VERSION "dbc-export 1 2025.20.8"

NS_ :

BS_:

BU_: ADSP APB APP APS APSB BB BMS CC CMP CMPD CP DAS DI DIF DIR DPB EPAS3P EPAS3S EPASTP EPASTS EPBL EPBR ESP EVSE FC GTW HCML HCMR HVP IBST ICR IDB LS OCS1P PARK PCS PM PMF PMR PNCD PTC RADC RCM RCM2 RCM3 RCU SCCM SCM SCS SDCR TAS TCU TPMS TRCM UI UIS UMC USM VC VCFRONT VCLEFT VCRIGHT VCSEC VEH

BO_ 886 DIF_temperature: 8 DIF
 SG_ DIF_tempIndex M : 0|3@1+ (1,0) [0|7] "" Vector__XXX
 SG_ DIF_inverterTQF m0 : 3|2@1+ (1,0) [0|3] "" Vector__XXX
 SG_ DIF_pcbT m0 : 8|8@1+ (1,-40) [-40|215] "DegC" Vector__XXX
 SG_ DIF_inverterT m0 : 16|8@1+ (1,-40) [-40|215] "DegC" Vector__XXX
 SG_ DIF_statorT m0 : 24|8@1+ (1,-40) [-40|215] "DegC" Vector__XXX
 SG_ DIF_dcCapT m0 : 32|8@1+ (1,-40) [-40|215] "DegC" Vector__XXX
 SG_ DIF_heatsinkT m0 : 40|8@1+ (1,-40) [-40|215] "DegC" Vector__XXX
 SG_ DIF_inverterTpct m0 : 48|8@1+ (0.4,0) [0|100] "%" Vector__XXX
 SG_ DIF_statorTpct m0 : 56|8@1+ (0.4,0) [0|100] "%" Vector__XXX
 SG_ DIF_fluidInTemp m2 : 8|8@1+ (1,-40) [-40|215] "DegC" Vector__XXX
 SG_ DIF_normalFetBurnIn m2 : 16|16@1+ (0.00763,0) [0|500] "Hours" Vector__XXX
 SG_ DIF_additionalFetBurnIn m2 : 32|16@1+ (0.00763,0) [0|500] "Hours" Vector__XXX
 SG_ DIF_currentWeibullMiles m3 : 3|16@1+ (8,0) [0|500000] "miles" Vector__XXX
 SG_ DIF_endOfServiceWeibullMiles m3 : 19|16@1+ (8,0) [0|500000] "miles" Vector__XXX
 SG_ DIF_burnInDamageRatio m3 : 35|9@1+ (0.01,0) [0|5] "1" Vector__XXX
 SG_ DIF_inverterSensorEst m3 : 44|8@1+ (1,-40) [-40|120] "C" Vector__XXX
 SG_ DIF_inverterHS1Est m3 : 52|8@1+ (1,-40) [-40|120] "C" Vector__XXX
 SG_ DIF_initialBurnInVehicleOdometer m4 : 8|32@1+ (0.001,0) [0|4294967.294] "km" Vector__XXX
 SG_ DIF_inverterHS2Est m4 : 40|8@1+ (1,-40) [-40|120] "C" Vector__XXX
 SG_ DIF_inverterInletEst m4 : 48|8@1+ (1,-40) [-40|120] "C" Vector__XXX

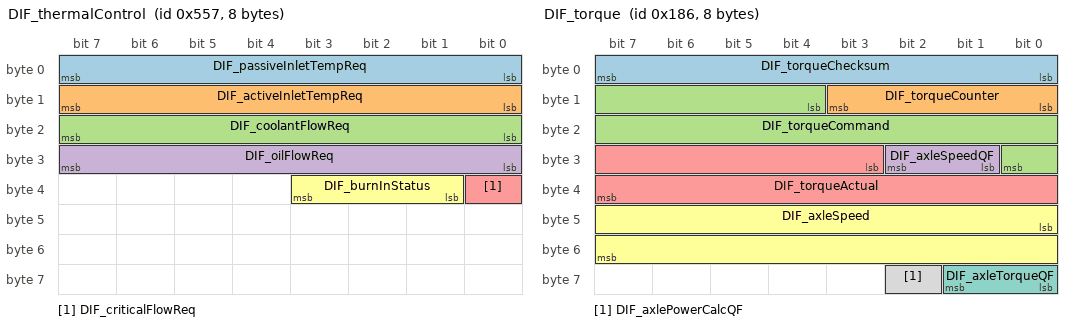
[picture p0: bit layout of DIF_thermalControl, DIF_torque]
BO_ 1367 DIF_thermalControl: 8 DIF
 SG_ DIF_passiveInletTempReq : 0|8@1+ (1,-40) [-40|215] "DegC" Vector__XXX
 SG_ DIF_activeInletTempReq : 8|8@1+ (1,-40) [-40|215] "DegC" Vector__XXX
 SG_ DIF_coolantFlowReq : 16|8@1+ (0.2,0) [0|50] "LPM" Vector__XXX
 SG_ DIF_oilFlowReq : 24|8@1+ (0.1,0) [0|25.4] "LPM" Vector__XXX
 SG_ DIF_criticalFlowReq : 32|1@1+ (1,0) [0|1] "" Vector__XXX
 SG_ DIF_burnInStatus : 33|3@1+ (1,0) [0|7] "" Vector__XXX

BO_ 390 DIF_torque: 8 DIF
 SG_ DIF_torqueChecksum : 0|8@1+ (1,0) [0|255] "" Vector__XXX
 SG_ DIF_torqueCounter : 8|4@1+ (1,0) [0|15] "" Vector__XXX
 SG_ DIF_torqueCommand : 12|13@1- (2,0) [-7500|7500] "Nm" Vector__XXX
 SG_ DIF_axleSpeedQF : 25|2@1+ (1,0) [0|3] "" Vector__XXX
 SG_ DIF_torqueActual : 27|13@1- (2,0) [-7500|7500] "Nm" Vector__XXX
 SG_ DIF_axleSpeed : 40|16@1- (0.1,0) [-2750|2750] "RPM" Vector__XXX
 SG_ DIF_axleTorqueQF : 56|2@1+ (1,0) [0|3] "" Vector__XXX
 SG_ DIF_axlePowerCalcQF : 58|1@1+ (1,0) [0|1] "" Vector__XXX

BO_ 1445 DIR_alertLog: 8 DIR
 SG_ DIR_alertID M : 0|8@1+ (1,0) [0|255] "" Vector__XXX
 SG_ DIR_alertState : 15|1@1+ (1,0) [0|1] "" Vector__XXX
 SG_ DIR_a001_thermalWarning_H m1 : 16|1@1+ (1,0) [0|1] "" Vector__XXX
 SG_ DIR_a001_thermalShutdown_H m1 : 17|1@1+ (1,0) [0|1] "" Vector__XXX
 SG_ DIR_a001_undervoltVL_H m1 : 18|1@1+ (1,0) [0|1] "" Vector__XXX
 SG_ DIR_a001_undervoltVH_H m1 : 19|1@1+ (1,0) [0|1] "" Vector__XXX
 SG_ DIR_a001_sense_H m1 : 20|1@1+ (1,0) [0|1] "" Vector__XXX
 SG_ DIR_a001_desat_H m1 : 21|1@1+ (1,0) [0|1] "" Vector__XXX
 SG_ DIR_a001_overvoltVL_H m1 : 22|1@1+ (1,0) [0|1] "" Vector__XXX
 SG_ DIR_a001_overvoltVH_H m1 : 23|1@1+ (1,0) [0|1] "" Vector__XXX
 SG_ DIR_a001_undervoltVCC_H m1 : 24|1@1+ (1,0) [0|1] "" Vector__XXX
 SG_ DIR_a001_asynchStop_H m1 : 25|1@1+ (1,0) [0|1] "" Vector__XXX
 SG_ DIR_a001_remoteRegError_H m1 : 26|1@1+ (1,0) [0|1] "" Vector__XXX
 SG_ DIR_a001_undervoltVDD_H m1 : 27|1@1+ (1,0) [0|1] "" Vector__XXX
 SG_ DIR_a001_overvoltVDD_H m1 : 28|1@1+ (1,0) [0|1] "" Vector__XXX
 SG_ DIR_a001_localRegError_H m1 : 29|1@1+ (1,0) [0|1] "" Vector__XXX
 SG_ DIR_a001_spiError_H m1 : 30|1@1+ (1,0) [0|1] "" Vector__XXX
 SG_ DIR_a001_deadtimeError_H m1 : 31|1@1+ (1,0) [0|1] "" Vector__XXX
 SG_ DIR_a001_thermalWarning_L m1 : 32|1@1+ (1,0) [0|1] "" Vector__XXX
 SG_ DIR_a001_thermalShutdown_L m1 : 33|1@1+ (1,0) [0|1] "" Vector__XXX
 SG_ DIR_a001_undervoltVL_L m1 : 34|1@1+ (1,0) [0|1] "" Vector__XXX
 SG_ DIR_a001_undervoltVH_L m1 : 35|1@1+ (1,0) [0|1] "" Vector__XXX
 SG_ DIR_a001_sense_L m1 : 36|1@1+ (1,0) [0|1] "" Vector__XXX
 SG_ DIR_a001_desat_L m1 : 37|1@1+ (1,0) [0|1] "" Vector__XXX
 SG_ DIR_a001_overvoltVL_L m1 : 38|1@1+ (1,0) [0|1] "" Vector__XXX
 SG_ DIR_a001_overvoltVH_L m1 : 39|1@1+ (1,0) [0|1] "" Vector__XXX
 SG_ DIR_a001_undervoltVCC_L m1 : 40|1@1+ (1,0) [0|1] "" Vector__XXX
 SG_ DIR_a001_asynchStop_L m1 : 41|1@1+ (1,0) [0|1] "" Vector__XXX
 SG_ DIR_a001_remoteRegError_L m1 : 42|1@1+ (1,0) [0|1] "" Vector__XXX
 SG_ DIR_a001_undervoltVDD_L m1 : 43|1@1+ (1,0) [0|1] "" Vector__XXX
 SG_ DIR_a001_overvoltVDD_L m1 : 44|1@1+ (1,0) [0|1] "" Vector__XXX
 SG_ DIR_a001_localRegError_L m1 : 45|1@1+ (1,0) [0|1] "" Vector__XXX
 SG_ DIR_a001_spiError_L m1 : 46|1@1+ (1,0) [0|1] "" Vector__XXX
 SG_ DIR_a001_deadtimeError_L m1 : 47|1@1+ (1,0) [0|1] "" Vector__XXX
 SG_ DIR_a001_gateDriveErrCounter m1 : 48|4@1+ (1,0) [0|15] "" Vector__XXX
 SG_ DIR_a001_remoteCommError_H m1 : 52|1@1+ (1,0) [0|1] "" Vector__XXX
 SG_ DIR_a001_localCommError_H m1 : 53|1@1+ (1,0) [0|1] "" Vector__XXX
 SG_ DIR_a001_remoteReset_H m1 : 54|1@1+ (1,0) [0|1] "" Vector__XXX
 SG_ DIR_a001_localReset_H m1 : 55|1@1+ (1,0) [0|1] "" Vector__XXX
 SG_ DIR_a001_remoteCommError_L m1 : 56|1@1+ (1,0) [0|1] "" Vector__XXX
 SG_ DIR_a001_localCommError_L m1 : 57|1@1+ (1,0) [0|1] "" Vector__XXX
 SG_ DIR_a001_remoteReset_L m1 : 58|1@1+ (1,0) [0|1] "" Vector__XXX
 SG_ DIR_a001_localReset_L m1 : 59|1@1+ (1,0) [0|1] "" Vector__XXX
 SG_ DIR_a001_faultLine1Gpio_H m1 : 60|1@1+ (1,0) [0|1] "" Vector__XXX
 SG_ DIR_a001_faultLine1Gpio_L m1 : 61|1@1+ (1,0) [0|1] "" Vector__XXX
 SG_ DIR_a002_thermalWarning_H m2 : 16|1@1+ (1,0) [0|1] "" Vector__XXX
 SG_ DIR_a002_thermalShutdown_H m2 : 17|1@1+ (1,0) [0|1] "" Vector__XXX
 SG_ DIR_a002_undervoltVL_H m2 : 18|1@1+ (1,0) [0|1] "" Vector__XXX
 SG_ DIR_a002_undervoltVH_H m2 : 19|1@1+ (1,0) [0|1] "" Vector__XXX
 SG_ DIR_a002_sense_H m2 : 20|1@1+ (1,0) [0|1] "" Vector__XXX
 SG_ DIR_a002_desat_H m2 : 21|1@1+ (1,0) [0|1] "" Vector__XXX
 SG_ DIR_a002_overvoltVL_H m2 : 22|1@1+ (1,0) [0|1] "" Vector__XXX
 SG_ DIR_a002_overvoltVH_H m2 : 23|1@1+ (1,0) [0|1] "" Vector__XXX
 SG_ DIR_a002_undervoltVCC_H m2 : 24|1@1+ (1,0) [0|1] "" Vector__XXX
 SG_ DIR_a002_asynchStop_H m2 : 25|1@1+ (1,0) [0|1] "" Vector__XXX
 SG_ DIR_a002_remoteRegError_H m2 : 26|1@1+ (1,0) [0|1] "" Vector__XXX
 SG_ DIR_a002_undervoltVDD_H m2 : 27|1@1+ (1,0) [0|1] "" Vector__XXX
 SG_ DIR_a002_overvoltVDD_H m2 : 28|1@1+ (1,0) [0|1] "" Vector__XXX
 SG_ DIR_a002_localRegError_H m2 : 29|1@1+ (1,0) [0|1] "" Vector__XXX
 SG_ DIR_a002_spiError_H m2 : 30|1@1+ (1,0) [0|1] "" Vector__XXX
 SG_ DIR_a002_deadtimeError_H m2 : 31|1@1+ (1,0) [0|1] "" Vector__XXX
 SG_ DIR_a002_thermalWarning_L m2 : 32|1@1+ (1,0) [0|1] "" Vector__XXX
 SG_ DIR_a002_thermalShutdown_L m2 : 33|1@1+ (1,0) [0|1] "" Vector__XXX
 SG_ DIR_a002_undervoltVL_L m2 : 34|1@1+ (1,0) [0|1] "" Vector__XXX
 SG_ DIR_a002_undervoltVH_L m2 : 35|1@1+ (1,0) [0|1] "" Vector__XXX
 SG_ DIR_a002_sense_L m2 : 36|1@1+ (1,0) [0|1] "" Vector__XXX
 SG_ DIR_a002_desat_L m2 : 37|1@1+ (1,0) [0|1] "" Vector__XXX
 SG_ DIR_a002_overvoltVL_L m2 : 38|1@1+ (1,0) [0|1] "" Vector__XXX
 SG_ DIR_a002_overvoltVH_L m2 : 39|1@1+ (1,0) [0|1] "" Vector__XXX
 SG_ DIR_a002_undervoltVCC_L m2 : 40|1@1+ (1,0) [0|1] "" Vector__XXX
 SG_ DIR_a002_asynchStop_L m2 : 41|1@1+ (1,0) [0|1] "" Vector__XXX
 SG_ DIR_a002_remoteRegError_L m2 : 42|1@1+ (1,0) [0|1] "" Vector__XXX
 SG_ DIR_a002_undervoltVDD_L m2 : 43|1@1+ (1,0) [0|1] "" Vector__XXX
 SG_ DIR_a002_overvoltVDD_L m2 : 44|1@1+ (1,0) [0|1] "" Vector__XXX
 SG_ DIR_a002_localRegError_L m2 : 45|1@1+ (1,0) [0|1] "" Vector__XXX
 SG_ DIR_a002_spiError_L m2 : 46|1@1+ (1,0) [0|1] "" Vector__XXX
 SG_ DIR_a002_deadtimeError_L m2 : 47|1@1+ (1,0) [0|1] "" Vector__XXX
 SG_ DIR_a002_gateDriveErrCounter m2 : 48|4@1+ (1,0) [0|15] "" Vector__XXX
 SG_ DIR_a002_selftestDesat_L m2 : 52|1@1+ (1,0) [0|1] "" Vector__XXX
 SG_ DIR_a002_selftestDesat_H m2 : 53|1@1+ (1,0) [0|1] "" Vector__XXX
 SG_ DIR_a002_remoteCommError_H m2 : 54|1@1+ (1,0) [0|1] "" Vector__XXX
 SG_ DIR_a002_localCommError_H m2 : 55|1@1+ (1,0) [0|1] "" Vector__XXX
 SG_ DIR_a002_remoteReset_H m2 : 56|1@1+ (1,0) [0|1] "" Vector__XXX
 SG_ DIR_a002_localReset_H m2 : 57|1@1+ (1,0) [0|1] "" Vector__XXX
 SG_ DIR_a002_remoteCommError_L m2 : 58|1@1+ (1,0) [0|1] "" Vector__XXX
 SG_ DIR_a002_localCommError_L m2 : 59|1@1+ (1,0) [0|1] "" Vector__XXX
 SG_ DIR_a002_remoteReset_L m2 : 60|1@1+ (1,0) [0|1] "" Vector__XXX
 SG_ DIR_a002_localReset_L m2 : 61|1@1+ (1,0) [0|1] "" Vector__XXX
 SG_ DIR_a002_faultLine1Gpio_H m2 : 62|1@1+ (1,0) [0|1] "" Vector__XXX
 SG_ DIR_a002_faultLine1Gpio_L m2 : 63|1@1+ (1,0) [0|1] "" Vector__XXX
 SG_ DIR_a003_thermalWarning_H m3 : 16|1@1+ (1,0) [0|1] "" Vector__XXX
 SG_ DIR_a003_thermalShutdown_H m3 : 17|1@1+ (1,0) [0|1] "" Vector__XXX
 SG_ DIR_a003_undervoltVL_H m3 : 18|1@1+ (1,0) [0|1] "" Vector__XXX
 SG_ DIR_a003_undervoltVH_H m3 : 19|1@1+ (1,0) [0|1] "" Vector__XXX
 SG_ DIR_a003_sense_H m3 : 20|1@1+ (1,0) [0|1] "" Vector__XXX
 SG_ DIR_a003_desat_H m3 : 21|1@1+ (1,0) [0|1] "" Vector__XXX
 SG_ DIR_a003_overvoltVL_H m3 : 22|1@1+ (1,0) [0|1] "" Vector__XXX
 SG_ DIR_a003_overvoltVH_H m3 : 23|1@1+ (1,0) [0|1] "" Vector__XXX
 SG_ DIR_a003_undervoltVCC_H m3 : 24|1@1+ (1,0) [0|1] "" Vector__XXX
 SG_ DIR_a003_asynchStop_H m3 : 25|1@1+ (1,0) [0|1] "" Vector__XXX
 SG_ DIR_a003_remoteRegError_H m3 : 26|1@1+ (1,0) [0|1] "" Vector__XXX
 SG_ DIR_a003_undervoltVDD_H m3 : 27|1@1+ (1,0) [0|1] "" Vector__XXX
 SG_ DIR_a003_overvoltVDD_H m3 : 28|1@1+ (1,0) [0|1] "" Vector__XXX
 SG_ DIR_a003_localRegError_H m3 : 29|1@1+ (1,0) [0|1] "" Vector__XXX
 SG_ DIR_a003_spiError_H m3 : 30|1@1+ (1,0) [0|1] "" Vector__XXX
 SG_ DIR_a003_deadtimeError_H m3 : 31|1@1+ (1,0) [0|1] "" Vector__XXX
 SG_ DIR_a003_thermalWarning_L m3 : 32|1@1+ (1,0) [0|1] "" Vector__XXX
 SG_ DIR_a003_thermalShutdown_L m3 : 33|1@1+ (1,0) [0|1] "" Vector__XXX
 SG_ DIR_a003_undervoltVL_L m3 : 34|1@1+ (1,0) [0|1] "" Vector__XXX
 SG_ DIR_a003_undervoltVH_L m3 : 35|1@1+ (1,0) [0|1] "" Vector__XXX
 SG_ DIR_a003_sense_L m3 : 36|1@1+ (1,0) [0|1] "" Vector__XXX
 SG_ DIR_a003_desat_L m3 : 37|1@1+ (1,0) [0|1] "" Vector__XXX
 SG_ DIR_a003_overvoltVL_L m3 : 38|1@1+ (1,0) [0|1] "" Vector__XXX
 SG_ DIR_a003_overvoltVH_L m3 : 39|1@1+ (1,0) [0|1] "" Vector__XXX
 SG_ DIR_a003_undervoltVCC_L m3 : 40|1@1+ (1,0) [0|1] "" Vector__XXX
 SG_ DIR_a003_asynchStop_L m3 : 41|1@1+ (1,0) [0|1] "" Vector__XXX
 SG_ DIR_a003_remoteRegError_L m3 : 42|1@1+ (1,0) [0|1] "" Vector__XXX
 SG_ DIR_a003_undervoltVDD_L m3 : 43|1@1+ (1,0) [0|1] "" Vector__XXX
 SG_ DIR_a003_overvoltVDD_L m3 : 44|1@1+ (1,0) [0|1] "" Vector__XXX
 SG_ DIR_a003_localRegError_L m3 : 45|1@1+ (1,0) [0|1] "" Vector__XXX
 SG_ DIR_a003_spiError_L m3 : 46|1@1+ (1,0) [0|1] "" Vector__XXX
 SG_ DIR_a003_deadtimeError_L m3 : 47|1@1+ (1,0) [0|1] "" Vector__XXX
 SG_ DIR_a003_gateDriveErrCounter m3 : 48|4@1+ (1,0) [0|15] "" Vector__XXX
 SG_ DIR_a003_selftestDesat_L m3 : 52|1@1+ (1,0) [0|1] "" Vector__XXX
 SG_ DIR_a003_selftestDesat_H m3 : 53|1@1+ (1,0) [0|1] "" Vector__XXX
 SG_ DIR_a003_remoteCommError_H m3 : 54|1@1+ (1,0) [0|1] "" Vector__XXX
 SG_ DIR_a003_localCommError_H m3 : 55|1@1+ (1,0) [0|1] "" Vector__XXX
 SG_ DIR_a003_remoteReset_H m3 : 56|1@1+ (1,0) [0|1] "" Vector__XXX
 SG_ DIR_a003_localReset_H m3 : 57|1@1+ (1,0) [0|1] "" Vector__XXX
 SG_ DIR_a003_remoteCommError_L m3 : 58|1@1+ (1,0) [0|1] "" Vector__XXX
 SG_ DIR_a003_localCommError_L m3 : 59|1@1+ (1,0) [0|1] "" Vector__XXX
 SG_ DIR_a003_remoteReset_L m3 : 60|1@1+ (1,0) [0|1] "" Vector__XXX
 SG_ DIR_a003_localReset_L m3 : 61|1@1+ (1,0) [0|1] "" Vector__XXX
 SG_ DIR_a003_faultLine1Gpio_H m3 : 62|1@1+ (1,0) [0|1] "" Vector__XXX
 SG_ DIR_a003_faultLine1Gpio_L m3 : 63|1@1+ (1,0) [0|1] "" Vector__XXX
 SG_ DIR_a007_phaseAcurrent m7 : 16|8@1+ (8,0) [0|2040] "" Vector__XXX
 SG_ DIR_a007_phaseBcurrent m7 : 24|8@1+ (8,0) [0|2040] "" Vector__XXX
 SG_ DIR_a007_offsetError m7 : 32|14@1- (0.0003834952,0) [-3.1415926784|3.1412091832] "" Vector__XXX
 SG_ DIR_a007_idFdbStdDeviation m7 : 46|8@1+ (4,0) [0|1020] "" Vector__XXX
 SG_ DIR_a007_iqFdbStdDeviation m7 : 54|8@1+ (4,0) [0|1020] "" Vector__XXX
 SG_ DIR_a007_motorShift m7 : 62|1@1+ (1,0) [0|1] "" Vector__XXX
 SG_ DIR_a007_motorShort m7 : 63|1@1+ (1,0) [0|1] "" Vector__XXX
 SG_ DIR_a010_sccReset m10 : 16|1@1+ (1,0) [0|1] "" Vector__XXX
 SG_ DIR_a010_hibernate m10 : 17|1@1+ (1,0) [0|1] "" Vector__XXX
 SG_ DIR_a010_hwBist m10 : 18|1@1+ (1,0) [0|1] "" Vector__XXX
 SG_ DIR_a010_nmiWatchdog m10 : 19|1@1+ (1,0) [0|1] "" Vector__XXX
 SG_ DIR_a010_watchdog m10 : 20|1@1+ (1,0) [0|1] "" Vector__XXX
 SG_ DIR_a010_clockFailNmi m10 : 21|1@1+ (1,0) [0|1] "" Vector__XXX
 SG_ DIR_a010_ramUncErrorNmi m10 : 22|1@1+ (1,0) [0|1] "" Vector__XXX
 SG_ DIR_a010_flashUncErrorNmi m10 : 23|1@1+ (1,0) [0|1] "" Vector__XXX
 SG_ DIR_a010_cpu1signMismatchNmi m10 : 24|1@1+ (1,0) [0|1] "" Vector__XXX
 SG_ DIR_a010_cpu2signMismatchNmi m10 : 25|1@1+ (1,0) [0|1] "" Vector__XXX
 SG_ DIR_a010_pieVectErrorNmi m10 : 26|1@1+ (1,0) [0|1] "" Vector__XXX
 SG_ DIR_a010_sysDbgNmi m10 : 27|1@1+ (1,0) [0|1] "" Vector__XXX
 SG_ DIR_a010_rlNmi m10 : 28|1@1+ (1,0) [0|1] "" Vector__XXX
 SG_ DIR_a010_ovfNmi m10 : 29|1@1+ (1,0) [0|1] "" Vector__XXX
 SG_ DIR_a010_wdtFlags m10 : 32|16@1+ (1,0) [0|65535] "" Vector__XXX
 SG_ DIR_a011_reason m11 : 16|3@1+ (1,0) [0|7] "" Vector__XXX
 SG_ DIR_a011_phaseAHigh m11 : 19|1@1+ (1,0) [0|1] "" Vector__XXX
 SG_ DIR_a011_phaseALow m11 : 20|1@1+ (1,0) [0|1] "" Vector__XXX
 SG_ DIR_a011_phaseBHigh m11 : 21|1@1+ (1,0) [0|1] "" Vector__XXX
 SG_ DIR_a011_phaseBLow m11 : 22|1@1+ (1,0) [0|1] "" Vector__XXX
 SG_ DIR_a011_phaseCHigh m11 : 23|1@1+ (1,0) [0|1] "" Vector__XXX
 SG_ DIR_a011_phaseCLow m11 : 24|1@1+ (1,0) [0|1] "" Vector__XXX
 SG_ DIR_a011_regAddress m11 : 25|5@1+ (1,0) [0|31] "" Vector__XXX
 SG_ DIR_a011_badGateDriveIC m11 : 32|3@1+ (1,0) [0|7] "" Vector__XXX
 SG_ DIR_a011_badDataRead m11 : 40|8@1+ (1,0) [0|255] "" Vector__XXX
 SG_ DIR_a011_badDataExpected m11 : 48|8@1+ (1,0) [0|255] "" Vector__XXX
 SG_ DIR_a011_codeBranch m11 : 56|4@1+ (1,0) [0|15] "" Vector__XXX
 SG_ DIR_a012_hvilStatus m12 : 16|2@1+ (1,0) [0|3] "" Vector__XXX
 SG_ DIR_a012_hvilCmVoltage m12 : 24|8@1+ (0.08,0) [0|20.4] "" Vector__XXX
 SG_ DIR_a012_hvilCurrent m12 : 32|8@1+ (0.1,0) [0|25.5] "" Vector__XXX
 SG_ DIR_a012_hvilFaultGpio m12 : 40|1@1+ (1,0) [0|1] "" Vector__XXX
 SG_ DIR_a012_hvilSupplyPinDI m12 : 41|1@1+ (1,0) [0|1] "" Vector__XXX
 SG_ DIR_a012_hvilSupplyPinPM m12 : 42|1@1+ (1,0) [0|1] "" Vector__XXX
 SG_ DIR_a012_activeDisOn3V3 m12 : 43|1@1+ (1,0) [0|1] "" Vector__XXX
 SG_ DIR_a012_hvilHeaderFault m12 : 44|1@1+ (1,0) [0|1] "" Vector__XXX
 SG_ DIR_a013_address m13 : 16|32@1+ (1,0) [0|4294967295] "" Vector__XXX
 SG_ DIR_a013_errorType m13 : 48|4@1+ (1,0) [0|15] "" Vector__XXX
 SG_ DIR_a014_motorSpeed m14 : 16|14@1- (2,0) [-16384|16382] "" Vector__XXX
 SG_ DIR_a014_adState m14 : 30|2@1+ (1,0) [0|3] "" Vector__XXX
 SG_ DIR_a014_torqueCommandFwd m14 : 32|10@1- (2,0) [-1024|1022] "" Vector__XXX
 SG_ DIR_a014_brakeMasterCylPress m14 : 42|10@1+ (0.25,-42.5) [-42.5|213.25] "" Vector__XXX
 SG_ DIR_a014_rmsTorqueError m14 : 52|10@1+ (1,0) [0|1023] "" Vector__XXX
 SG_ DIR_a014_tcEnabled m14 : 62|1@1+ (1,0) [0|1] "" Vector__XXX
 SG_ DIR_a016_newSafeState m16 : 16|2@1+ (1,0) [0|3] "" Vector__XXX
 SG_ DIR_a016_oldSafeState m16 : 18|2@1+ (1,0) [0|3] "" Vector__XXX
 SG_ DIR_a016_gateDriveFaultLine m16 : 20|1@1+ (1,0) [0|1] "" Vector__XXX
 SG_ DIR_a016_ascMonitor m16 : 21|1@1+ (1,0) [0|1] "" Vector__XXX
 SG_ DIR_a016_uncontrolledRegenZone m16 : 22|1@1+ (1,0) [0|1] "" Vector__XXX
 SG_ DIR_a016_pedalMonitorPreWatchdog m16 : 23|1@1+ (1,0) [0|1] "" Vector__XXX
 SG_ DIR_a016_motorRPM m16 : 24|16@1- (1,0) [-32768|32767] "" Vector__XXX
 SG_ DIR_a016_torqueMotor m16 : 40|16@1- (1,0) [-32768|32767] "" Vector__XXX
 SG_ DIR_a016_safetyICfaultLine m16 : 56|1@1+ (1,0) [0|1] "" Vector__XXX
 SG_ DIR_a016_triggerEvent m16 : 57|5@1+ (1,0) [0|31] "" Vector__XXX
 SG_ DIR_a024_vBat m24 : 16|8@1+ (2,0) [0|510] "" Vector__XXX
 SG_ DIR_a024_failReason m24 : 24|3@1+ (1,0) [0|7] "" Vector__XXX
 SG_ DIR_a024_state m24 : 27|4@1+ (1,0) [0|15] "" Vector__XXX
 SG_ DIR_a024_Ia m24 : 31|7@1- (22.5,0) [-1440|1417.5] "" Vector__XXX
 SG_ DIR_a024_Ib m24 : 38|7@1- (22.5,0) [-1440|1417.5] "" Vector__XXX
 SG_ DIR_a024_maxCurrMagSqrd m24 : 45|12@1+ (500,0) [0|2047500] "" Vector__XXX
 SG_ DIR_a024_rotorAngle m24 : 57|7@1- (3,0) [-192|189] "" Vector__XXX
 SG_ DIR_a025_Ia m25 : 16|16@1- (0.1,0) [-3276.8|3276.7] "" Vector__XXX
 SG_ DIR_a025_torqueMotor m25 : 32|13@1- (0.25,0) [-1024|1023.75] "" Vector__XXX
 SG_ DIR_a025_motorSpeed m25 : 48|16@1- (1,0) [-32768|32767] "" Vector__XXX
 SG_ DIR_a026_Ib m26 : 16|16@1- (0.1,0) [-3276.8|3276.7] "" Vector__XXX
 SG_ DIR_a026_torqueMotor m26 : 32|13@1- (0.25,0) [-1024|1023.75] "" Vector__XXX
 SG_ DIR_a026_motorSpeed m26 : 48|16@1- (1,0) [-32768|32767] "" Vector__XXX
 SG_ DIR_a027_Ic m27 : 16|16@1- (0.1,0) [-3276.8|3276.7] "" Vector__XXX
 SG_ DIR_a027_torqueMotor m27 : 32|13@1- (0.25,0) [-1024|1023.75] "" Vector__XXX
 SG_ DIR_a027_motorSpeed m27 : 48|16@1- (1,0) [-32768|32767] "" Vector__XXX
 SG_ DIR_a028_phaseAirms m28 : 16|16@1+ (1,0) [0|65535] "" Vector__XXX
 SG_ DIR_a028_iArmsTorque m28 : 32|16@1+ (0.25,0) [0|16383.75] "" Vector__XXX
 SG_ DIR_a028_iArmsSpeed m28 : 48|16@1+ (1,0) [0|65535] "" Vector__XXX
 SG_ DIR_a029_phaseBirms m29 : 16|16@1+ (1,0) [0|65535] "" Vector__XXX
 SG_ DIR_a029_iBrmsTorque m29 : 32|16@1+ (0.25,0) [0|16383.75] "" Vector__XXX
 SG_ DIR_a029_iBrmsSpeed m29 : 48|16@1+ (1,0) [0|65535] "" Vector__XXX
 SG_ DIR_a030_phaseCirms m30 : 16|16@1+ (1,0) [0|65535] "" Vector__XXX
 SG_ DIR_a030_iCrmsTorque m30 : 32|16@1+ (0.25,0) [0|16383.75] "" Vector__XXX
 SG_ DIR_a030_iCrmsSpeed m30 : 48|16@1+ (1,0) [0|65535] "" Vector__XXX
 SG_ DIR_a031_phaseAoffset m31 : 16|16@1- (0.002,0) [-65.536|65.534] "" Vector__XXX
 SG_ DIR_a032_phaseBoffset m32 : 16|16@1- (0.002,0) [-65.536|65.534] "" Vector__XXX
 SG_ DIR_a033_phaseAcurrent m33 : 16|16@1- (1,0) [-32768|32767] "" Vector__XXX
 SG_ DIR_a033_deltaIa m33 : 32|16@1- (1,0) [-32768|32767] "" Vector__XXX
 SG_ DIR_a033_vRefIa m33 : 48|16@1- (0.001,0) [-32.768|32.767] "" Vector__XXX
 SG_ DIR_a034_phaseBcurrent m34 : 16|16@1- (1,0) [-32768|32767] "" Vector__XXX
 SG_ DIR_a034_deltaIb m34 : 32|16@1- (1,0) [-32768|32767] "" Vector__XXX
 SG_ DIR_a034_vRefIb m34 : 48|16@1- (0.001,0) [-32.768|32.767] "" Vector__XXX
 SG_ DIR_a035_phaseAerror m35 : 16|1@1+ (1,0) [0|1] "" Vector__XXX
 SG_ DIR_a035_phaseBerror m35 : 17|1@1+ (1,0) [0|1] "" Vector__XXX
 SG_ DIR_a035_phaseCerror m35 : 18|1@1+ (1,0) [0|1] "" Vector__XXX
 SG_ DIR_a035_standbyCurrent m35 : 19|1@1+ (1,0) [0|1] "" Vector__XXX
 SG_ DIR_a035_unbalancedCurrent m35 : 20|1@1+ (1,0) [0|1] "" Vector__XXX
 SG_ DIR_a035_wontMoveCurrent m35 : 21|1@1+ (1,0) [0|1] "" Vector__XXX
 SG_ DIR_a035_reportingPhase m35 : 22|2@1+ (1,0) [0|3] "" Vector__XXX
 SG_ DIR_a035_noDriveCurrent m35 : 24|1@1+ (1,0) [0|1] "" Vector__XXX
 SG_ DIR_a035_phaseDifference m35 : 25|7@1+ (1,0) [0|127] "" Vector__XXX
 SG_ DIR_a035_phaseCurrent m35 : 32|16@1+ (1,0) [0|65535] "" Vector__XXX
 SG_ DIR_a035_frequency m35 : 48|10@1+ (1,0) [0|1023] "" Vector__XXX
 SG_ DIR_a036_busVoltage m36 : 16|16@1+ (0.1,0) [0|6553.5] "" Vector__XXX
 SG_ DIR_a036_busHighLimit m36 : 32|16@1+ (0.1,0) [0|6553.5] "" Vector__XXX
 SG_ DIR_a037_busVoltage m37 : 16|16@1+ (0.1,0) [0|6553.5] "" Vector__XXX
 SG_ DIR_a037_busLowLimit m37 : 32|16@1+ (0.1,0) [0|6553.5] "" Vector__XXX
 SG_ DIR_a038_vBMS m38 : 16|13@1+ (0.2,0) [0|1638.2] "" Vector__XXX
 SG_ DIR_a038_vBat m38 : 32|13@1+ (0.2,0) [0|1638.2] "" Vector__XXX
 SG_ DIR_a038_iBat m38 : 48|13@1+ (0.5,0) [0|4095.5] "" Vector__XXX
 SG_ DIR_a038_reason m38 : 61|2@1+ (1,0) [0|3] "" Vector__XXX
 SG_ DIR_a040_torque m40 : 16|1@1+ (1,0) [0|1] "" Vector__XXX
 SG_ DIR_a040_capability m40 : 17|1@1+ (1,0) [0|1] "" Vector__XXX
 SG_ DIR_a040_power m40 : 18|1@1+ (1,0) [0|1] "" Vector__XXX
 SG_ DIR_a040_status m40 : 19|1@1+ (1,0) [0|1] "" Vector__XXX
 SG_ DIR_a040_capability2 m40 : 20|1@1+ (1,0) [0|1] "" Vector__XXX
 SG_ DIR_a040_hvStatus m40 : 21|1@1+ (1,0) [0|1] "" Vector__XXX
 SG_ DIR_a040_temperature m40 : 22|1@1+ (1,0) [0|1] "" Vector__XXX
 SG_ DIR_a041_uartRxDataAvailable m41 : 16|1@1+ (1,0) [0|1] "" Vector__XXX
 SG_ DIR_a041_SDC_status_MIA m41 : 17|1@1+ (1,0) [0|1] "" Vector__XXX
 SG_ DIR_a041_diUartRxVersion m41 : 18|4@1+ (1,0) [0|15] "" Vector__XXX
 SG_ DIR_a041_sdcUartRxVersion m41 : 24|4@1+ (1,0) [0|15] "" Vector__XXX
 SG_ DIR_a043_outletTemp m43 : 16|16@1- (0.1,0) [-3276.8|3276.7] "" Vector__XXX
 SG_ DIR_a044_outletTemp m44 : 16|16@1- (0.1,0) [-3276.8|3276.7] "" Vector__XXX
 SG_ DIR_a045_inletTemp m45 : 16|10@1+ (0.25,-60) [-60|195.75] "" Vector__XXX
 SG_ DIR_a045_outletTemp m45 : 26|10@1+ (0.25,-60) [-60|195.75] "" Vector__XXX
 SG_ DIR_a045_heatsinkTemp m45 : 36|10@1+ (0.25,-60) [-60|195.75] "" Vector__XXX
 SG_ DIR_a045_outletTempSlope m45 : 48|8@1- (0.5,0) [-64|63.5] "" Vector__XXX
 SG_ DIR_a046_statorTemp1 m46 : 16|16@1- (0.1,0) [-3276.8|3276.7] "" Vector__XXX
 SG_ DIR_a046_statorTemp2 m46 : 32|16@1- (0.1,0) [-3276.8|3276.7] "" Vector__XXX
 SG_ DIR_a047_statorTemp1 m47 : 16|16@1- (0.1,0) [-3276.8|3276.7] "" Vector__XXX
 SG_ DIR_a047_statorTslope1 m47 : 32|16@1- (0.1,0) [-3276.8|3276.7] "" Vector__XXX
 SG_ DIR_a050_statorTemp1 m50 : 16|16@1- (0.1,0) [-3276.8|3276.7] "" Vector__XXX
 SG_ DIR_a050_statorTemp2 m50 : 32|16@1- (0.1,0) [-3276.8|3276.7] "" Vector__XXX
 SG_ DIR_a052_torque m52 : 16|1@1+ (1,0) [0|1] "" Vector__XXX
 SG_ DIR_a052_capability m52 : 17|1@1+ (1,0) [0|1] "" Vector__XXX
 SG_ DIR_a052_power m52 : 18|1@1+ (1,0) [0|1] "" Vector__XXX
 SG_ DIR_a052_status m52 : 19|1@1+ (1,0) [0|1] "" Vector__XXX
 SG_ DIR_a052_capability2 m52 : 20|1@1+ (1,0) [0|1] "" Vector__XXX
 SG_ DIR_a052_hvStatus m52 : 21|1@1+ (1,0) [0|1] "" Vector__XXX
 SG_ DIR_a052_temperature m52 : 22|1@1+ (1,0) [0|1] "" Vector__XXX
 SG_ DIR_a054_outletTemp m54 : 16|16@1- (0.1,0) [-3276.8|3276.7] "" Vector__XXX
 SG_ DIR_a054_heatsinkTemp m54 : 32|16@1- (0.1,0) [-3276.8|3276.7] "" Vector__XXX
 SG_ DIR_a055_parameterDI m55 : 16|13@1- (0.25,0) [-1024|1023.75] "" Vector__XXX
 SG_ DIR_a055_parameterPM m55 : 32|13@1- (0.25,0) [-1024|1023.75] "" Vector__XXX
 SG_ DIR_a055_torqueType m55 : 45|2@1+ (1,0) [0|3] "" Vector__XXX
 SG_ DIR_a055_motorRPM m55 : 48|16@1- (1,0) [-32768|32767] "" Vector__XXX
 SG_ DIR_a056_pcbTemp m56 : 16|16@1- (0.1,0) [-3276.8|3276.7] "" Vector__XXX
 SG_ DIR_a057_pcbTemp m57 : 16|16@1- (0.1,0) [-3276.8|3276.7] "" Vector__XXX
 SG_ DIR_a058_pcbTemp m58 : 16|10@1+ (0.25,-60) [-60|195.75] "" Vector__XXX
 SG_ DIR_a058_outletTemp m58 : 26|10@1+ (0.25,-60) [-60|195.75] "" Vector__XXX
 SG_ DIR_a058_heatsinkTemp m58 : 36|10@1+ (0.25,-60) [-60|195.75] "" Vector__XXX
 SG_ DIR_a058_pcbTempSlope m58 : 48|8@1- (0.5,0) [-64|63.5] "" Vector__XXX
 SG_ DIR_a059_heatsinkTemp m59 : 16|16@1- (0.1,0) [-3276.8|3276.7] "" Vector__XXX
 SG_ DIR_a060_heatsinkTemp m60 : 16|16@1- (0.1,0) [-3276.8|3276.7] "" Vector__XXX
 SG_ DIR_a061_sensor m61 : 16|2@1+ (1,0) [0|3] "" Vector__XXX
 SG_ DIR_a061_reason m61 : 18|1@1+ (1,0) [0|1] "" Vector__XXX
 SG_ DIR_a061_phTemp m61 : 24|16@1- (0.1,0) [-3276.8|3276.7] "" Vector__XXX
 SG_ DIR_a061_otherTemp m61 : 40|16@1- (0.1,0) [-3276.8|3276.7] "" Vector__XXX
 SG_ DIR_a062_limpReason m62 : 16|6@1+ (1,0) [0|63] "" Vector__XXX
 SG_ DIR_a063_BB_status m63 : 16|1@1+ (1,0) [0|1] "" Vector__XXX
 SG_ DIR_a064_interventionType m64 : 16|4@1+ (1,0) [0|15] "" Vector__XXX
 SG_ DIR_a064_torqueCmdState m64 : 20|4@1+ (1,0) [0|15] "" Vector__XXX
 SG_ DIR_a066_badValue1 m66 : 16|16@1+ (1,0) [0|65535] "" Vector__XXX
 SG_ DIR_a066_badValue2 m66 : 32|16@1+ (1,0) [0|65535] "" Vector__XXX
 SG_ DIR_a066_canID m66 : 48|12@1+ (1,0) [0|4095] "" Vector__XXX
 SG_ DIR_a066_errorType m66 : 60|3@1+ (1,0) [0|7] "" Vector__XXX
 SG_ DIR_a069_motorSpeed m69 : 16|16@1- (1,0) [-32768|32767] "" Vector__XXX
 SG_ DIR_a069_rotorCoolingPower m69 : 32|8@1+ (20,0) [0|5100] "" Vector__XXX
 SG_ DIR_a069_rotorMagnetTemp m69 : 40|10@1+ (0.25,-60) [-60|195.75] "" Vector__XXX
 SG_ DIR_a069_fittedTorqueLimit m69 : 50|13@1- (0.25,0) [-1024|1023.75] "" Vector__XXX
 SG_ DIR_a072_reason m72 : 16|2@1+ (1,0) [0|3] "" Vector__XXX
 SG_ DIR_a073_motorSpeedrpm m73 : 16|16@1- (1,0) [-32768|32767] "" Vector__XXX
 SG_ DIR_a075_motorSpeed m75 : 16|16@1+ (1,0) [0|65535] "" Vector__XXX
 SG_ DIR_a075_absSpeed m75 : 32|16@1+ (1,0) [0|65535] "" Vector__XXX
 SG_ DIR_a076_lvSupplyV m76 : 16|16@1+ (0.001,0) [0|65.535] "" Vector__XXX
 SG_ DIR_a077_lvSupplyV m77 : 16|16@1+ (0.001,0) [0|65.535] "" Vector__XXX
 SG_ DIR_a078_adcRefChan m78 : 16|4@1+ (1,0) [0|15] "" Vector__XXX
 SG_ DIR_a078_adcRefLowAvg m78 : 24|16@1+ (1,0) [0|65535] "" Vector__XXX
 SG_ DIR_a079_adcRefChan m79 : 16|4@1+ (1,0) [0|15] "" Vector__XXX
 SG_ DIR_a079_adcRefHighAvg m79 : 24|16@1+ (1,0) [0|65535] "" Vector__XXX
 SG_ DIR_a087_gtwCarConfig m87 : 16|1@1+ (1,0) [0|1] "" Vector__XXX
 SG_ DIR_a087_gtwTime m87 : 17|1@1+ (1,0) [0|1] "" Vector__XXX
 SG_ DIR_a087_gtwUpdateStatus m87 : 18|1@1+ (1,0) [0|1] "" Vector__XXX
 SG_ DIR_a087_gearControl m87 : 19|1@1+ (1,0) [0|1] "" Vector__XXX
 SG_ DIR_a087_carState m87 : 20|1@1+ (1,0) [0|1] "" Vector__XXX
 SG_ DIR_a090_reason m90 : 16|1@1+ (1,0) [0|1] "" Vector__XXX
 SG_ DIR_a090_systemState m90 : 17|1@1+ (1,0) [0|1] "" Vector__XXX
 SG_ DIR_a090_state m90 : 18|1@1+ (1,0) [0|1] "" Vector__XXX
 SG_ DIR_a090_locState m90 : 19|1@1+ (1,0) [0|1] "" Vector__XXX
 SG_ DIR_a090_state2 m90 : 20|1@1+ (1,0) [0|1] "" Vector__XXX
 SG_ DIR_a090_state4 m90 : 21|1@1+ (1,0) [0|1] "" Vector__XXX
 SG_ DIR_a091_ESP_brakeTorque m91 : 16|1@1+ (1,0) [0|1] "" Vector__XXX
 SG_ DIR_a091_ESP_wheelSpeeds m91 : 17|1@1+ (1,0) [0|1] "" Vector__XXX
 SG_ DIR_a091_ESP_wheelRotation m91 : 18|1@1+ (1,0) [0|1] "" Vector__XXX
 SG_ DIR_a091_ESP_motorLimits m91 : 19|1@1+ (1,0) [0|1] "" Vector__XXX
 SG_ DIR_a091_ESP_offsets m91 : 20|1@1+ (1,0) [0|1] "" Vector__XXX
 SG_ DIR_a091_ESP_status m91 : 21|1@1+ (1,0) [0|1] "" Vector__XXX
 SG_ DIR_a091_ESP_party3 m91 : 22|1@1+ (1,0) [0|1] "" Vector__XXX
 SG_ DIR_a092_bmsStatus m92 : 16|1@1+ (1,0) [0|1] "" Vector__XXX
 SG_ DIR_a092_bmsDriveLimits m92 : 17|1@1+ (1,0) [0|1] "" Vector__XXX
 SG_ DIR_a092_bmsHvBusStatus m92 : 18|1@1+ (1,0) [0|1] "" Vector__XXX
 SG_ DIR_a092_bmsPowerAvailable m92 : 19|1@1+ (1,0) [0|1] "" Vector__XXX
 SG_ DIR_a092_bmsBmbMinMax m92 : 20|1@1+ (1,0) [0|1] "" Vector__XXX
 SG_ DIR_a092_bmsSocStatus m92 : 21|1@1+ (1,0) [0|1] "" Vector__XXX
 SG_ DIR_a092_bmsThermalStatus m92 : 22|1@1+ (1,0) [0|1] "" Vector__XXX
 SG_ DIR_a092_bmsCtrStatus m92 : 23|1@1+ (1,0) [0|1] "" Vector__XXX
 SG_ DIR_a092_bmsVoltageRegGain m92 : 24|1@1+ (1,0) [0|1] "" Vector__XXX
 SG_ DIR_a092_bmsPackConfig m92 : 25|1@1+ (1,0) [0|1] "" Vector__XXX
 SG_ DIR_a092_bmsSystemStatus m92 : 26|1@1+ (1,0) [0|1] "" Vector__XXX
 SG_ DIR_a094_canID m94 : 16|12@1+ (1,0) [0|4095] "" Vector__XXX
 SG_ DIR_a094_errorType m94 : 28|3@1+ (1,0) [0|7] "" Vector__XXX
 SG_ DIR_a094_badValue1 m94 : 32|16@1+ (1,0) [0|65535] "" Vector__XXX
 SG_ DIR_a094_badValue2 m94 : 48|16@1+ (1,0) [0|65535] "" Vector__XXX
 SG_ DIR_a096_const_fast m96 : 16|1@1+ (1,0) [0|1] "" Vector__XXX
 SG_ DIR_a096_text_fast m96 : 17|1@1+ (1,0) [0|1] "" Vector__XXX
 SG_ DIR_a096_text_flash m96 : 18|1@1+ (1,0) [0|1] "" Vector__XXX
 SG_ DIR_a096_mem_data m96 : 19|1@1+ (1,0) [0|1] "" Vector__XXX
 SG_ DIR_a096_mem_regs m96 : 20|1@1+ (1,0) [0|1] "" Vector__XXX
 SG_ DIR_a096_boot_flash m96 : 21|1@1+ (1,0) [0|1] "" Vector__XXX
 SG_ DIR_a096_word1 m96 : 24|16@1+ (1,0) [0|65535] "" Vector__XXX
 SG_ DIR_a096_word2 m96 : 40|16@1+ (1,0) [0|65535] "" Vector__XXX
 SG_ DIR_a097_errorType m97 : 16|3@1+ (1,0) [0|7] "" Vector__XXX
 SG_ DIR_a097_lineNumber m97 : 24|16@1+ (1,0) [0|65535] "" Vector__XXX
 SG_ DIR_a097_argument m97 : 40|16@1+ (1,0) [0|65535] "" Vector__XXX
 SG_ DIR_a098_pwmCount m98 : 16|16@1+ (1,0) [0|65535] "" Vector__XXX
 SG_ DIR_a098_fluxState m98 : 32|4@1+ (1,0) [0|15] "" Vector__XXX
 SG_ DIR_a103_fluidTorDeltaT m103 : 16|8@1- (2.007874,68.2677154541) [-188.740156546|323.267713454] "" Vector__XXX
 SG_ DIR_a103_noFlowDetected m103 : 24|1@1+ (1,0) [0|1] "" Vector__XXX
 SG_ DIR_a103_lowFlowDetected m103 : 25|1@1+ (1,0) [0|1] "" Vector__XXX
 SG_ DIR_a103_fluidImplausible m103 : 26|1@1+ (1,0) [0|1] "" Vector__XXX
 SG_ DIR_a103_inverterTemp m103 : 27|8@1- (2.007874,68.2677154541) [-188.740156546|323.267713454] "" Vector__XXX
 SG_ DIR_a103_rmsCurrent m103 : 35|10@1- (12.8199605942,0) [-6563.81982423|6550.99986364] "" Vector__XXX
 SG_ DIR_a103_ambientTemp m103 : 45|7@1- (1.5873016119,11.1111106873) [-90.4761924743|111.111112237] "" Vector__XXX
 SG_ DIR_a103_sensorTempEst m103 : 52|8@1- (1.25984251499,40.31496) [-120.944881919|200.314959404] "" Vector__XXX
 SG_ DIR_a107_fpgaVersion m107 : 16|16@1+ (1,0) [0|65535] "" Vector__XXX
 SG_ DIR_a107_fpgaBootVersion m107 : 32|16@1+ (1,0) [0|65535] "" Vector__XXX
 SG_ DIR_a107_fpgaMasterActive m107 : 48|1@1+ (1,0) [0|1] "" Vector__XXX
 SG_ DIR_a107_fpgaFaultActive m107 : 49|1@1+ (1,0) [0|1] "" Vector__XXX
 SG_ DIR_a107_fpgaWarningActive m107 : 50|1@1+ (1,0) [0|1] "" Vector__XXX
 SG_ DIR_a108_fromState m108 : 16|8@1+ (1,0) [0|255] "" Vector__XXX
 SG_ DIR_a108_toState m108 : 24|8@1+ (1,0) [0|255] "" Vector__XXX
 SG_ DIR_a108_blockingAlert m108 : 32|8@1+ (1,0) [0|255] "" Vector__XXX
 SG_ DIR_a110_EPBL_status m110 : 16|1@1+ (1,0) [0|1] "" Vector__XXX
 SG_ DIR_a110_EPBR_status m110 : 17|1@1+ (1,0) [0|1] "" Vector__XXX
 SG_ DIR_a111_phAcalib m111 : 16|16@1+ (1,0) [0|65535] "" Vector__XXX
 SG_ DIR_a111_phBcalib m111 : 32|16@1+ (1,0) [0|65535] "" Vector__XXX
 SG_ DIR_a112_phaseAcurrent m112 : 16|16@1+ (1,0) [0|65535] "" Vector__XXX
 SG_ DIR_a112_phaseBcurrent m112 : 32|16@1+ (1,0) [0|65535] "" Vector__XXX
 SG_ DIR_a113_heatsink1Temp m113 : 16|16@1- (0.1,0) [-3276.8|3276.7] "" Vector__XXX
 SG_ DIR_a113_heatsink2Temp m113 : 32|16@1- (0.1,0) [-3276.8|3276.7] "" Vector__XXX
 SG_ DIR_a113_heatsink3Temp m113 : 48|16@1- (0.1,0) [-3276.8|3276.7] "" Vector__XXX
 SG_ DIR_a115_faultAddress m115 : 16|32@1+ (1,0) [0|4294967295] "" Vector__XXX
 SG_ DIR_a115_isWriteNotRead m115 : 48|1@1+ (1,0) [0|1] "" Vector__XXX
 SG_ DIR_a117_torque m117 : 16|1@1+ (1,0) [0|1] "" Vector__XXX
 SG_ DIR_a117_slaveCommand m117 : 17|1@1+ (1,0) [0|1] "" Vector__XXX
 SG_ DIR_a117_power m117 : 18|1@1+ (1,0) [0|1] "" Vector__XXX
 SG_ DIR_a117_slaveCommand2 m117 : 19|1@1+ (1,0) [0|1] "" Vector__XXX
 SG_ DIR_a117_speed m117 : 20|1@1+ (1,0) [0|1] "" Vector__XXX
 SG_ DIR_a117_chassisControl m117 : 21|1@1+ (1,0) [0|1] "" Vector__XXX
 SG_ DIR_a117_systemStatus m117 : 22|1@1+ (1,0) [0|1] "" Vector__XXX
 SG_ DIR_a117_temperature m117 : 23|1@1+ (1,0) [0|1] "" Vector__XXX
 SG_ DIR_a117_vehicle m117 : 24|1@1+ (1,0) [0|1] "" Vector__XXX
 SG_ DIR_a117_AddTcLimit m117 : 26|1@1+ (1,0) [0|1] "" Vector__XXX
 SG_ DIR_a117_dixCommand m117 : 27|1@1+ (1,0) [0|1] "" Vector__XXX
 SG_ DIR_a117_odometerStatus m117 : 30|1@1+ (1,0) [0|1] "" Vector__XXX
 SG_ DIR_a117_maxRatedPower m117 : 31|1@1+ (1,0) [0|1] "" Vector__XXX
 SG_ DIR_a119_hvpFaults m119 : 16|1@1+ (1,0) [0|1] "" Vector__XXX
 SG_ DIR_a120_dcLinkInfo m120 : 16|1@1+ (1,0) [0|1] "" Vector__XXX
 SG_ DIR_a121_badRegReason m121 : 16|3@1+ (1,0) [0|7] "" Vector__XXX
 SG_ DIR_a121_torqueDelta m121 : 19|13@1- (0.25,0) [-1024|1023.75] "" Vector__XXX
 SG_ DIR_a121_badCurrent m121 : 32|16@1- (0.1,0) [-3276.8|3276.7] "" Vector__XXX
 SG_ DIR_a121_badFlux m121 : 48|16@1+ (0.0001,0) [0|6.5535] "" Vector__XXX
 SG_ DIR_a123_lossReason m123 : 16|3@1+ (1,0) [0|7] "" Vector__XXX
 SG_ DIR_a123_busVoltage m123 : 19|6@1+ (4,250) [250|502] "" Vector__XXX
 SG_ DIR_a123_badFlux m123 : 25|7@1+ (0.0015,0) [0|0.1905] "" Vector__XXX
 SG_ DIR_a123_lossRequest m123 : 32|7@1+ (0.1,0) [0|12.7] "" Vector__XXX
 SG_ DIR_a123_badCurrent m123 : 39|9@1- (10,0) [-2560|2550] "" Vector__XXX
 SG_ DIR_a123_motorRPM m123 : 48|8@1- (150,0) [-19200|19050] "" Vector__XXX
 SG_ DIR_a123_varianceD m123 : 56|4@1+ (20,0) [0|300] "" Vector__XXX
 SG_ DIR_a123_varianceQ m123 : 60|4@1+ (20,0) [0|300] "" Vector__XXX
 SG_ DIR_a126_limpReason m126 : 16|6@1+ (1,0) [0|63] "" Vector__XXX
 SG_ DIR_a127_gpoReason m127 : 16|4@1+ (1,0) [0|15] "" Vector__XXX
 SG_ DIR_a127_temp m127 : 24|16@1- (0.1,0) [-3276.8|3276.7] "" Vector__XXX
 SG_ DIR_a133_capacitorTemp m133 : 16|16@1- (0.1,0) [-3276.8|3276.7] "" Vector__XXX
 SG_ DIR_a133_badValue1 m133 : 32|16@1- (0.1,0) [-3276.8|3276.7] "" Vector__XXX
 SG_ DIR_a133_badValue2 m133 : 48|16@1- (0.1,0) [-3276.8|3276.7] "" Vector__XXX
 SG_ DIR_a134_wheelSpeedDiffFrL m134 : 16|12@1- (0.0625,0) [-128|127.9375] "" Vector__XXX
 SG_ DIR_a134_wheelSpeedDiffFrR m134 : 28|12@1- (0.0625,0) [-128|127.9375] "" Vector__XXX
 SG_ DIR_a134_wheelSpeedDiffReL m134 : 40|12@1- (0.0625,0) [-128|127.9375] "" Vector__XXX
 SG_ DIR_a134_wheelSpeedDiffReR m134 : 52|12@1- (0.0625,0) [-128|127.9375] "" Vector__XXX
 SG_ DIR_a136_spiError_BL m136 : 16|1@1+ (1,0) [0|1] "" Vector__XXX
 SG_ DIR_a136_crcError_BL m136 : 17|1@1+ (1,0) [0|1] "" Vector__XXX
 SG_ DIR_a136_busyError_BL m136 : 18|1@1+ (1,0) [0|1] "" Vector__XXX
 SG_ DIR_a136_spiError_BH m136 : 19|1@1+ (1,0) [0|1] "" Vector__XXX
 SG_ DIR_a136_crcError_BH m136 : 20|1@1+ (1,0) [0|1] "" Vector__XXX
 SG_ DIR_a136_busyError_BH m136 : 21|1@1+ (1,0) [0|1] "" Vector__XXX
 SG_ DIR_a136_spiError_CL m136 : 22|1@1+ (1,0) [0|1] "" Vector__XXX
 SG_ DIR_a136_crcError_CL m136 : 23|1@1+ (1,0) [0|1] "" Vector__XXX
 SG_ DIR_a136_busyError_CL m136 : 24|1@1+ (1,0) [0|1] "" Vector__XXX
 SG_ DIR_a136_spiError_CH m136 : 25|1@1+ (1,0) [0|1] "" Vector__XXX
 SG_ DIR_a136_crcError_CH m136 : 26|1@1+ (1,0) [0|1] "" Vector__XXX
 SG_ DIR_a136_busyError_CH m136 : 27|1@1+ (1,0) [0|1] "" Vector__XXX
 SG_ DIR_a136_spiError_AL m136 : 28|1@1+ (1,0) [0|1] "" Vector__XXX
 SG_ DIR_a136_crcError_AL m136 : 29|1@1+ (1,0) [0|1] "" Vector__XXX
 SG_ DIR_a136_busyError_AL m136 : 30|1@1+ (1,0) [0|1] "" Vector__XXX
 SG_ DIR_a136_spiError_AH m136 : 31|1@1+ (1,0) [0|1] "" Vector__XXX
 SG_ DIR_a136_crcError_AH m136 : 32|1@1+ (1,0) [0|1] "" Vector__XXX
 SG_ DIR_a136_busyError_AH m136 : 33|1@1+ (1,0) [0|1] "" Vector__XXX
 SG_ DIR_a144_autopilot m144 : 16|1@1+ (1,0) [0|1] "" Vector__XXX
 SG_ DIR_a144_chassisType m144 : 17|1@1+ (1,0) [0|1] "" Vector__XXX
 SG_ DIR_a144_drivetrainType m144 : 18|1@1+ (1,0) [0|1] "" Vector__XXX
 SG_ DIR_a144_packEnergy m144 : 19|1@1+ (1,0) [0|1] "" Vector__XXX
 SG_ DIR_a144_packPerformanceDeviatio m144 : 20|1@1+ (1,0) [0|1] "" Vector__XXX
 SG_ DIR_a144_performancePackage m144 : 21|1@1+ (1,0) [0|1] "" Vector__XXX
 SG_ DIR_a144_vdcType m144 : 22|1@1+ (1,0) [0|1] "" Vector__XXX
 SG_ DIR_a144_brakeHWType m144 : 23|1@1+ (1,0) [0|1] "" Vector__XXX
 SG_ DIR_a144_inverterHardware m144 : 24|1@1+ (1,0) [0|1] "" Vector__XXX
 SG_ DIR_a144_cabinPTCHeaterType m144 : 25|1@1+ (1,0) [0|1] "" Vector__XXX
 SG_ DIR_a144_frunkLatchType m144 : 26|1@1+ (1,0) [0|1] "" Vector__XXX
 SG_ DIR_a144_platformMaxBusVoltage m144 : 27|1@1+ (1,0) [0|1] "" Vector__XXX
 SG_ DIR_a144_oilPump1HwType m144 : 28|1@1+ (1,0) [0|1] "" Vector__XXX
 SG_ DIR_a144_oilPump2HwType m144 : 29|1@1+ (1,0) [0|1] "" Vector__XXX
 SG_ DIR_a144_heatsinkType m144 : 30|1@1+ (1,0) [0|1] "" Vector__XXX
 SG_ DIR_a144_softPerformanceLimit m144 : 31|1@1+ (1,0) [0|1] "" Vector__XXX
 SG_ DIR_a144_brakeActuationType m144 : 32|1@1+ (1,0) [0|1] "" Vector__XXX
 SG_ DIR_a144_dasHw m144 : 33|1@1+ (1,0) [0|1] "" Vector__XXX
 SG_ DIR_a144_chassisSubType m144 : 34|1@1+ (1,0) [0|1] "" Vector__XXX
 SG_ DIR_a147_overtorque1UsedCount m147 : 16|8@1+ (1,0) [0|255] "" Vector__XXX
 SG_ DIR_a147_overtorque2UsedCount m147 : 24|10@1+ (1,0) [0|1023] "" Vector__XXX
 SG_ DIR_a147_accumulatedWear m147 : 34|10@1+ (0.005,0) [0|5.115] "" Vector__XXX
 SG_ DIR_a147_wearIsValid m147 : 44|1@1+ (1,0) [0|1] "" Vector__XXX
 SG_ DIR_a149_flow m149 : 16|8@1+ (0.1,0) [0|25.5] "" Vector__XXX
 SG_ DIR_a149_voltage m149 : 24|8@1+ (0.1,0) [0|25.5] "" Vector__XXX
 SG_ DIR_a149_temperature m149 : 32|8@1+ (1,-40) [-40|215] "" Vector__XXX
 SG_ DIR_a149_state m149 : 40|3@1+ (1,0) [0|7] "" Vector__XXX
 SG_ DIR_a149_fluidTempSNA m149 : 43|1@1+ (1,0) [0|1] "" Vector__XXX
 SG_ DIR_a149_insufficientFlow m149 : 44|1@1+ (1,0) [0|1] "" Vector__XXX
 SG_ DIR_a149_motorOpenPhase m149 : 45|1@1+ (1,0) [0|1] "" Vector__XXX
 SG_ DIR_a149_motorShorted m149 : 46|1@1+ (1,0) [0|1] "" Vector__XXX
 SG_ DIR_a149_motorFlowSNA m149 : 47|1@1+ (1,0) [0|1] "" Vector__XXX
 SG_ DIR_a149_responseError m149 : 48|1@1+ (1,0) [0|1] "" Vector__XXX
 SG_ DIR_a149_pcbaID m149 : 49|1@1+ (1,0) [0|1] "" Vector__XXX
 SG_ DIR_a150_vBatRawMinusFiltered m150 : 16|10@1- (1,0) [-512|511] "" Vector__XXX
 SG_ DIR_a150_vBatFilteredRate m150 : 32|8@1- (100,0) [-12800|12700] "" Vector__XXX
 SG_ DIR_a150_elapsedMs m150 : 40|8@1+ (1,0) [0|255] "" Vector__XXX
 SG_ DIR_a150_energy m150 : 48|16@1+ (1,0) [0|65535] "" Vector__XXX
 SG_ DIR_a152_errorType m152 : 16|3@1+ (1,0) [0|7] "" Vector__XXX
 SG_ DIR_a152_frameId m152 : 24|8@1+ (1,0) [0|255] "" Vector__XXX
 SG_ DIR_a152_badValue m152 : 32|8@1+ (1,0) [0|255] "" Vector__XXX
 SG_ DIR_a152_expectedValue m152 : 40|8@1+ (1,0) [0|255] "" Vector__XXX
 SG_ DIR_a153_oilFlow m153 : 16|8@1+ (0.1,0) [0|25.5] "" Vector__XXX
 SG_ DIR_a153_oilTemperature m153 : 24|8@1+ (1,-40) [-40|215] "" Vector__XXX
 SG_ DIR_a153_phaseCurrent m153 : 32|8@1+ (0.1,0) [0|25.5] "" Vector__XXX
 SG_ DIR_a153_dcVoltage m153 : 40|8@1+ (0.3,0) [0|76.5] "" Vector__XXX
 SG_ DIR_a153_lowPressPlausibility m153 : 48|5@1+ (3.3,0) [0|102.3] "" Vector__XXX
 SG_ DIR_a153_state m153 : 53|3@1+ (1,0) [0|7] "" Vector__XXX
 SG_ DIR_a153_oilPumpAlert m153 : 56|5@1+ (1,0) [0|31] "" Vector__XXX
 SG_ DIR_a153_reason m153 : 61|3@1+ (1,0) [0|7] "" Vector__XXX
 SG_ DIR_a154_motorRPM m154 : 16|16@1- (1,0) [-32768|32767] "" Vector__XXX
 SG_ DIR_a154_phaseError m154 : 32|8@1- (0.004,0) [-0.512|0.508] "" Vector__XXX
 SG_ DIR_a154_commonGain m154 : 40|8@1+ (0.02,0) [0|5.1] "" Vector__XXX
 SG_ DIR_a154_noCalibration m154 : 48|1@1+ (1,0) [0|1] "" Vector__XXX
 SG_ DIR_a154_noPhaseLock m154 : 49|1@1+ (1,0) [0|1] "" Vector__XXX
 SG_ DIR_a154_noCarrier m154 : 50|1@1+ (1,0) [0|1] "" Vector__XXX
 SG_ DIR_a154_notReady m154 : 51|1@1+ (1,0) [0|1] "" Vector__XXX
 SG_ DIR_a154_errorTableInvalid m154 : 52|1@1+ (1,0) [0|1] "" Vector__XXX
 SG_ DIR_a154_carrierOffset m154 : 53|1@1+ (1,0) [0|1] "" Vector__XXX
 SG_ DIR_a154_trackerIrrational m154 : 54|1@1+ (1,0) [0|1] "" Vector__XXX
 SG_ DIR_a154_claMIA m154 : 55|1@1+ (1,0) [0|1] "" Vector__XXX
 SG_ DIR_a155_sensors m155 : 16|1@1+ (1,0) [0|1] "" Vector__XXX
 SG_ DIR_a155_coolant m155 : 17|1@1+ (1,0) [0|1] "" Vector__XXX
 SG_ DIR_a155_LVPowerState m155 : 18|1@1+ (1,0) [0|1] "" Vector__XXX
 SG_ DIR_a155_vehicleStatus m155 : 19|1@1+ (1,0) [0|1] "" Vector__XXX
 SG_ DIR_a155_status m155 : 20|1@1+ (1,0) [0|1] "" Vector__XXX
 SG_ DIR_a155_leftDoorStatus m155 : 21|1@1+ (1,0) [0|1] "" Vector__XXX
 SG_ DIR_a155_rightDoorStatus m155 : 22|1@1+ (1,0) [0|1] "" Vector__XXX
 SG_ DIR_a155_vcleftSwitchStatus m155 : 23|1@1+ (1,0) [0|1] "" Vector__XXX
 SG_ DIR_a155_restraintStatus m155 : 24|1@1+ (1,0) [0|1] "" Vector__XXX
 SG_ DIR_a155_systemStatus m155 : 25|1@1+ (1,0) [0|1] "" Vector__XXX
 SG_ DIR_a155_prndStatus m155 : 26|1@1+ (1,0) [0|1] "" Vector__XXX
 SG_ DIR_a155_liftgateStatus m155 : 27|1@1+ (1,0) [0|1] "" Vector__XXX
 SG_ DIR_a157_RCM_inertial1 m157 : 16|1@1+ (1,0) [0|1] "" Vector__XXX
 SG_ DIR_a157_RCM_inertial2 m157 : 17|1@1+ (1,0) [0|1] "" Vector__XXX
 SG_ DIR_a158_IBST_party1 m158 : 16|1@1+ (1,0) [0|1] "" Vector__XXX
 SG_ DIR_a158_BUS1_IBST_status m158 : 17|1@1+ (1,0) [0|1] "" Vector__XXX
 SG_ DIR_a158_BUS2_IBST_status m158 : 18|1@1+ (1,0) [0|1] "" Vector__XXX
 SG_ DIR_a160_vBatRawMinusFiltered m160 : 16|10@1- (1,0) [-512|511] "" Vector__XXX
 SG_ DIR_a160_vBatFilteredRate m160 : 32|8@1- (100,0) [-12800|12700] "" Vector__XXX
 SG_ DIR_a160_elapsedMs m160 : 40|8@1+ (1,0) [0|255] "" Vector__XXX
 SG_ DIR_a160_energy m160 : 48|16@1+ (1,0) [0|65535] "" Vector__XXX
 SG_ DIR_a161_EPAS3P_sysStatus m161 : 16|1@1+ (1,0) [0|1] "" Vector__XXX
 SG_ DIR_a161_EPAS3P_angleCalib m161 : 17|1@1+ (1,0) [0|1] "" Vector__XXX
 SG_ DIR_a202_reason m202 : 16|4@1+ (1,0) [0|15] "" Vector__XXX
 SG_ DIR_a202_movement m202 : 20|9@1+ (0.005,0) [0|2.555] "" Vector__XXX
 SG_ DIR_a202_sysStateExitCondition m202 : 32|5@1+ (1,0) [0|31] "" Vector__XXX
 SG_ DIR_a233_missedMsgCount m233 : 16|16@1+ (1,0) [0|65535] "" Vector__XXX
 SG_ DIR_a233_serviceModeActive m233 : 32|1@1+ (1,0) [0|1] "" Vector__XXX
 SG_ DIR_a234_PCS_dcdcStatus m234 : 16|1@1+ (1,0) [0|1] "" Vector__XXX
 SG_ DIR_a236_states m236 : 16|1@1+ (1,0) [0|1] "" Vector__XXX
 SG_ DIR_a242_RotorOffset m242 : 16|1@1+ (1,0) [0|1] "" Vector__XXX
 SG_ DIR_a242_RotorFlux m242 : 17|1@1+ (1,0) [0|1] "" Vector__XXX
 SG_ DIR_a242_ResolverError m242 : 18|1@1+ (1,0) [0|1] "" Vector__XXX
 SG_ DIR_a244_desatHighSide m244 : 16|1@1+ (1,0) [0|1] "" Vector__XXX
 SG_ DIR_a244_desatLowSide m244 : 17|1@1+ (1,0) [0|1] "" Vector__XXX
 SG_ DIR_a244_singleSwitchShort m244 : 18|1@1+ (1,0) [0|1] "" Vector__XXX
 SG_ DIR_a244_flybackFault m244 : 19|1@1+ (1,0) [0|1] "" Vector__XXX
 SG_ DIR_a244_postShortTestFailed m244 : 20|1@1+ (1,0) [0|1] "" Vector__XXX
 SG_ DIR_a244_udsSelfTest m244 : 21|1@1+ (1,0) [0|1] "" Vector__XXX
 SG_ DIR_a244_irSensorV m244 : 24|6@1+ (0.1,0) [0|6.3] "" Vector__XXX
 SG_ DIR_a244_gateDriveICUndervoltage m244 : 30|1@1+ (1,0) [0|1] "" Vector__XXX
 SG_ DIR_a244_plausibleSingleSwitchSh m244 : 31|1@1+ (1,0) [0|1] "" Vector__XXX
 SG_ DIR_a246_atSpeedDIResetCount m246 : 16|4@1+ (1,4294967295) [4294967295|4294967310] "" Vector__XXX
 SG_ DIR_a246_didPMCauseASC m246 : 20|1@1+ (1,0) [0|1] "" Vector__XXX
 SG_ DIR_a246_currentSensorRational m246 : 21|1@1+ (1,0) [0|1] "" Vector__XXX
 SG_ DIR_a246_observerDetectedLS3PS m246 : 22|1@1+ (1,0) [0|1] "" Vector__XXX
 SG_ DIR_a246_hvIsGood m246 : 23|1@1+ (1,0) [0|1] "" Vector__XXX
 SG_ DIR_a246_lvIsGood m246 : 24|1@1+ (1,0) [0|1] "" Vector__XXX
 SG_ DIR_a246_codeBranch m246 : 25|2@1+ (1,0) [0|3] "" Vector__XXX
 SG_ DIR_a246_motorRPM m246 : 32|8@1- (150,0) [-19200|19050] "" Vector__XXX
 SG_ DIR_a246_eepromOffsetIa m246 : 40|6@1- (0.763,0) [-24.416|23.653] "" Vector__XXX
 SG_ DIR_a246_eepromOffsetIb m246 : 48|6@1- (0.763,0) [-24.416|23.653] "" Vector__XXX
 SG_ DIR_a247_rotorOffsetEst m247 : 16|10@1- (0.05,0) [-25.6|25.55] "" Vector__XXX
 SG_ DIR_a247_motorRPM m247 : 32|16@1- (1,0) [-32768|32767] "" Vector__XXX
 SG_ DIR_a247_torqueMotor m247 : 48|16@1- (1,0) [-32768|32767] "" Vector__XXX
 SG_ DIR_a251_oilFlow m251 : 16|8@1+ (0.1,0) [0|25.5] "" Vector__XXX
 SG_ DIR_a251_oilTemperature m251 : 24|8@1+ (1,-40) [-40|215] "" Vector__XXX
 SG_ DIR_a251_dcVoltage m251 : 32|8@1+ (0.3,0) [0|76.5] "" Vector__XXX
 SG_ DIR_a251_dcCurrent m251 : 40|8@1+ (0.1,0) [0|25.5] "" Vector__XXX
 SG_ DIR_a251_phaseCurrent m251 : 48|8@1+ (0.1,0) [0|25.5] "" Vector__XXX
 SG_ DIR_a251_leadAngle m251 : 56|4@1+ (1.875,0) [0|28.125] "" Vector__XXX
 SG_ DIR_a251_reason m251 : 60|3@1+ (1,0) [0|7] "" Vector__XXX

BO_ 935 DIR_alertMatrix1: 8 DIR
 SG_ DIR_a001_hwPhaseAgateDrive : 0|1@1+ (1,0) [0|1] "" Vector__XXX
 SG_ DIR_a002_hwPhaseBgateDrive : 1|1@1+ (1,0) [0|1] "" Vector__XXX
 SG_ DIR_a003_hwPhaseCgateDrive : 2|1@1+ (1,0) [0|1] "" Vector__XXX
 SG_ DIR_a004_hwPhaseApeak : 3|1@1+ (1,0) [0|1] "" Vector__XXX
 SG_ DIR_a005_hwPhaseBpeak : 4|1@1+ (1,0) [0|1] "" Vector__XXX
 SG_ DIR_a006_hwPhaseCpeak : 5|1@1+ (1,0) [0|1] "" Vector__XXX
 SG_ DIR_a007_statorAnomalyDetected : 6|1@1+ (1,0) [0|1] "" Vector__XXX
 SG_ DIR_a008_hwEncoderA : 7|1@1+ (1,0) [0|1] "" Vector__XXX
 SG_ DIR_a009_hwEncoderB : 8|1@1+ (1,0) [0|1] "" Vector__XXX
 SG_ DIR_a010_unintendedReset : 9|1@1+ (1,0) [0|1] "" Vector__XXX
 SG_ DIR_a011_swPowerStageNotReady : 10|1@1+ (1,0) [0|1] "" Vector__XXX
 SG_ DIR_a012_hvilNotClosed : 11|1@1+ (1,0) [0|1] "" Vector__XXX
 SG_ DIR_a013_eccError : 12|1@1+ (1,0) [0|1] "" Vector__XXX
 SG_ DIR_a014_activeDamping : 13|1@1+ (1,0) [0|1] "" Vector__XXX
 SG_ DIR_a015_mechSafeStateAnomaly : 14|1@1+ (1,0) [0|1] "" Vector__XXX
 SG_ DIR_a016_safeStateApplied : 15|1@1+ (1,0) [0|1] "" Vector__XXX
 SG_ DIR_a017_hwPedalMonitor : 16|1@1+ (1,0) [0|1] "" Vector__XXX
 SG_ DIR_a018_hwLVSupplyUV : 17|1@1+ (1,0) [0|1] "" Vector__XXX
 SG_ DIR_a020_hwMotorEncoder : 19|1@1+ (1,0) [0|1] "" Vector__XXX
 SG_ DIR_a021_hwBusOV : 20|1@1+ (1,0) [0|1] "" Vector__XXX
 SG_ DIR_a022_hw5vSupplyUV : 21|1@1+ (1,0) [0|1] "" Vector__XXX
 SG_ DIR_a024_selfTest : 23|1@1+ (1,0) [0|1] "" Vector__XXX
 SG_ DIR_a025_phaseApeak : 24|1@1+ (1,0) [0|1] "" Vector__XXX
 SG_ DIR_a026_phaseBpeak : 25|1@1+ (1,0) [0|1] "" Vector__XXX
 SG_ DIR_a027_phaseCpeak : 26|1@1+ (1,0) [0|1] "" Vector__XXX
 SG_ DIR_a028_phaseArms : 27|1@1+ (1,0) [0|1] "" Vector__XXX
 SG_ DIR_a029_phaseBrms : 28|1@1+ (1,0) [0|1] "" Vector__XXX
 SG_ DIR_a030_phaseCrms : 29|1@1+ (1,0) [0|1] "" Vector__XXX
 SG_ DIR_a031_phaseAcurrentOffset : 30|1@1+ (1,0) [0|1] "" Vector__XXX
 SG_ DIR_a032_phaseBcurrentOffset : 31|1@1+ (1,0) [0|1] "" Vector__XXX
 SG_ DIR_a033_phaseAcurrentSensor : 32|1@1+ (1,0) [0|1] "" Vector__XXX
 SG_ DIR_a034_phaseBcurrentSensor : 33|1@1+ (1,0) [0|1] "" Vector__XXX
 SG_ DIR_a035_phaseCurrentBalance : 34|1@1+ (1,0) [0|1] "" Vector__XXX
 SG_ DIR_a036_busOV : 35|1@1+ (1,0) [0|1] "" Vector__XXX
 SG_ DIR_a037_busUV : 36|1@1+ (1,0) [0|1] "" Vector__XXX
 SG_ DIR_a038_busVsensor : 37|1@1+ (1,0) [0|1] "" Vector__XXX
 SG_ DIR_a039_exceptionUndefinedInstr : 38|1@1+ (1,0) [0|1] "" Vector__XXX
 SG_ DIR_a040_difMIA : 39|1@1+ (1,0) [0|1] "" Vector__XXX
 SG_ DIR_a041_sdcMIA : 40|1@1+ (1,0) [0|1] "" Vector__XXX
 SG_ DIR_a042_inletSensor : 41|1@1+ (1,0) [0|1] "" Vector__XXX
 SG_ DIR_a043_outletOT : 42|1@1+ (1,0) [0|1] "" Vector__XXX
 SG_ DIR_a044_outletUT : 43|1@1+ (1,0) [0|1] "" Vector__XXX
 SG_ DIR_a045_outletSensor : 44|1@1+ (1,0) [0|1] "" Vector__XXX
 SG_ DIR_a046_statorOT : 45|1@1+ (1,0) [0|1] "" Vector__XXX
 SG_ DIR_a047_statorSensor1 : 46|1@1+ (1,0) [0|1] "" Vector__XXX
 SG_ DIR_a048_statorSensor2 : 47|1@1+ (1,0) [0|1] "" Vector__XXX
 SG_ DIR_a049_statorSensorDiff : 48|1@1+ (1,0) [0|1] "" Vector__XXX
 SG_ DIR_a050_noStatorSensor : 49|1@1+ (1,0) [0|1] "" Vector__XXX
 SG_ DIR_a052_dirMIA : 51|1@1+ (1,0) [0|1] "" Vector__XXX
 SG_ DIR_a053_unexpectedLatchState : 52|1@1+ (1,0) [0|1] "" Vector__XXX
 SG_ DIR_a054_driveInverterOT : 53|1@1+ (1,0) [0|1] "" Vector__XXX
 SG_ DIR_a055_trqCrossCheck : 54|1@1+ (1,0) [0|1] "" Vector__XXX
 SG_ DIR_a056_ambientOT : 55|1@1+ (1,0) [0|1] "" Vector__XXX
 SG_ DIR_a057_ambientUT : 56|1@1+ (1,0) [0|1] "" Vector__XXX
 SG_ DIR_a058_ambientSensor : 57|1@1+ (1,0) [0|1] "" Vector__XXX
 SG_ DIR_a059_heatsinkOT : 58|1@1+ (1,0) [0|1] "" Vector__XXX
 SG_ DIR_a060_heatsinkUT : 59|1@1+ (1,0) [0|1] "" Vector__XXX
 SG_ DIR_a061_heatsinkSensor : 60|1@1+ (1,0) [0|1] "" Vector__XXX
 SG_ DIR_a062_systemLimpMode : 61|1@1+ (1,0) [0|1] "" Vector__XXX
 SG_ DIR_a063_bbMIA : 62|1@1+ (1,0) [0|1] "" Vector__XXX
 SG_ DIR_a064_torqueIntervention : 63|1@1+ (1,0) [0|1] "" Vector__XXX

BO_ 949 DIR_alertMatrix2: 8 DIR
 SG_ DIR_a065_canHardwareBusB : 0|1@1+ (1,0) [0|1] "" Vector__XXX
 SG_ DIR_a066_canDataBusB : 1|1@1+ (1,0) [0|1] "" Vector__XXX
 SG_ DIR_a067_canOverrunBusB : 2|1@1+ (1,0) [0|1] "" Vector__XXX
 SG_ DIR_a069_rotorTempLimit : 4|1@1+ (1,0) [0|1] "" Vector__XXX
 SG_ DIR_a070_udsTransactionInitiated : 5|1@1+ (1,0) [0|1] "" Vector__XXX
 SG_ DIR_a071_busDisconnected : 6|1@1+ (1,0) [0|1] "" Vector__XXX
 SG_ DIR_a072_gateDriveFaultCounter : 7|1@1+ (1,0) [0|1] "" Vector__XXX
 SG_ DIR_a073_motorSpeed : 8|1@1+ (1,0) [0|1] "" Vector__XXX
 SG_ DIR_a074_motorEncoder : 9|1@1+ (1,0) [0|1] "" Vector__XXX
 SG_ DIR_a075_motorSpeedMismatch : 10|1@1+ (1,0) [0|1] "" Vector__XXX
 SG_ DIR_a076_lvSupplyOV : 11|1@1+ (1,0) [0|1] "" Vector__XXX
 SG_ DIR_a077_lvSupplyUV : 12|1@1+ (1,0) [0|1] "" Vector__XXX
 SG_ DIR_a078_adcRefLow : 13|1@1+ (1,0) [0|1] "" Vector__XXX
 SG_ DIR_a079_adcRefHigh : 14|1@1+ (1,0) [0|1] "" Vector__XXX
 SG_ DIR_a080_adcInfo : 15|1@1+ (1,0) [0|1] "" Vector__XXX
 SG_ DIR_a081_P0BFF_DIR_EM_CurrentHig : 16|1@1+ (1,0) [0|1] "" Vector__XXX
 SG_ DIR_a082_P0F45_DIR_ECU_DemoTimer : 17|1@1+ (1,0) [0|1] "" Vector__XXX
 SG_ DIR_a083_P98B3_DIR_ECU_DemoWindo : 18|1@1+ (1,0) [0|1] "" Vector__XXX
 SG_ DIR_a084_eccTestData0 : 19|1@1+ (1,0) [0|1] "" Vector__XXX
 SG_ DIR_a086_activeDischargeOn : 21|1@1+ (1,0) [0|1] "" Vector__XXX
 SG_ DIR_a087_gtwMIA : 22|1@1+ (1,0) [0|1] "" Vector__XXX
 SG_ DIR_a088_uiMIA : 23|1@1+ (1,0) [0|1] "" Vector__XXX
 SG_ DIR_a090_pmMIA : 25|1@1+ (1,0) [0|1] "" Vector__XXX
 SG_ DIR_a091_espMIA : 26|1@1+ (1,0) [0|1] "" Vector__XXX
 SG_ DIR_a092_bmsMIA : 27|1@1+ (1,0) [0|1] "" Vector__XXX
 SG_ DIR_a093_canHardwareBusA : 28|1@1+ (1,0) [0|1] "" Vector__XXX
 SG_ DIR_a094_canDataBusA : 29|1@1+ (1,0) [0|1] "" Vector__XXX
 SG_ DIR_a095_canOverrunBusA : 30|1@1+ (1,0) [0|1] "" Vector__XXX
 SG_ DIR_a096_memoryError : 31|1@1+ (1,0) [0|1] "" Vector__XXX
 SG_ DIR_a097_eepromError : 32|1@1+ (1,0) [0|1] "" Vector__XXX
 SG_ DIR_a098_intTimeTooLong : 33|1@1+ (1,0) [0|1] "" Vector__XXX
 SG_ DIR_a099_threadOverrun : 34|1@1+ (1,0) [0|1] "" Vector__XXX
 SG_ DIR_a100_assertion : 35|1@1+ (1,0) [0|1] "" Vector__XXX
 SG_ DIR_a101_eccTestData1 : 36|1@1+ (1,0) [0|1] "" Vector__XXX
 SG_ DIR_a102_exceptionPrefetchAbort : 37|1@1+ (1,0) [0|1] "" Vector__XXX
 SG_ DIR_a103_lowFlow : 38|1@1+ (1,0) [0|1] "" Vector__XXX
 SG_ DIR_a107_fpgaError : 42|1@1+ (1,0) [0|1] "" Vector__XXX
 SG_ DIR_a108_stateTrans : 43|1@1+ (1,0) [0|1] "" Vector__XXX
 SG_ DIR_a109_ahbWriteError : 44|1@1+ (1,0) [0|1] "" Vector__XXX
 SG_ DIR_a110_brakeMIA : 45|1@1+ (1,0) [0|1] "" Vector__XXX
 SG_ DIR_a111_badPhaseSensorCalib : 46|1@1+ (1,0) [0|1] "" Vector__XXX
 SG_ DIR_a112_noPhaseCurrent : 47|1@1+ (1,0) [0|1] "" Vector__XXX
 SG_ DIR_a113_noFuncHeatsinkSensor : 48|1@1+ (1,0) [0|1] "" Vector__XXX
 SG_ DIR_a114_exceptionDataAbort : 49|1@1+ (1,0) [0|1] "" Vector__XXX
 SG_ DIR_a115_exceptionDataAbort2 : 50|1@1+ (1,0) [0|1] "" Vector__XXX
 SG_ DIR_a116_highSpeedWearCounter : 51|1@1+ (1,0) [0|1] "" Vector__XXX
 SG_ DIR_a117_diMIA : 52|1@1+ (1,0) [0|1] "" Vector__XXX
 SG_ DIR_a119_hvpMIA : 54|1@1+ (1,0) [0|1] "" Vector__XXX
 SG_ DIR_a120_hvlinkMIA : 55|1@1+ (1,0) [0|1] "" Vector__XXX
 SG_ DIR_a121_motorControlRegulation : 56|1@1+ (1,0) [0|1] "" Vector__XXX
 SG_ DIR_a122_highStackUsage : 57|1@1+ (1,0) [0|1] "" Vector__XXX
 SG_ DIR_a123_lossMotorControl : 58|1@1+ (1,0) [0|1] "" Vector__XXX
 SG_ DIR_a126_limpMode : 61|1@1+ (1,0) [0|1] "" Vector__XXX
 SG_ DIR_a127_gracefulPowerOff : 62|1@1+ (1,0) [0|1] "" Vector__XXX
 SG_ DIR_a128_fpgaVersionMismatch : 63|1@1+ (1,0) [0|1] "" Vector__XXX

BO_ 965 DIR_alertMatrix3: 8 DIR
 SG_ DIR_a133_capacitorOT : 4|1@1+ (1,0) [0|1] "" Vector__XXX
 SG_ DIR_a134_wheelSpeedIrrational : 5|1@1+ (1,0) [0|1] "" Vector__XXX
 SG_ DIR_a136_spiError : 7|1@1+ (1,0) [0|1] "" Vector__XXX
 SG_ DIR_a142_highLashAngle : 13|1@1+ (1,0) [0|1] "" Vector__XXX
 SG_ DIR_a144_configMismatch : 15|1@1+ (1,0) [0|1] "" Vector__XXX
 SG_ DIR_a147_highTorqueWearLimit : 18|1@1+ (1,0) [0|1] "" Vector__XXX
 SG_ DIR_a148_burnInCycleEnded : 19|1@1+ (1,0) [0|1] "" Vector__XXX
 SG_ DIR_a149_oilPumpFailure : 20|1@1+ (1,0) [0|1] "" Vector__XXX
 SG_ DIR_a150_busVD : 21|1@1+ (1,0) [0|1] "" Vector__XXX
 SG_ DIR_a151_shockTorqueLimiter : 22|1@1+ (1,0) [0|1] "" Vector__XXX
 SG_ DIR_a152_linError : 23|1@1+ (1,0) [0|1] "" Vector__XXX
 SG_ DIR_a153_oilPumpDiagnostics : 24|1@1+ (1,0) [0|1] "" Vector__XXX
 SG_ DIR_a154_resolver : 25|1@1+ (1,0) [0|1] "" Vector__XXX
 SG_ DIR_a155_vcfrontMIA : 26|1@1+ (1,0) [0|1] "" Vector__XXX
 SG_ DIR_a156_currentObserver : 27|1@1+ (1,0) [0|1] "" Vector__XXX
 SG_ DIR_a157_rcmMIA : 28|1@1+ (1,0) [0|1] "" Vector__XXX
 SG_ DIR_a158_ibstMIA : 29|1@1+ (1,0) [0|1] "" Vector__XXX
 SG_ DIR_a160_busVoltageAnomaly : 31|1@1+ (1,0) [0|1] "" Vector__XXX
 SG_ DIR_a161_epas3pMIA : 32|1@1+ (1,0) [0|1] "" Vector__XXX
 SG_ DIR_a162_endOfLifetimeBurnIn : 33|1@1+ (1,0) [0|1] "" Vector__XXX
 SG_ DIR_a174_unitMayNotRestart : 45|1@1+ (1,0) [0|1] "" Vector__XXX
 SG_ DIR_a176_safetyICFault : 47|1@1+ (1,0) [0|1] "" Vector__XXX
 SG_ DIR_a177_fluxReferenceCorrected : 48|1@1+ (1,0) [0|1] "" Vector__XXX
 SG_ DIR_a178_spindownLearningBrakeAl : 49|1@1+ (1,0) [0|1] "" Vector__XXX

BO_ 997 DIR_alertMatrix4: 8 DIR
 SG_ DIR_a202_excessHeatUnavailable : 9|1@1+ (1,0) [0|1] "" Vector__XXX
 SG_ DIR_a225_tmpEstPlausibility : 32|1@1+ (1,0) [0|1] "" Vector__XXX
 SG_ DIR_a231_unintendedReset2 : 38|1@1+ (1,0) [0|1] "" Vector__XXX
 SG_ DIR_a233_diMsgMissed : 40|1@1+ (1,0) [0|1] "" Vector__XXX
 SG_ DIR_a234_pcsMIA : 41|1@1+ (1,0) [0|1] "" Vector__XXX
 SG_ DIR_a236_tasMIA : 43|1@1+ (1,0) [0|1] "" Vector__XXX
 SG_ DIR_a241_systemThermallyLimited : 48|1@1+ (1,0) [0|1] "" Vector__XXX
 SG_ DIR_a242_spinDownLearning : 49|1@1+ (1,0) [0|1] "" Vector__XXX
 SG_ DIR_a243_ecuLogAvailable : 50|1@1+ (1,0) [0|1] "" Vector__XXX
 SG_ DIR_a244_mechSafeStateApplied : 51|1@1+ (1,0) [0|1] "" Vector__XXX
 SG_ DIR_a245_mechSafeStatePreWarn : 52|1@1+ (1,0) [0|1] "" Vector__XXX
 SG_ DIR_a246_recoveryAtSpeedError : 53|1@1+ (1,0) [0|1] "" Vector__XXX
 SG_ DIR_a247_rotorOffsetError : 54|1@1+ (1,0) [0|1] "" Vector__XXX
 SG_ DIR_a248_vehicleSpeedLimited : 55|1@1+ (1,0) [0|1] "" Vector__XXX
 SG_ DIR_a249_highStatorTempFromResis : 56|1@1+ (1,0) [0|1] "" Vector__XXX
 SG_ DIR_a250_preregulatorRail : 57|1@1+ (1,0) [0|1] "" Vector__XXX
 SG_ DIR_a251_oilPumpService : 58|1@1+ (1,0) [0|1] "" Vector__XXX
 SG_ DIR_a252_currentCoreFallback : 59|1@1+ (1,0) [0|1] "" Vector__XXX
 SG_ DIR_a253_lvBoostedRail : 60|1@1+ (1,0) [0|1] "" Vector__XXX
 SG_ DIR_a254_activeDischargeRail : 61|1@1+ (1,0) [0|1] "" Vector__XXX
 SG_ DIR_a255_currentGainFallback : 62|1@1+ (1,0) [0|1] "" Vector__XXX

BO_ 2005 DIR_debug: 8 DIR
 SG_ DIR_debugSelector M : 0|8@1+ (1,0) [0|255] "" Vector__XXX
 SG_ DIR_phaseOutBusbarTemp m70 : 8|8@1+ (1,-40) [-40|215] "DegC" Vector__XXX
 SG_ DIR_phaseOutBusbarWeldTemp m70 : 16|8@1+ (1,-40) [-40|215] "DegC" Vector__XXX
 SG_ DIR_phaseOutLugTemp m70 : 24|8@1+ (1,-40) [-40|215] "DegC" Vector__XXX
 SG_ DIR_dcLinkCapTemp m70 : 32|8@1+ (1,-40) [-40|215] "DegC" Vector__XXX
 SG_ DIR_hvDcCableTemp m70 : 40|8@1+ (1,-40) [-40|215] "DegC" Vector__XXX
 SG_ DIR_negDcBusbarTemp m70 : 48|8@1+ (1,-40) [-40|215] "DegC" Vector__XXX
 SG_ DIR_posDcBusbarTemp m70 : 56|8@1+ (1,-40) [-40|215] "DegC" Vector__XXX
 SG_ DIR_statorEndWindingTemp m72 : 8|8@1+ (1,-40) [-40|215] "DegC" Vector__XXX
 SG_ DIR_rotorMaxMagnetTemp m72 : 16|8@1+ (1,-40) [-40|215] "DegC" Vector__XXX
 SG_ DIR_lightSenseV m72 : 24|6@1+ (0.1,0) [0|3.3] "V" Vector__XXX
 SG_ DIR_pyroSenseV m72 : 30|8@1+ (0.02,0) [0|3.3] "V" Vector__XXX
 SG_ DIR_statorSlotWindingTemp m72 : 46|8@1+ (1,-40) [-40|215] "DegC" Vector__XXX
 SG_ DIR_intervalMaxHvBusV m72 : 54|10@1+ (1,0) [0|1023] "V" Vector__XXX

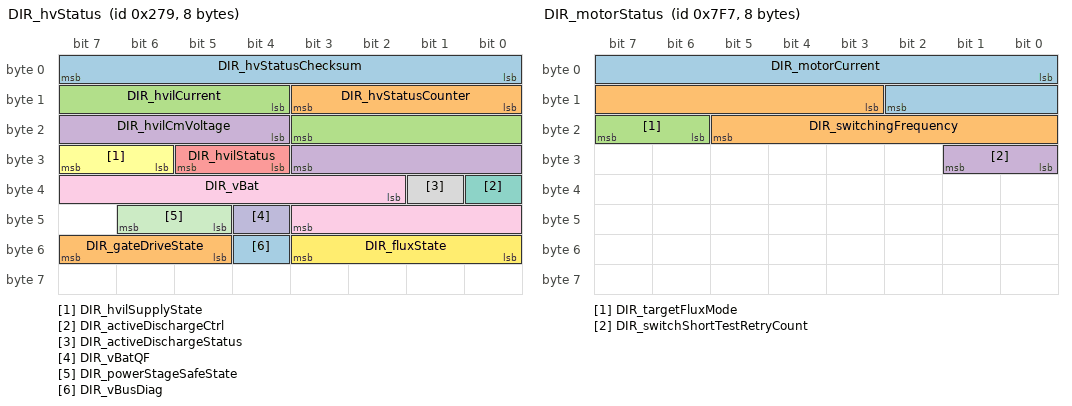
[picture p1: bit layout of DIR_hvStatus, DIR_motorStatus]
BO_ 633 DIR_hvStatus: 8 DIR
 SG_ DIR_hvStatusChecksum : 0|8@1+ (1,0) [0|255] "" Vector__XXX
 SG_ DIR_hvStatusCounter : 8|4@1+ (1,0) [0|15] "" Vector__XXX
 SG_ DIR_hvilCurrent : 12|8@1+ (0.1,0) [0|25.5] "mA" Vector__XXX
 SG_ DIR_hvilCmVoltage : 20|8@1+ (0.08,0) [0|20.4] "V" Vector__XXX
 SG_ DIR_hvilStatus : 28|2@1+ (1,0) [0|3] "" Vector__XXX
 SG_ DIR_hvilSupplyState : 30|2@1+ (1,0) [0|3] "" Vector__XXX
 SG_ DIR_activeDischargeCtrl : 32|1@1+ (1,0) [0|1] "" Vector__XXX
 SG_ DIR_activeDischargeStatus : 33|1@1+ (1,0) [0|1] "" Vector__XXX
 SG_ DIR_vBat : 34|10@1+ (1,0) [0|1023] "V" Vector__XXX
 SG_ DIR_vBatQF : 44|1@1+ (1,0) [0|1] "" Vector__XXX
 SG_ DIR_powerStageSafeState : 45|2@1+ (1,0) [0|3] "" Vector__XXX
 SG_ DIR_fluxState : 48|4@1+ (1,0) [0|15] "" Vector__XXX
 SG_ DIR_vBusDiag : 52|1@1+ (1,0) [0|1] "" Vector__XXX
 SG_ DIR_gateDriveState : 53|3@1+ (1,0) [0|7] "" Vector__XXX

BO_ 821 DIR_info: 8 DIR
 SG_ DIR_infoIndex M : 0|8@1+ (1,0) [0|255] "" Vector__XXX
 SG_ DIR_buildType m10 : 8|3@1+ (1,0) [0|7] "" Vector__XXX
 SG_ DIR_buildConfigurationId m10 : 16|16@1+ (1,0) [0|65535] "" Vector__XXX
 SG_ DIR_hardwareId m10 : 32|8@1+ (1,0) [0|252] "" Vector__XXX
 SG_ DIR_componentId m10 : 48|16@1+ (1,0) [0|65535] "" Vector__XXX
 SG_ DIR_pcbaId m11 : 16|8@1+ (1,0) [0|255] "" Vector__XXX
 SG_ DIR_assemblyId m11 : 24|8@1+ (1,0) [0|255] "" Vector__XXX
 SG_ DIR_usageId m11 : 32|16@1+ (1,0) [0|65535] "" Vector__XXX
 SG_ DIR_subUsageId m11 : 48|16@1+ (1,0) [0|65535] "" Vector__XXX
 SG_ DIR_motorType m12 : 8|5@1+ (1,0) [0|31] "" Vector__XXX
 SG_ DIR_siliconType m12 : 16|1@1+ (1,0) [0|1] "" Vector__XXX
 SG_ DIR_mechSafeStateType m12 : 24|2@1+ (1,0) [0|3] "" Vector__XXX
 SG_ DIR_applicationCrc m13 : 32|32@1+ (1,0) [0|4294967295] "" Vector__XXX
 SG_ DIR_oilPumpBuildType m16 : 8|3@1+ (1,0) [0|7] "" Vector__XXX
 SG_ DIR_oilPumpAppCrc m16 : 16|32@1+ (1,0) [0|4294967295] "" Vector__XXX
 SG_ DIR_FPGA_version m16 : 48|8@1+ (1,0) [0|255] "" Vector__XXX
 SG_ DIR_bootGitHash m18 : 8|56@1+ (1,0) [0|7.20575940379e+16] "" Vector__XXX
 SG_ DIR_infoBootLdUdsProtocolVersion m20 : 8|8@1+ (1,0) [0|255] "" Vector__XXX
 SG_ DIR_bootloaderCrc m20 : 32|32@1+ (1,0) [0|4294967295] "" Vector__XXX
 SG_ DIR_oilPumpPcbaId m33 : 8|8@1+ (1,0) [0|255] "" Vector__XXX
 SG_ DIR_oilPumpAssemblyId m33 : 16|8@1+ (1,0) [0|255] "" Vector__XXX
 SG_ DIR_oilPumpUsageId m33 : 24|16@1+ (1,0) [0|65535] "" Vector__XXX
 SG_ DIR_refRotorFlux m35 : 8|16@1+ (0.0001,0) [0|6.5535] "Wb" Vector__XXX
 SG_ DIR_refRotorOffset m35 : 24|12@1- (0.1,0) [-180|180] "deg" Vector__XXX
 SG_ DIR_speedWearTotal m36 : 8|8@1+ (0.4,0) [0|100] "%" Vector__XXX
 SG_ DIR_torqueWearTotal m36 : 24|8@1+ (0.02,0) [0|5.08] "1" Vector__XXX

BO_ 2039 DIR_motorStatus: 8 DIR
 SG_ DIR_motorCurrent : 0|11@1+ (1,0) [0|2047] "A" Vector__XXX
 SG_ DIR_switchingFrequency : 11|11@1+ (0.01,0) [0|20] "kHz" Vector__XXX
 SG_ DIR_targetFluxMode : 22|2@1+ (1,0) [0|3] "" Vector__XXX
 SG_ DIR_switchShortTestRetryCount : 24|2@1+ (1,0) [0|3] "" Vector__XXX

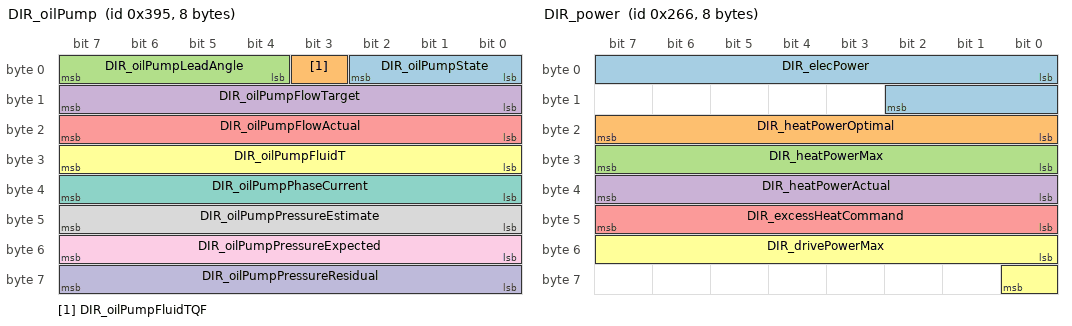
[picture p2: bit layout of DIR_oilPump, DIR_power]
BO_ 917 DIR_oilPump: 8 DIR
 SG_ DIR_oilPumpState : 0|3@1+ (1,0) [0|7] "" Vector__XXX
 SG_ DIR_oilPumpFluidTQF : 3|1@1+ (1,0) [0|1] "" Vector__XXX
 SG_ DIR_oilPumpLeadAngle : 4|4@1+ (1.875,0) [0|28.125] "degrees" Vector__XXX
 SG_ DIR_oilPumpFlowTarget : 8|8@1+ (0.1,0) [0|25.4] "LPM" Vector__XXX
 SG_ DIR_oilPumpFlowActual : 16|8@1+ (0.1,0) [0|25.4] "LPM" Vector__XXX
 SG_ DIR_oilPumpFluidT : 24|8@1+ (1,-40) [-40|214] "DegC" Vector__XXX
 SG_ DIR_oilPumpPhaseCurrent : 32|8@1+ (0.1,0) [0|25.4] "A" Vector__XXX
 SG_ DIR_oilPumpPressureEstimate : 40|8@1+ (2,0) [0|500] "kPa" Vector__XXX
 SG_ DIR_oilPumpPressureExpected : 48|8@1+ (2,0) [0|500] "kPa" Vector__XXX
 SG_ DIR_oilPumpPressureResidual : 56|8@1+ (4,-500) [-500|500] "kPa" Vector__XXX

BO_ 614 DIR_power: 8 DIR
 SG_ DIR_elecPower : 0|11@1- (0.5,0) [-500|500] "kW" Vector__XXX
 SG_ DIR_heatPowerOptimal : 16|8@1+ (0.08,0) [0|20] "kW" Vector__XXX
 SG_ DIR_heatPowerMax : 24|8@1+ (0.08,0) [0|20] "kW" Vector__XXX
 SG_ DIR_heatPowerActual : 32|8@1+ (0.08,0) [0|20] "kW" Vector__XXX
 SG_ DIR_excessHeatCommand : 40|8@1+ (0.08,0) [0|20] "kW" Vector__XXX
 SG_ DIR_drivePowerMax : 48|9@1+ (1,0) [0|400] "kW" Vector__XXX

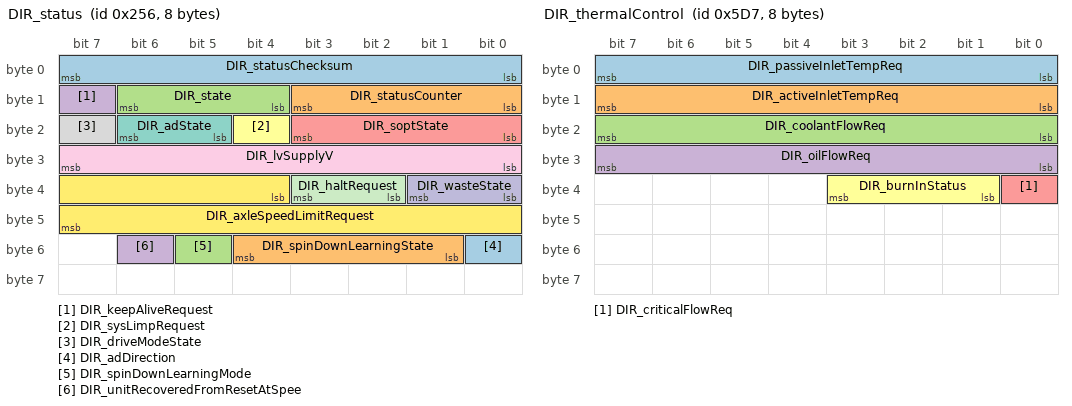
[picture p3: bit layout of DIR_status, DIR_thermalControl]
BO_ 598 DIR_status: 8 DIR
 SG_ DIR_statusChecksum : 0|8@1+ (1,0) [0|255] "" Vector__XXX
 SG_ DIR_statusCounter : 8|4@1+ (1,0) [0|15] "" Vector__XXX
 SG_ DIR_state : 12|3@1+ (1,0) [0|7] "" Vector__XXX
 SG_ DIR_keepAliveRequest : 15|1@1+ (1,0) [0|1] "" Vector__XXX
 SG_ DIR_soptState : 16|4@1+ (1,0) [0|15] "" Vector__XXX
 SG_ DIR_sysLimpRequest : 20|1@1+ (1,0) [0|1] "" Vector__XXX
 SG_ DIR_adState : 21|2@1+ (1,0) [0|3] "" Vector__XXX
 SG_ DIR_driveModeState : 23|1@1+ (1,0) [0|1] "" Vector__XXX
 SG_ DIR_lvSupplyV : 24|8@1+ (0.1,0) [0|25.5] "V" Vector__XXX
 SG_ DIR_wasteState : 32|2@1+ (1,0) [0|3] "" Vector__XXX
 SG_ DIR_haltRequest : 34|2@1+ (1,0) [0|3] "" Vector__XXX
 SG_ DIR_axleSpeedLimitRequest : 36|12@1+ (1,40) [400|2750] "RPM" Vector__XXX
 SG_ DIR_adDirection : 48|1@1+ (1,0) [0|1] "" Vector__XXX
 SG_ DIR_spinDownLearningState : 49|4@1+ (1,0) [0|15] "" Vector__XXX
 SG_ DIR_spinDownLearningMode : 53|1@1+ (1,0) [0|1] "" Vector__XXX
 SG_ DIR_unitRecoveredFromResetAtSpee : 54|1@1+ (1,0) [0|1] "" Vector__XXX

BO_ 789 DIR_temperature: 8 DIR
 SG_ DIR_tempIndex M : 0|3@1+ (1,0) [0|7] "" Vector__XXX
 SG_ DIR_inverterTQF m0 : 3|2@1+ (1,0) [0|3] "" Vector__XXX
 SG_ DIR_pcbT m0 : 8|8@1+ (1,-40) [-40|215] "DegC" Vector__XXX
 SG_ DIR_inverterT m0 : 16|8@1+ (1,-40) [-40|215] "DegC" Vector__XXX
 SG_ DIR_statorT m0 : 24|8@1+ (1,-40) [-40|215] "DegC" Vector__XXX
 SG_ DIR_dcCapT m0 : 32|8@1+ (1,-40) [-40|215] "DegC" Vector__XXX
 SG_ DIR_heatsinkT m0 : 40|8@1+ (1,-40) [-40|215] "DegC" Vector__XXX
 SG_ DIR_inverterTpct m0 : 48|8@1+ (0.4,0) [0|100] "%" Vector__XXX
 SG_ DIR_statorTpct m0 : 56|8@1+ (0.4,0) [0|100] "%" Vector__XXX
 SG_ DIR_fluidInTemp m2 : 8|8@1+ (1,-40) [-40|215] "DegC" Vector__XXX
 SG_ DIR_normalFetBurnIn m2 : 16|16@1+ (0.00763,0) [0|500] "Hours" Vector__XXX
 SG_ DIR_additionalFetBurnIn m2 : 32|16@1+ (0.00763,0) [0|500] "Hours" Vector__XXX
 SG_ DIR_currentWeibullMiles m3 : 3|16@1+ (8,0) [0|500000] "miles" Vector__XXX
 SG_ DIR_endOfServiceWeibullMiles m3 : 19|16@1+ (8,0) [0|500000] "miles" Vector__XXX
 SG_ DIR_burnInDamageRatio m3 : 35|9@1+ (0.01,0) [0|5] "1" Vector__XXX
 SG_ DIR_inverterSensorEst m3 : 44|8@1+ (1,-40) [-40|120] "C" Vector__XXX
 SG_ DIR_inverterHS1Est m3 : 52|8@1+ (1,-40) [-40|120] "C" Vector__XXX
 SG_ DIR_initialBurnInVehicleOdometer m4 : 8|32@1+ (0.001,0) [0|4294967.294] "km" Vector__XXX
 SG_ DIR_inverterHS2Est m4 : 40|8@1+ (1,-40) [-40|120] "C" Vector__XXX
 SG_ DIR_inverterInletEst m4 : 48|8@1+ (1,-40) [-40|120] "C" Vector__XXX

BO_ 1495 DIR_thermalControl: 8 DIR
 SG_ DIR_passiveInletTempReq : 0|8@1+ (1,-40) [-40|215] "DegC" Vector__XXX
 SG_ DIR_activeInletTempReq : 8|8@1+ (1,-40) [-40|215] "DegC" Vector__XXX
 SG_ DIR_coolantFlowReq : 16|8@1+ (0.2,0) [0|50] "LPM" Vector__XXX
 SG_ DIR_oilFlowReq : 24|8@1+ (0.1,0) [0|25.4] "LPM" Vector__XXX
 SG_ DIR_criticalFlowReq : 32|1@1+ (1,0) [0|1] "" Vector__XXX
 SG_ DIR_burnInStatus : 33|3@1+ (1,0) [0|7] "" Vector__XXX

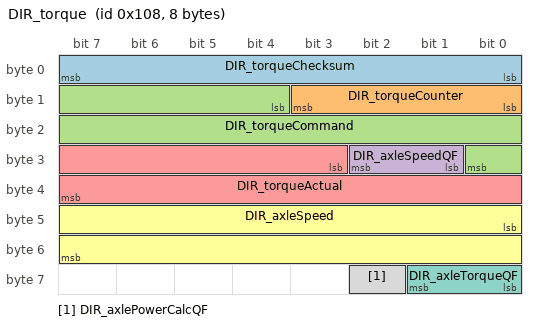
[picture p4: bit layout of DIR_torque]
BO_ 264 DIR_torque: 8 DIR
 SG_ DIR_torqueChecksum : 0|8@1+ (1,0) [0|255] "" Vector__XXX
 SG_ DIR_torqueCounter : 8|4@1+ (1,0) [0|15] "" Vector__XXX
 SG_ DIR_torqueCommand : 12|13@1- (2,0) [-7500|7500] "Nm" Vector__XXX
 SG_ DIR_axleSpeedQF : 25|2@1+ (1,0) [0|3] "" Vector__XXX
 SG_ DIR_torqueActual : 27|13@1- (2,0) [-7500|7500] "Nm" Vector__XXX
 SG_ DIR_axleSpeed : 40|16@1- (0.1,0) [-2750|2750] "RPM" Vector__XXX
 SG_ DIR_axleTorqueQF : 56|2@1+ (1,0) [0|3] "" Vector__XXX
 SG_ DIR_axlePowerCalcQF : 58|1@1+ (1,0) [0|1] "" Vector__XXX

CM_ BO_ 886 "Front drive inverter message: temperature";
CM_ SG_ 886 DIF_tempIndex "Front drive inverter: temp index";
CM_ SG_ 886 DIF_inverterTQF "Detects the Drive Inverter (DI) outlet temperature qualifier.";
CM_ SG_ 886 DIF_pcbT "Front drive inverter: pcb t";
CM_ SG_ 886 DIF_inverterT "Drive Inverter measured outlet temperature";
CM_ SG_ 886 DIF_statorT "Drive Inverter measured stator temperature.";
CM_ SG_ 886 DIF_dcCapT "Front drive inverter: dc cap t";
CM_ SG_ 886 DIF_heatsinkT "Drive Inverter measured heatsink temperature";
CM_ SG_ 886 DIF_inverterTpct "Front drive inverter: inverter tpct";
CM_ SG_ 886 DIF_statorTpct "Front drive inverter: stator tpct";
CM_ SG_ 886 DIF_fluidInTemp "Inlet fluid temperature";
CM_ SG_ 886 DIF_normalFetBurnIn "Front drive inverter: normal fet burn in";
CM_ SG_ 886 DIF_additionalFetBurnIn "Front drive inverter: additional fet burn in";
CM_ SG_ 886 DIF_currentWeibullMiles "Front drive inverter: current weibull miles";
CM_ SG_ 886 DIF_endOfServiceWeibullMiles "Front drive inverter: end of service weibull miles";
CM_ SG_ 886 DIF_burnInDamageRatio "Front drive inverter: burn in damage ratio";
CM_ SG_ 886 DIF_inverterSensorEst "Front drive inverter: inverter sensor est";
CM_ SG_ 886 DIF_inverterHS1Est "Front drive inverter: inverter HS1 est";
CM_ SG_ 886 DIF_initialBurnInVehicleOdometer "Front drive inverter: initial burn in vehicle odometer";
CM_ SG_ 886 DIF_inverterHS2Est "Front drive inverter: inverter HS2 est";
CM_ SG_ 886 DIF_inverterInletEst "Front drive inverter: inverter inlet est";
CM_ BO_ 1367 "Front drive inverter message: thermal control";
CM_ SG_ 1367 DIF_passiveInletTempReq "Front drive inverter: passive inlet temp req";
CM_ SG_ 1367 DIF_activeInletTempReq "Front drive inverter: active inlet temp req";
CM_ SG_ 1367 DIF_coolantFlowReq "Coolant flow requested";
CM_ SG_ 1367 DIF_oilFlowReq "Front drive inverter: oil flow req";
CM_ SG_ 1367 DIF_criticalFlowReq "Front drive inverter: critical flow req";
CM_ SG_ 1367 DIF_burnInStatus "Front drive inverter: burn in status";
CM_ BO_ 390 "Front drive inverter message: torque";
CM_ SG_ 390 DIF_torqueChecksum "Front drive inverter: torque checksum";
CM_ SG_ 390 DIF_torqueCounter "Front drive inverter: torque counter";
CM_ SG_ 390 DIF_torqueCommand "Torque commanded to the drive unit, referred to the axle/wheel";
CM_ SG_ 390 DIF_axleSpeedQF "Front drive inverter: axle speed QF";
CM_ SG_ 390 DIF_torqueActual "Actual torque the drive unit is controlling to referred to the axle/wheel";
CM_ SG_ 390 DIF_axleSpeed "Drive Inverter motor speed normalized at axle level";
CM_ SG_ 390 DIF_axleTorqueQF "Front drive inverter: axle torque QF";
CM_ SG_ 390 DIF_axlePowerCalcQF "Front drive inverter: axle power calc QF";
CM_ BO_ 1445 "Rear drive inverter message: alert log";
CM_ SG_ 1445 DIR_alertID "Rear drive inverter: alert ID";
CM_ SG_ 1445 DIR_alertState "Rear drive inverter: alert state";
CM_ SG_ 1445 DIR_a001_thermalWarning_H "Rear drive inverter: a001 thermal warning h";
CM_ SG_ 1445 DIR_a001_thermalShutdown_H "Rear drive inverter: a001 thermal shutdown h";
CM_ SG_ 1445 DIR_a001_undervoltVL_H "Rear drive inverter: a001 undervolt VL h";
CM_ SG_ 1445 DIR_a001_undervoltVH_H "Rear drive inverter: a001 undervolt VH h";
CM_ SG_ 1445 DIR_a001_sense_H "Rear drive inverter: a001 sense h";
CM_ SG_ 1445 DIR_a001_desat_H "Rear drive inverter: a001 desat h";
CM_ SG_ 1445 DIR_a001_overvoltVL_H "Rear drive inverter: a001 overvolt VL h";
CM_ SG_ 1445 DIR_a001_overvoltVH_H "Rear drive inverter: a001 overvolt VH h";
CM_ SG_ 1445 DIR_a001_undervoltVCC_H "Rear drive inverter: a001 undervolt VCC h";
CM_ SG_ 1445 DIR_a001_asynchStop_H "Rear drive inverter: a001 asynch stop h";
CM_ SG_ 1445 DIR_a001_remoteRegError_H "Rear drive inverter: a001 remote reg error h";
CM_ SG_ 1445 DIR_a001_undervoltVDD_H "Rear drive inverter: a001 undervolt VDD h";
CM_ SG_ 1445 DIR_a001_overvoltVDD_H "Rear drive inverter: a001 overvolt VDD h";
CM_ SG_ 1445 DIR_a001_localRegError_H "Rear drive inverter: a001 local reg error h";
CM_ SG_ 1445 DIR_a001_spiError_H "Rear drive inverter: a001 spi error h";
CM_ SG_ 1445 DIR_a001_deadtimeError_H "Rear drive inverter: a001 deadtime error h";
CM_ SG_ 1445 DIR_a001_thermalWarning_L "Rear drive inverter: a001 thermal warning l";
CM_ SG_ 1445 DIR_a001_thermalShutdown_L "Rear drive inverter: a001 thermal shutdown l";
CM_ SG_ 1445 DIR_a001_undervoltVL_L "Rear drive inverter: a001 undervolt VL l";
CM_ SG_ 1445 DIR_a001_undervoltVH_L "Rear drive inverter: a001 undervolt VH l";
CM_ SG_ 1445 DIR_a001_sense_L "Rear drive inverter: a001 sense l";
CM_ SG_ 1445 DIR_a001_desat_L "Rear drive inverter: a001 desat l";
CM_ SG_ 1445 DIR_a001_overvoltVL_L "Rear drive inverter: a001 overvolt VL l";
CM_ SG_ 1445 DIR_a001_overvoltVH_L "Rear drive inverter: a001 overvolt VH l";
CM_ SG_ 1445 DIR_a001_undervoltVCC_L "Rear drive inverter: a001 undervolt VCC l";
CM_ SG_ 1445 DIR_a001_asynchStop_L "Rear drive inverter: a001 asynch stop l";
CM_ SG_ 1445 DIR_a001_remoteRegError_L "Rear drive inverter: a001 remote reg error l";
CM_ SG_ 1445 DIR_a001_undervoltVDD_L "Rear drive inverter: a001 undervolt VDD l";
CM_ SG_ 1445 DIR_a001_overvoltVDD_L "Rear drive inverter: a001 overvolt VDD l";
CM_ SG_ 1445 DIR_a001_localRegError_L "Rear drive inverter: a001 local reg error l";
CM_ SG_ 1445 DIR_a001_spiError_L "Rear drive inverter: a001 spi error l";
CM_ SG_ 1445 DIR_a001_deadtimeError_L "Rear drive inverter: a001 deadtime error l";
CM_ SG_ 1445 DIR_a001_gateDriveErrCounter "Rear drive inverter: a001 gate drive err counter";
CM_ SG_ 1445 DIR_a001_remoteCommError_H "Rear drive inverter: a001 remote comm error h";
CM_ SG_ 1445 DIR_a001_localCommError_H "Rear drive inverter: a001 local comm error h";
CM_ SG_ 1445 DIR_a001_remoteReset_H "Rear drive inverter: a001 remote reset h";
CM_ SG_ 1445 DIR_a001_localReset_H "Rear drive inverter: a001 local reset h";
CM_ SG_ 1445 DIR_a001_remoteCommError_L "Rear drive inverter: a001 remote comm error l";
CM_ SG_ 1445 DIR_a001_localCommError_L "Rear drive inverter: a001 local comm error l";
CM_ SG_ 1445 DIR_a001_remoteReset_L "Rear drive inverter: a001 remote reset l";
CM_ SG_ 1445 DIR_a001_localReset_L "Rear drive inverter: a001 local reset l";
CM_ SG_ 1445 DIR_a001_faultLine1Gpio_H "Rear drive inverter: a001 fault line1 gpio h";
CM_ SG_ 1445 DIR_a001_faultLine1Gpio_L "Rear drive inverter: a001 fault line1 gpio l";
CM_ SG_ 1445 DIR_a002_thermalWarning_H "Rear drive inverter: a002 thermal warning h";
CM_ SG_ 1445 DIR_a002_thermalShutdown_H "Rear drive inverter: a002 thermal shutdown h";
CM_ SG_ 1445 DIR_a002_undervoltVL_H "Rear drive inverter: a002 undervolt VL h";
CM_ SG_ 1445 DIR_a002_undervoltVH_H "Rear drive inverter: a002 undervolt VH h";
CM_ SG_ 1445 DIR_a002_sense_H "Rear drive inverter: a002 sense h";
CM_ SG_ 1445 DIR_a002_desat_H "Rear drive inverter: a002 desat h";
CM_ SG_ 1445 DIR_a002_overvoltVL_H "Rear drive inverter: a002 overvolt VL h";
CM_ SG_ 1445 DIR_a002_overvoltVH_H "Rear drive inverter: a002 overvolt VH h";
CM_ SG_ 1445 DIR_a002_undervoltVCC_H "Rear drive inverter: a002 undervolt VCC h";
CM_ SG_ 1445 DIR_a002_asynchStop_H "Rear drive inverter: a002 asynch stop h";
CM_ SG_ 1445 DIR_a002_remoteRegError_H "Rear drive inverter: a002 remote reg error h";
CM_ SG_ 1445 DIR_a002_undervoltVDD_H "Rear drive inverter: a002 undervolt VDD h";
CM_ SG_ 1445 DIR_a002_overvoltVDD_H "Rear drive inverter: a002 overvolt VDD h";
CM_ SG_ 1445 DIR_a002_localRegError_H "Rear drive inverter: a002 local reg error h";
CM_ SG_ 1445 DIR_a002_spiError_H "Rear drive inverter: a002 spi error h";
CM_ SG_ 1445 DIR_a002_deadtimeError_H "Rear drive inverter: a002 deadtime error h";
CM_ SG_ 1445 DIR_a002_thermalWarning_L "Rear drive inverter: a002 thermal warning l";
CM_ SG_ 1445 DIR_a002_thermalShutdown_L "Rear drive inverter: a002 thermal shutdown l";
CM_ SG_ 1445 DIR_a002_undervoltVL_L "Rear drive inverter: a002 undervolt VL l";
CM_ SG_ 1445 DIR_a002_undervoltVH_L "Rear drive inverter: a002 undervolt VH l";
CM_ SG_ 1445 DIR_a002_sense_L "Rear drive inverter: a002 sense l";
CM_ SG_ 1445 DIR_a002_desat_L "Rear drive inverter: a002 desat l";
CM_ SG_ 1445 DIR_a002_overvoltVL_L "Rear drive inverter: a002 overvolt VL l";
CM_ SG_ 1445 DIR_a002_overvoltVH_L "Rear drive inverter: a002 overvolt VH l";
CM_ SG_ 1445 DIR_a002_undervoltVCC_L "Rear drive inverter: a002 undervolt VCC l";
CM_ SG_ 1445 DIR_a002_asynchStop_L "Rear drive inverter: a002 asynch stop l";
CM_ SG_ 1445 DIR_a002_remoteRegError_L "Rear drive inverter: a002 remote reg error l";
CM_ SG_ 1445 DIR_a002_undervoltVDD_L "Rear drive inverter: a002 undervolt VDD l";
CM_ SG_ 1445 DIR_a002_overvoltVDD_L "Rear drive inverter: a002 overvolt VDD l";
CM_ SG_ 1445 DIR_a002_localRegError_L "Rear drive inverter: a002 local reg error l";
CM_ SG_ 1445 DIR_a002_spiError_L "Rear drive inverter: a002 spi error l";
CM_ SG_ 1445 DIR_a002_deadtimeError_L "Rear drive inverter: a002 deadtime error l";
CM_ SG_ 1445 DIR_a002_gateDriveErrCounter "Rear drive inverter: a002 gate drive err counter";
CM_ SG_ 1445 DIR_a002_selftestDesat_L "Rear drive inverter: a002 selftest desat l";
CM_ SG_ 1445 DIR_a002_selftestDesat_H "Rear drive inverter: a002 selftest desat h";
CM_ SG_ 1445 DIR_a002_remoteCommError_H "Rear drive inverter: a002 remote comm error h";
CM_ SG_ 1445 DIR_a002_localCommError_H "Rear drive inverter: a002 local comm error h";
CM_ SG_ 1445 DIR_a002_remoteReset_H "Rear drive inverter: a002 remote reset h";
CM_ SG_ 1445 DIR_a002_localReset_H "Rear drive inverter: a002 local reset h";
CM_ SG_ 1445 DIR_a002_remoteCommError_L "Rear drive inverter: a002 remote comm error l";
CM_ SG_ 1445 DIR_a002_localCommError_L "Rear drive inverter: a002 local comm error l";
CM_ SG_ 1445 DIR_a002_remoteReset_L "Rear drive inverter: a002 remote reset l";
CM_ SG_ 1445 DIR_a002_localReset_L "Rear drive inverter: a002 local reset l";
CM_ SG_ 1445 DIR_a002_faultLine1Gpio_H "Rear drive inverter: a002 fault line1 gpio h";
CM_ SG_ 1445 DIR_a002_faultLine1Gpio_L "Rear drive inverter: a002 fault line1 gpio l";
CM_ SG_ 1445 DIR_a003_thermalWarning_H "Rear drive inverter: a003 thermal warning h";
CM_ SG_ 1445 DIR_a003_thermalShutdown_H "Rear drive inverter: a003 thermal shutdown h";
CM_ SG_ 1445 DIR_a003_undervoltVL_H "Rear drive inverter: a003 undervolt VL h";
CM_ SG_ 1445 DIR_a003_undervoltVH_H "Rear drive inverter: a003 undervolt VH h";
CM_ SG_ 1445 DIR_a003_sense_H "Rear drive inverter: a003 sense h";
CM_ SG_ 1445 DIR_a003_desat_H "Rear drive inverter: a003 desat h";
CM_ SG_ 1445 DIR_a003_overvoltVL_H "Rear drive inverter: a003 overvolt VL h";
CM_ SG_ 1445 DIR_a003_overvoltVH_H "Rear drive inverter: a003 overvolt VH h";
CM_ SG_ 1445 DIR_a003_undervoltVCC_H "Rear drive inverter: a003 undervolt VCC h";
CM_ SG_ 1445 DIR_a003_asynchStop_H "Rear drive inverter: a003 asynch stop h";
CM_ SG_ 1445 DIR_a003_remoteRegError_H "Rear drive inverter: a003 remote reg error h";
CM_ SG_ 1445 DIR_a003_undervoltVDD_H "Rear drive inverter: a003 undervolt VDD h";
CM_ SG_ 1445 DIR_a003_overvoltVDD_H "Rear drive inverter: a003 overvolt VDD h";
CM_ SG_ 1445 DIR_a003_localRegError_H "Rear drive inverter: a003 local reg error h";
CM_ SG_ 1445 DIR_a003_spiError_H "Rear drive inverter: a003 spi error h";
CM_ SG_ 1445 DIR_a003_deadtimeError_H "Rear drive inverter: a003 deadtime error h";
CM_ SG_ 1445 DIR_a003_thermalWarning_L "Rear drive inverter: a003 thermal warning l";
CM_ SG_ 1445 DIR_a003_thermalShutdown_L "Rear drive inverter: a003 thermal shutdown l";
CM_ SG_ 1445 DIR_a003_undervoltVL_L "Rear drive inverter: a003 undervolt VL l";
CM_ SG_ 1445 DIR_a003_undervoltVH_L "Rear drive inverter: a003 undervolt VH l";
CM_ SG_ 1445 DIR_a003_sense_L "Rear drive inverter: a003 sense l";
CM_ SG_ 1445 DIR_a003_desat_L "Rear drive inverter: a003 desat l";
CM_ SG_ 1445 DIR_a003_overvoltVL_L "Rear drive inverter: a003 overvolt VL l";
CM_ SG_ 1445 DIR_a003_overvoltVH_L "Rear drive inverter: a003 overvolt VH l";
CM_ SG_ 1445 DIR_a003_undervoltVCC_L "Rear drive inverter: a003 undervolt VCC l";
CM_ SG_ 1445 DIR_a003_asynchStop_L "Rear drive inverter: a003 asynch stop l";
CM_ SG_ 1445 DIR_a003_remoteRegError_L "Rear drive inverter: a003 remote reg error l";
CM_ SG_ 1445 DIR_a003_undervoltVDD_L "Rear drive inverter: a003 undervolt VDD l";
CM_ SG_ 1445 DIR_a003_overvoltVDD_L "Rear drive inverter: a003 overvolt VDD l";
CM_ SG_ 1445 DIR_a003_localRegError_L "Rear drive inverter: a003 local reg error l";
CM_ SG_ 1445 DIR_a003_spiError_L "Rear drive inverter: a003 spi error l";
CM_ SG_ 1445 DIR_a003_deadtimeError_L "Rear drive inverter: a003 deadtime error l";
CM_ SG_ 1445 DIR_a003_gateDriveErrCounter "Rear drive inverter: a003 gate drive err counter";
CM_ SG_ 1445 DIR_a003_selftestDesat_L "Rear drive inverter: a003 selftest desat l";
CM_ SG_ 1445 DIR_a003_selftestDesat_H "Rear drive inverter: a003 selftest desat h";
CM_ SG_ 1445 DIR_a003_remoteCommError_H "Rear drive inverter: a003 remote comm error h";
CM_ SG_ 1445 DIR_a003_localCommError_H "Rear drive inverter: a003 local comm error h";
CM_ SG_ 1445 DIR_a003_remoteReset_H "Rear drive inverter: a003 remote reset h";
CM_ SG_ 1445 DIR_a003_localReset_H "Rear drive inverter: a003 local reset h";
CM_ SG_ 1445 DIR_a003_remoteCommError_L "Rear drive inverter: a003 remote comm error l";
CM_ SG_ 1445 DIR_a003_localCommError_L "Rear drive inverter: a003 local comm error l";
CM_ SG_ 1445 DIR_a003_remoteReset_L "Rear drive inverter: a003 remote reset l";
CM_ SG_ 1445 DIR_a003_localReset_L "Rear drive inverter: a003 local reset l";
CM_ SG_ 1445 DIR_a003_faultLine1Gpio_H "Rear drive inverter: a003 fault line1 gpio h";
CM_ SG_ 1445 DIR_a003_faultLine1Gpio_L "Rear drive inverter: a003 fault line1 gpio l";
CM_ SG_ 1445 DIR_a007_phaseAcurrent "Rear drive inverter: a007 phase acurrent";
CM_ SG_ 1445 DIR_a007_phaseBcurrent "Rear drive inverter: a007 phase bcurrent";
CM_ SG_ 1445 DIR_a007_offsetError "Rear drive inverter: a007 offset error";
CM_ SG_ 1445 DIR_a007_idFdbStdDeviation "Rear drive inverter: a007 id fdb std deviation";
CM_ SG_ 1445 DIR_a007_iqFdbStdDeviation "Rear drive inverter: a007 iq fdb std deviation";
CM_ SG_ 1445 DIR_a007_motorShift "Rear drive inverter: a007 motor shift";
CM_ SG_ 1445 DIR_a007_motorShort "Rear drive inverter: a007 motor short";
CM_ SG_ 1445 DIR_a010_sccReset "Rear drive inverter: a010 scc reset";
CM_ SG_ 1445 DIR_a010_hibernate "Rear drive inverter: a010 hibernate";
CM_ SG_ 1445 DIR_a010_hwBist "Rear drive inverter: a010 hw bist";
CM_ SG_ 1445 DIR_a010_nmiWatchdog "Rear drive inverter: a010 nmi watchdog";
CM_ SG_ 1445 DIR_a010_watchdog "Rear drive inverter: a010 watchdog";
CM_ SG_ 1445 DIR_a010_clockFailNmi "Rear drive inverter: a010 clock fail nmi";
CM_ SG_ 1445 DIR_a010_ramUncErrorNmi "Rear drive inverter: a010 ram unc error nmi";
CM_ SG_ 1445 DIR_a010_flashUncErrorNmi "Rear drive inverter: a010 flash unc error nmi";
CM_ SG_ 1445 DIR_a010_cpu1signMismatchNmi "Rear drive inverter: a010 cpu1sign mismatch nmi";
CM_ SG_ 1445 DIR_a010_cpu2signMismatchNmi "Rear drive inverter: a010 cpu2sign mismatch nmi";
CM_ SG_ 1445 DIR_a010_pieVectErrorNmi "Rear drive inverter: a010 pie vect error nmi";
CM_ SG_ 1445 DIR_a010_sysDbgNmi "Rear drive inverter: a010 sys dbg nmi";
CM_ SG_ 1445 DIR_a010_rlNmi "Rear drive inverter: a010 rl nmi";
CM_ SG_ 1445 DIR_a010_ovfNmi "Rear drive inverter: a010 ovf nmi";
CM_ SG_ 1445 DIR_a010_wdtFlags "Rear drive inverter: a010 wdt flags";
CM_ SG_ 1445 DIR_a011_reason "Rear drive inverter: a011 reason";
CM_ SG_ 1445 DIR_a011_phaseAHigh "Rear drive inverter: a011 phase a high";
CM_ SG_ 1445 DIR_a011_phaseALow "Rear drive inverter: a011 phase a low";
CM_ SG_ 1445 DIR_a011_phaseBHigh "Rear drive inverter: a011 phase b high";
CM_ SG_ 1445 DIR_a011_phaseBLow "Rear drive inverter: a011 phase b low";
CM_ SG_ 1445 DIR_a011_phaseCHigh "Rear drive inverter: a011 phase c high";
CM_ SG_ 1445 DIR_a011_phaseCLow "Rear drive inverter: a011 phase c low";
CM_ SG_ 1445 DIR_a011_regAddress "Rear drive inverter: a011 reg address";
CM_ SG_ 1445 DIR_a011_badGateDriveIC "Rear drive inverter: a011 bad gate drive IC";
CM_ SG_ 1445 DIR_a011_badDataRead "Rear drive inverter: a011 bad data read";
CM_ SG_ 1445 DIR_a011_badDataExpected "Rear drive inverter: a011 bad data expected";
CM_ SG_ 1445 DIR_a011_codeBranch "Rear drive inverter: a011 code branch";
CM_ SG_ 1445 DIR_a012_hvilStatus "Rear drive inverter: a012 hvil status";
CM_ SG_ 1445 DIR_a012_hvilCmVoltage "Rear drive inverter: a012 hvil cm voltage";
CM_ SG_ 1445 DIR_a012_hvilCurrent "Rear drive inverter: a012 hvil current";
CM_ SG_ 1445 DIR_a012_hvilFaultGpio "Rear drive inverter: a012 hvil fault gpio";
CM_ SG_ 1445 DIR_a012_hvilSupplyPinDI "Rear drive inverter: a012 hvil supply pin DI";
CM_ SG_ 1445 DIR_a012_hvilSupplyPinPM "Rear drive inverter: a012 hvil supply pin PM";
CM_ SG_ 1445 DIR_a012_activeDisOn3V3 "Rear drive inverter: a012 active dis on3 V3";
CM_ SG_ 1445 DIR_a012_hvilHeaderFault "Rear drive inverter: a012 hvil header fault";
CM_ SG_ 1445 DIR_a013_address "Rear drive inverter: a013 address";
CM_ SG_ 1445 DIR_a013_errorType "Rear drive inverter: a013 error type";
CM_ SG_ 1445 DIR_a014_motorSpeed "Rear drive inverter: a014 motor speed";
CM_ SG_ 1445 DIR_a014_adState "Rear drive inverter: a014 ad state";
CM_ SG_ 1445 DIR_a014_torqueCommandFwd "Rear drive inverter: a014 torque command fwd";
CM_ SG_ 1445 DIR_a014_brakeMasterCylPress "Rear drive inverter: a014 brake master cyl press";
CM_ SG_ 1445 DIR_a014_rmsTorqueError "Rear drive inverter: a014 rms torque error";
CM_ SG_ 1445 DIR_a014_tcEnabled "Rear drive inverter: a014 tc enabled";
CM_ SG_ 1445 DIR_a016_newSafeState "Rear drive inverter: a016 new safe state";
CM_ SG_ 1445 DIR_a016_oldSafeState "Rear drive inverter: a016 old safe state";
CM_ SG_ 1445 DIR_a016_gateDriveFaultLine "Rear drive inverter: a016 gate drive fault line";
CM_ SG_ 1445 DIR_a016_ascMonitor "Rear drive inverter: a016 asc monitor";
CM_ SG_ 1445 DIR_a016_uncontrolledRegenZone "Rear drive inverter: a016 uncontrolled regen zone";
CM_ SG_ 1445 DIR_a016_pedalMonitorPreWatchdog "Rear drive inverter: a016 pedal monitor pre watchdog";
CM_ SG_ 1445 DIR_a016_motorRPM "Rear drive inverter: a016 motor RPM";
CM_ SG_ 1445 DIR_a016_torqueMotor "Rear drive inverter: a016 torque motor";
CM_ SG_ 1445 DIR_a016_safetyICfaultLine "Rear drive inverter: a016 safety i cfault line";
CM_ SG_ 1445 DIR_a016_triggerEvent "Rear drive inverter: a016 trigger event";
CM_ SG_ 1445 DIR_a024_vBat "Rear drive inverter: a024 v bat";
CM_ SG_ 1445 DIR_a024_failReason "Rear drive inverter: a024 fail reason";
CM_ SG_ 1445 DIR_a024_state "Rear drive inverter: a024 state";
CM_ SG_ 1445 DIR_a024_Ia "Rear drive inverter: a024 ia";
CM_ SG_ 1445 DIR_a024_Ib "Rear drive inverter: a024 ib";
CM_ SG_ 1445 DIR_a024_maxCurrMagSqrd "Rear drive inverter: a024 max curr mag sqrd";
CM_ SG_ 1445 DIR_a024_rotorAngle "Rear drive inverter: a024 rotor angle";
CM_ SG_ 1445 DIR_a025_Ia "Rear drive inverter: a025 ia";
CM_ SG_ 1445 DIR_a025_torqueMotor "Rear drive inverter: a025 torque motor";
CM_ SG_ 1445 DIR_a025_motorSpeed "Rear drive inverter: a025 motor speed";
CM_ SG_ 1445 DIR_a026_Ib "Rear drive inverter: a026 ib";
CM_ SG_ 1445 DIR_a026_torqueMotor "Rear drive inverter: a026 torque motor";
CM_ SG_ 1445 DIR_a026_motorSpeed "Rear drive inverter: a026 motor speed";
CM_ SG_ 1445 DIR_a027_Ic "Rear drive inverter: a027 ic";
CM_ SG_ 1445 DIR_a027_torqueMotor "Rear drive inverter: a027 torque motor";
CM_ SG_ 1445 DIR_a027_motorSpeed "Rear drive inverter: a027 motor speed";
CM_ SG_ 1445 DIR_a028_phaseAirms "Rear drive inverter: a028 phase airms";
CM_ SG_ 1445 DIR_a028_iArmsTorque "Rear drive inverter: a028 i arms torque";
CM_ SG_ 1445 DIR_a028_iArmsSpeed "Rear drive inverter: a028 i arms speed";
CM_ SG_ 1445 DIR_a029_phaseBirms "Rear drive inverter: a029 phase birms";
CM_ SG_ 1445 DIR_a029_iBrmsTorque "Rear drive inverter: a029 i brms torque";
CM_ SG_ 1445 DIR_a029_iBrmsSpeed "Rear drive inverter: a029 i brms speed";
CM_ SG_ 1445 DIR_a030_phaseCirms "Rear drive inverter: a030 phase cirms";
CM_ SG_ 1445 DIR_a030_iCrmsTorque "Rear drive inverter: a030 i crms torque";
CM_ SG_ 1445 DIR_a030_iCrmsSpeed "Rear drive inverter: a030 i crms speed";
CM_ SG_ 1445 DIR_a031_phaseAoffset "Rear drive inverter: a031 phase aoffset";
CM_ SG_ 1445 DIR_a032_phaseBoffset "Rear drive inverter: a032 phase boffset";
CM_ SG_ 1445 DIR_a033_phaseAcurrent "Rear drive inverter: a033 phase acurrent";
CM_ SG_ 1445 DIR_a033_deltaIa "Rear drive inverter: a033 delta ia";
CM_ SG_ 1445 DIR_a033_vRefIa "Rear drive inverter: a033 v ref ia";
CM_ SG_ 1445 DIR_a034_phaseBcurrent "Rear drive inverter: a034 phase bcurrent";
CM_ SG_ 1445 DIR_a034_deltaIb "Rear drive inverter: a034 delta ib";
CM_ SG_ 1445 DIR_a034_vRefIb "Rear drive inverter: a034 v ref ib";
CM_ SG_ 1445 DIR_a035_phaseAerror "Rear drive inverter: a035 phase aerror";
CM_ SG_ 1445 DIR_a035_phaseBerror "Rear drive inverter: a035 phase berror";
CM_ SG_ 1445 DIR_a035_phaseCerror "Rear drive inverter: a035 phase cerror";
CM_ SG_ 1445 DIR_a035_standbyCurrent "Rear drive inverter: a035 standby current";
CM_ SG_ 1445 DIR_a035_unbalancedCurrent "Rear drive inverter: a035 unbalanced current";
CM_ SG_ 1445 DIR_a035_wontMoveCurrent "Rear drive inverter: a035 wont move current";
CM_ SG_ 1445 DIR_a035_reportingPhase "Rear drive inverter: a035 reporting phase";
CM_ SG_ 1445 DIR_a035_noDriveCurrent "Rear drive inverter: a035 no drive current";
CM_ SG_ 1445 DIR_a035_phaseDifference "Rear drive inverter: a035 phase difference";
CM_ SG_ 1445 DIR_a035_phaseCurrent "Rear drive inverter: a035 phase current";
CM_ SG_ 1445 DIR_a035_frequency "Rear drive inverter: a035 frequency";
CM_ SG_ 1445 DIR_a036_busVoltage "Rear drive inverter: a036 bus voltage";
CM_ SG_ 1445 DIR_a036_busHighLimit "Rear drive inverter: a036 bus high limit";
CM_ SG_ 1445 DIR_a037_busVoltage "Rear drive inverter: a037 bus voltage";
CM_ SG_ 1445 DIR_a037_busLowLimit "Rear drive inverter: a037 bus low limit";
CM_ SG_ 1445 DIR_a038_vBMS "Rear drive inverter: a038 v BMS";
CM_ SG_ 1445 DIR_a038_vBat "Rear drive inverter: a038 v bat";
CM_ SG_ 1445 DIR_a038_iBat "Rear drive inverter: a038 i bat";
CM_ SG_ 1445 DIR_a038_reason "Rear drive inverter: a038 reason";
CM_ SG_ 1445 DIR_a040_torque "Rear drive inverter: a040 torque";
CM_ SG_ 1445 DIR_a040_capability "Rear drive inverter: a040 capability";
CM_ SG_ 1445 DIR_a040_power "Rear drive inverter: a040 power";
CM_ SG_ 1445 DIR_a040_status "Rear drive inverter: a040 status";
CM_ SG_ 1445 DIR_a040_capability2 "Rear drive inverter: a040 capability2";
CM_ SG_ 1445 DIR_a040_hvStatus "Rear drive inverter: a040 hv status";
CM_ SG_ 1445 DIR_a040_temperature "Rear drive inverter: a040 temperature";
CM_ SG_ 1445 DIR_a041_uartRxDataAvailable "Rear drive inverter: a041 uart rx data available";
CM_ SG_ 1445 DIR_a041_SDC_status_MIA "Rear drive inverter: a041 SDC status MIA";
CM_ SG_ 1445 DIR_a041_diUartRxVersion "Rear drive inverter: a041 di uart rx version";
CM_ SG_ 1445 DIR_a041_sdcUartRxVersion "Rear drive inverter: a041 sdc uart rx version";
CM_ SG_ 1445 DIR_a043_outletTemp "Rear drive inverter: a043 outlet temp";
CM_ SG_ 1445 DIR_a044_outletTemp "Rear drive inverter: a044 outlet temp";
CM_ SG_ 1445 DIR_a045_inletTemp "Rear drive inverter: a045 inlet temp";
CM_ SG_ 1445 DIR_a045_outletTemp "Rear drive inverter: a045 outlet temp";
CM_ SG_ 1445 DIR_a045_heatsinkTemp "Rear drive inverter: a045 heatsink temp";
CM_ SG_ 1445 DIR_a045_outletTempSlope "Rear drive inverter: a045 outlet temp slope";
CM_ SG_ 1445 DIR_a046_statorTemp1 "Rear drive inverter: a046 stator temp1";
CM_ SG_ 1445 DIR_a046_statorTemp2 "Rear drive inverter: a046 stator temp2";
CM_ SG_ 1445 DIR_a047_statorTemp1 "Rear drive inverter: a047 stator temp1";
CM_ SG_ 1445 DIR_a047_statorTslope1 "Rear drive inverter: a047 stator tslope1";
CM_ SG_ 1445 DIR_a050_statorTemp1 "Rear drive inverter: a050 stator temp1";
CM_ SG_ 1445 DIR_a050_statorTemp2 "Rear drive inverter: a050 stator temp2";
CM_ SG_ 1445 DIR_a052_torque "Rear drive inverter: a052 torque";
CM_ SG_ 1445 DIR_a052_capability "Rear drive inverter: a052 capability";
CM_ SG_ 1445 DIR_a052_power "Rear drive inverter: a052 power";
CM_ SG_ 1445 DIR_a052_status "Rear drive inverter: a052 status";
CM_ SG_ 1445 DIR_a052_capability2 "Rear drive inverter: a052 capability2";
CM_ SG_ 1445 DIR_a052_hvStatus "Rear drive inverter: a052 hv status";
CM_ SG_ 1445 DIR_a052_temperature "Rear drive inverter: a052 temperature";
CM_ SG_ 1445 DIR_a054_outletTemp "Rear drive inverter: a054 outlet temp";
CM_ SG_ 1445 DIR_a054_heatsinkTemp "Rear drive inverter: a054 heatsink temp";
CM_ SG_ 1445 DIR_a055_parameterDI "Rear drive inverter: a055 parameter DI";
CM_ SG_ 1445 DIR_a055_parameterPM "Rear drive inverter: a055 parameter PM";
CM_ SG_ 1445 DIR_a055_torqueType "Rear drive inverter: a055 torque type";
CM_ SG_ 1445 DIR_a055_motorRPM "Rear drive inverter: a055 motor RPM";
CM_ SG_ 1445 DIR_a056_pcbTemp "Rear drive inverter: a056 pcb temp";
CM_ SG_ 1445 DIR_a057_pcbTemp "Rear drive inverter: a057 pcb temp";
CM_ SG_ 1445 DIR_a058_pcbTemp "Rear drive inverter: a058 pcb temp";
CM_ SG_ 1445 DIR_a058_outletTemp "Rear drive inverter: a058 outlet temp";
CM_ SG_ 1445 DIR_a058_heatsinkTemp "Rear drive inverter: a058 heatsink temp";
CM_ SG_ 1445 DIR_a058_pcbTempSlope "Rear drive inverter: a058 pcb temp slope";
CM_ SG_ 1445 DIR_a059_heatsinkTemp "Rear drive inverter: a059 heatsink temp";
CM_ SG_ 1445 DIR_a060_heatsinkTemp "Rear drive inverter: a060 heatsink temp";
CM_ SG_ 1445 DIR_a061_sensor "Rear drive inverter: a061 sensor";
CM_ SG_ 1445 DIR_a061_reason "Rear drive inverter: a061 reason";
CM_ SG_ 1445 DIR_a061_phTemp "Rear drive inverter: a061 ph temp";
CM_ SG_ 1445 DIR_a061_otherTemp "Rear drive inverter: a061 other temp";
CM_ SG_ 1445 DIR_a062_limpReason "Rear drive inverter: a062 limp reason";
CM_ SG_ 1445 DIR_a063_BB_status "Rear drive inverter: a063 BB status";
CM_ SG_ 1445 DIR_a064_interventionType "Rear drive inverter: a064 intervention type";
CM_ SG_ 1445 DIR_a064_torqueCmdState "Rear drive inverter: a064 torque cmd state";
CM_ SG_ 1445 DIR_a066_badValue1 "Rear drive inverter: a066 bad value1";
CM_ SG_ 1445 DIR_a066_badValue2 "Rear drive inverter: a066 bad value2";
CM_ SG_ 1445 DIR_a066_canID "Rear drive inverter: a066 can ID";
CM_ SG_ 1445 DIR_a066_errorType "Rear drive inverter: a066 error type";
CM_ SG_ 1445 DIR_a069_motorSpeed "Rear drive inverter: a069 motor speed";
CM_ SG_ 1445 DIR_a069_rotorCoolingPower "Rear drive inverter: a069 rotor cooling power";
CM_ SG_ 1445 DIR_a069_rotorMagnetTemp "Rear drive inverter: a069 rotor magnet temp";
CM_ SG_ 1445 DIR_a069_fittedTorqueLimit "Rear drive inverter: a069 fitted torque limit";
CM_ SG_ 1445 DIR_a072_reason "Rear drive inverter: a072 reason";
CM_ SG_ 1445 DIR_a073_motorSpeedrpm "Rear drive inverter: a073 motor speedrpm";
CM_ SG_ 1445 DIR_a075_motorSpeed "Rear drive inverter: a075 motor speed";
CM_ SG_ 1445 DIR_a075_absSpeed "Rear drive inverter: a075 abs speed";
CM_ SG_ 1445 DIR_a076_lvSupplyV "Rear drive inverter: a076 lv supply v";
CM_ SG_ 1445 DIR_a077_lvSupplyV "Rear drive inverter: a077 lv supply v";
CM_ SG_ 1445 DIR_a078_adcRefChan "Rear drive inverter: a078 adc ref chan";
CM_ SG_ 1445 DIR_a078_adcRefLowAvg "Rear drive inverter: a078 adc ref low avg";
CM_ SG_ 1445 DIR_a079_adcRefChan "Rear drive inverter: a079 adc ref chan";
CM_ SG_ 1445 DIR_a079_adcRefHighAvg "Rear drive inverter: a079 adc ref high avg";
CM_ SG_ 1445 DIR_a087_gtwCarConfig "Rear drive inverter: a087 gtw car config";
CM_ SG_ 1445 DIR_a087_gtwTime "Rear drive inverter: a087 gtw time";
CM_ SG_ 1445 DIR_a087_gtwUpdateStatus "Rear drive inverter: a087 gtw update status";
CM_ SG_ 1445 DIR_a087_gearControl "Rear drive inverter: a087 gear control";
CM_ SG_ 1445 DIR_a087_carState "Rear drive inverter: a087 car state";
CM_ SG_ 1445 DIR_a090_reason "Rear drive inverter: a090 reason";
CM_ SG_ 1445 DIR_a090_systemState "Rear drive inverter: a090 system state";
CM_ SG_ 1445 DIR_a090_state "Rear drive inverter: a090 state";
CM_ SG_ 1445 DIR_a090_locState "Rear drive inverter: a090 loc state";
CM_ SG_ 1445 DIR_a090_state2 "Rear drive inverter: a090 state2";
CM_ SG_ 1445 DIR_a090_state4 "Rear drive inverter: a090 state4";
CM_ SG_ 1445 DIR_a091_ESP_brakeTorque "Rear drive inverter: a091 ESP brake torque";
CM_ SG_ 1445 DIR_a091_ESP_wheelSpeeds "Rear drive inverter: a091 ESP wheel speeds";
CM_ SG_ 1445 DIR_a091_ESP_wheelRotation "Rear drive inverter: a091 ESP wheel rotation";
CM_ SG_ 1445 DIR_a091_ESP_motorLimits "Rear drive inverter: a091 ESP motor limits";
CM_ SG_ 1445 DIR_a091_ESP_offsets "Rear drive inverter: a091 ESP offsets";
CM_ SG_ 1445 DIR_a091_ESP_status "Rear drive inverter: a091 ESP status";
CM_ SG_ 1445 DIR_a091_ESP_party3 "Rear drive inverter: a091 ESP party3";
CM_ SG_ 1445 DIR_a092_bmsStatus "Rear drive inverter: a092 bms status";
CM_ SG_ 1445 DIR_a092_bmsDriveLimits "Rear drive inverter: a092 bms drive limits";
CM_ SG_ 1445 DIR_a092_bmsHvBusStatus "Rear drive inverter: a092 bms hv bus status";
CM_ SG_ 1445 DIR_a092_bmsPowerAvailable "Rear drive inverter: a092 bms power available";
CM_ SG_ 1445 DIR_a092_bmsBmbMinMax "Rear drive inverter: a092 bms bmb min max";
CM_ SG_ 1445 DIR_a092_bmsSocStatus "Rear drive inverter: a092 bms soc status";
CM_ SG_ 1445 DIR_a092_bmsThermalStatus "Rear drive inverter: a092 bms thermal status";
CM_ SG_ 1445 DIR_a092_bmsCtrStatus "Rear drive inverter: a092 bms ctr status";
CM_ SG_ 1445 DIR_a092_bmsVoltageRegGain "Rear drive inverter: a092 bms voltage reg gain";
CM_ SG_ 1445 DIR_a092_bmsPackConfig "Rear drive inverter: a092 bms pack config";
CM_ SG_ 1445 DIR_a092_bmsSystemStatus "Rear drive inverter: a092 bms system status";
CM_ SG_ 1445 DIR_a094_canID "Rear drive inverter: a094 can ID";
CM_ SG_ 1445 DIR_a094_errorType "Rear drive inverter: a094 error type";
CM_ SG_ 1445 DIR_a094_badValue1 "Rear drive inverter: a094 bad value1";
CM_ SG_ 1445 DIR_a094_badValue2 "Rear drive inverter: a094 bad value2";
CM_ SG_ 1445 DIR_a096_const_fast "Rear drive inverter: a096 const fast";
CM_ SG_ 1445 DIR_a096_text_fast "Rear drive inverter: a096 text fast";
CM_ SG_ 1445 DIR_a096_text_flash "Rear drive inverter: a096 text flash";
CM_ SG_ 1445 DIR_a096_mem_data "Rear drive inverter: a096 mem data";
CM_ SG_ 1445 DIR_a096_mem_regs "Rear drive inverter: a096 mem regs";
CM_ SG_ 1445 DIR_a096_boot_flash "Rear drive inverter: a096 boot flash";
CM_ SG_ 1445 DIR_a096_word1 "Rear drive inverter: a096 word1";
CM_ SG_ 1445 DIR_a096_word2 "Rear drive inverter: a096 word2";
CM_ SG_ 1445 DIR_a097_errorType "Rear drive inverter: a097 error type";
CM_ SG_ 1445 DIR_a097_lineNumber "Rear drive inverter: a097 line number";
CM_ SG_ 1445 DIR_a097_argument "Rear drive inverter: a097 argument";
CM_ SG_ 1445 DIR_a098_pwmCount "Rear drive inverter: a098 pwm count";
CM_ SG_ 1445 DIR_a098_fluxState "Rear drive inverter: a098 flux state";
CM_ SG_ 1445 DIR_a103_fluidTorDeltaT "Rear drive inverter: a103 fluid tor delta t";
CM_ SG_ 1445 DIR_a103_noFlowDetected "Rear drive inverter: a103 no flow detected";
CM_ SG_ 1445 DIR_a103_lowFlowDetected "Rear drive inverter: a103 low flow detected";
CM_ SG_ 1445 DIR_a103_fluidImplausible "Rear drive inverter: a103 fluid implausible";
CM_ SG_ 1445 DIR_a103_inverterTemp "Rear drive inverter: a103 inverter temp";
CM_ SG_ 1445 DIR_a103_rmsCurrent "Rear drive inverter: a103 rms current";
CM_ SG_ 1445 DIR_a103_ambientTemp "Rear drive inverter: a103 ambient temp";
CM_ SG_ 1445 DIR_a103_sensorTempEst "Rear drive inverter: a103 sensor temp est";
CM_ SG_ 1445 DIR_a107_fpgaVersion "Rear drive inverter: a107 fpga version";
CM_ SG_ 1445 DIR_a107_fpgaBootVersion "Rear drive inverter: a107 fpga boot version";
CM_ SG_ 1445 DIR_a107_fpgaMasterActive "Rear drive inverter: a107 fpga master active";
CM_ SG_ 1445 DIR_a107_fpgaFaultActive "Rear drive inverter: a107 fpga fault active";
CM_ SG_ 1445 DIR_a107_fpgaWarningActive "Rear drive inverter: a107 fpga warning active";
CM_ SG_ 1445 DIR_a108_fromState "Rear drive inverter: a108 from state";
CM_ SG_ 1445 DIR_a108_toState "Rear drive inverter: a108 to state";
CM_ SG_ 1445 DIR_a108_blockingAlert "Rear drive inverter: a108 blocking alert";
CM_ SG_ 1445 DIR_a110_EPBL_status "Rear drive inverter: a110 EPBL status";
CM_ SG_ 1445 DIR_a110_EPBR_status "Rear drive inverter: a110 EPBR status";
CM_ SG_ 1445 DIR_a111_phAcalib "Rear drive inverter: a111 ph acalib";
CM_ SG_ 1445 DIR_a111_phBcalib "Rear drive inverter: a111 ph bcalib";
CM_ SG_ 1445 DIR_a112_phaseAcurrent "Rear drive inverter: a112 phase acurrent";
CM_ SG_ 1445 DIR_a112_phaseBcurrent "Rear drive inverter: a112 phase bcurrent";
CM_ SG_ 1445 DIR_a113_heatsink1Temp "Rear drive inverter: a113 heatsink1 temp";
CM_ SG_ 1445 DIR_a113_heatsink2Temp "Rear drive inverter: a113 heatsink2 temp";
CM_ SG_ 1445 DIR_a113_heatsink3Temp "Rear drive inverter: a113 heatsink3 temp";
CM_ SG_ 1445 DIR_a115_faultAddress "Rear drive inverter: a115 fault address";
CM_ SG_ 1445 DIR_a115_isWriteNotRead "Rear drive inverter: a115 is write not read";
CM_ SG_ 1445 DIR_a117_torque "Rear drive inverter: a117 torque";
CM_ SG_ 1445 DIR_a117_slaveCommand "Rear drive inverter: a117 slave command";
CM_ SG_ 1445 DIR_a117_power "Rear drive inverter: a117 power";
CM_ SG_ 1445 DIR_a117_slaveCommand2 "Rear drive inverter: a117 slave command2";
CM_ SG_ 1445 DIR_a117_speed "Rear drive inverter: a117 speed";
CM_ SG_ 1445 DIR_a117_chassisControl "Rear drive inverter: a117 chassis control";
CM_ SG_ 1445 DIR_a117_systemStatus "Rear drive inverter: a117 system status";
CM_ SG_ 1445 DIR_a117_temperature "Rear drive inverter: a117 temperature";
CM_ SG_ 1445 DIR_a117_vehicle "Rear drive inverter: a117 vehicle";
CM_ SG_ 1445 DIR_a117_AddTcLimit "Rear drive inverter: a117 add tc limit";
CM_ SG_ 1445 DIR_a117_dixCommand "Rear drive inverter: a117 dix command";
CM_ SG_ 1445 DIR_a117_odometerStatus "Rear drive inverter: a117 odometer status";
CM_ SG_ 1445 DIR_a117_maxRatedPower "Rear drive inverter: a117 max rated power";
CM_ SG_ 1445 DIR_a119_hvpFaults "Rear drive inverter: a119 hvp faults";
CM_ SG_ 1445 DIR_a120_dcLinkInfo "Rear drive inverter: a120 dc link info";
CM_ SG_ 1445 DIR_a121_badRegReason "Rear drive inverter: a121 bad reg reason";
CM_ SG_ 1445 DIR_a121_torqueDelta "Rear drive inverter: a121 torque delta";
CM_ SG_ 1445 DIR_a121_badCurrent "Rear drive inverter: a121 bad current";
CM_ SG_ 1445 DIR_a121_badFlux "Rear drive inverter: a121 bad flux";
CM_ SG_ 1445 DIR_a123_lossReason "Rear drive inverter: a123 loss reason";
CM_ SG_ 1445 DIR_a123_busVoltage "Rear drive inverter: a123 bus voltage";
CM_ SG_ 1445 DIR_a123_badFlux "Rear drive inverter: a123 bad flux";
CM_ SG_ 1445 DIR_a123_lossRequest "Rear drive inverter: a123 loss request";
CM_ SG_ 1445 DIR_a123_badCurrent "Rear drive inverter: a123 bad current";
CM_ SG_ 1445 DIR_a123_motorRPM "Rear drive inverter: a123 motor RPM";
CM_ SG_ 1445 DIR_a123_varianceD "Rear drive inverter: a123 variance d";
CM_ SG_ 1445 DIR_a123_varianceQ "Rear drive inverter: a123 variance q";
CM_ SG_ 1445 DIR_a126_limpReason "Rear drive inverter: a126 limp reason";
CM_ SG_ 1445 DIR_a127_gpoReason "Rear drive inverter: a127 gpo reason";
CM_ SG_ 1445 DIR_a127_temp "Rear drive inverter: a127 temp";
CM_ SG_ 1445 DIR_a133_capacitorTemp "Rear drive inverter: a133 capacitor temp";
CM_ SG_ 1445 DIR_a133_badValue1 "Rear drive inverter: a133 bad value1";
CM_ SG_ 1445 DIR_a133_badValue2 "Rear drive inverter: a133 bad value2";
CM_ SG_ 1445 DIR_a134_wheelSpeedDiffFrL "Rear drive inverter: a134 wheel speed diff fr l";
CM_ SG_ 1445 DIR_a134_wheelSpeedDiffFrR "Rear drive inverter: a134 wheel speed diff fr r";
CM_ SG_ 1445 DIR_a134_wheelSpeedDiffReL "Rear drive inverter: a134 wheel speed diff re l";
CM_ SG_ 1445 DIR_a134_wheelSpeedDiffReR "Rear drive inverter: a134 wheel speed diff re r";
CM_ SG_ 1445 DIR_a136_spiError_BL "Rear drive inverter: a136 spi error BL";
CM_ SG_ 1445 DIR_a136_crcError_BL "Rear drive inverter: a136 crc error BL";
CM_ SG_ 1445 DIR_a136_busyError_BL "Rear drive inverter: a136 busy error BL";
CM_ SG_ 1445 DIR_a136_spiError_BH "Rear drive inverter: a136 spi error BH";
CM_ SG_ 1445 DIR_a136_crcError_BH "Rear drive inverter: a136 crc error BH";
CM_ SG_ 1445 DIR_a136_busyError_BH "Rear drive inverter: a136 busy error BH";
CM_ SG_ 1445 DIR_a136_spiError_CL "Rear drive inverter: a136 spi error CL";
CM_ SG_ 1445 DIR_a136_crcError_CL "Rear drive inverter: a136 crc error CL";
CM_ SG_ 1445 DIR_a136_busyError_CL "Rear drive inverter: a136 busy error CL";
CM_ SG_ 1445 DIR_a136_spiError_CH "Rear drive inverter: a136 spi error CH";
CM_ SG_ 1445 DIR_a136_crcError_CH "Rear drive inverter: a136 crc error CH";
CM_ SG_ 1445 DIR_a136_busyError_CH "Rear drive inverter: a136 busy error CH";
CM_ SG_ 1445 DIR_a136_spiError_AL "Rear drive inverter: a136 spi error AL";
CM_ SG_ 1445 DIR_a136_crcError_AL "Rear drive inverter: a136 crc error AL";
CM_ SG_ 1445 DIR_a136_busyError_AL "Rear drive inverter: a136 busy error AL";
CM_ SG_ 1445 DIR_a136_spiError_AH "Rear drive inverter: a136 spi error AH";
CM_ SG_ 1445 DIR_a136_crcError_AH "Rear drive inverter: a136 crc error AH";
CM_ SG_ 1445 DIR_a136_busyError_AH "Rear drive inverter: a136 busy error AH";
CM_ SG_ 1445 DIR_a144_autopilot "Rear drive inverter: a144 autopilot";
CM_ SG_ 1445 DIR_a144_chassisType "Rear drive inverter: a144 chassis type";
CM_ SG_ 1445 DIR_a144_drivetrainType "Rear drive inverter: a144 drivetrain type";
CM_ SG_ 1445 DIR_a144_packEnergy "Rear drive inverter: a144 pack energy";
CM_ SG_ 1445 DIR_a144_packPerformanceDeviatio "Rear drive inverter: a144 pack performance deviation";
CM_ SG_ 1445 DIR_a144_performancePackage "Rear drive inverter: a144 performance package";
CM_ SG_ 1445 DIR_a144_vdcType "Rear drive inverter: a144 vdc type";
CM_ SG_ 1445 DIR_a144_brakeHWType "Rear drive inverter: a144 brake HW type";
CM_ SG_ 1445 DIR_a144_inverterHardware "Rear drive inverter: a144 inverter hardware";
CM_ SG_ 1445 DIR_a144_cabinPTCHeaterType "Rear drive inverter: a144 cabin PTC heater type";
CM_ SG_ 1445 DIR_a144_frunkLatchType "Rear drive inverter: a144 frunk latch type";
CM_ SG_ 1445 DIR_a144_platformMaxBusVoltage "Rear drive inverter: a144 platform max bus voltage";
CM_ SG_ 1445 DIR_a144_oilPump1HwType "Rear drive inverter: a144 oil pump1 hw type";
CM_ SG_ 1445 DIR_a144_oilPump2HwType "Rear drive inverter: a144 oil pump2 hw type";
CM_ SG_ 1445 DIR_a144_heatsinkType "Rear drive inverter: a144 heatsink type";
CM_ SG_ 1445 DIR_a144_softPerformanceLimit "Rear drive inverter: a144 soft performance limit";
CM_ SG_ 1445 DIR_a144_brakeActuationType "Rear drive inverter: a144 brake actuation type";
CM_ SG_ 1445 DIR_a144_dasHw "Rear drive inverter: a144 das hw";
CM_ SG_ 1445 DIR_a144_chassisSubType "Rear drive inverter: a144 chassis sub type";
CM_ SG_ 1445 DIR_a147_overtorque1UsedCount "Rear drive inverter: a147 overtorque1 used count";
CM_ SG_ 1445 DIR_a147_overtorque2UsedCount "Rear drive inverter: a147 overtorque2 used count";
CM_ SG_ 1445 DIR_a147_accumulatedWear "Rear drive inverter: a147 accumulated wear";
CM_ SG_ 1445 DIR_a147_wearIsValid "Rear drive inverter: a147 wear is valid";
CM_ SG_ 1445 DIR_a149_flow "Rear drive inverter: a149 flow";
CM_ SG_ 1445 DIR_a149_voltage "Rear drive inverter: a149 voltage";
CM_ SG_ 1445 DIR_a149_temperature "Rear drive inverter: a149 temperature";
CM_ SG_ 1445 DIR_a149_state "Rear drive inverter: a149 state";
CM_ SG_ 1445 DIR_a149_fluidTempSNA "Rear drive inverter: a149 fluid temp SNA";
CM_ SG_ 1445 DIR_a149_insufficientFlow "Rear drive inverter: a149 insufficient flow";
CM_ SG_ 1445 DIR_a149_motorOpenPhase "Rear drive inverter: a149 motor open phase";
CM_ SG_ 1445 DIR_a149_motorShorted "Rear drive inverter: a149 motor shorted";
CM_ SG_ 1445 DIR_a149_motorFlowSNA "Rear drive inverter: a149 motor flow SNA";
CM_ SG_ 1445 DIR_a149_responseError "Rear drive inverter: a149 response error";
CM_ SG_ 1445 DIR_a149_pcbaID "Rear drive inverter: a149 pcba ID";
CM_ SG_ 1445 DIR_a150_vBatRawMinusFiltered "Rear drive inverter: a150 v bat raw minus filtered";
CM_ SG_ 1445 DIR_a150_vBatFilteredRate "Rear drive inverter: a150 v bat filtered rate";
CM_ SG_ 1445 DIR_a150_elapsedMs "Rear drive inverter: a150 elapsed ms";
CM_ SG_ 1445 DIR_a150_energy "Rear drive inverter: a150 energy";
CM_ SG_ 1445 DIR_a152_errorType "Rear drive inverter: a152 error type";
CM_ SG_ 1445 DIR_a152_frameId "Rear drive inverter: a152 frame id";
CM_ SG_ 1445 DIR_a152_badValue "Rear drive inverter: a152 bad value";
CM_ SG_ 1445 DIR_a152_expectedValue "Rear drive inverter: a152 expected value";
CM_ SG_ 1445 DIR_a153_oilFlow "Rear drive inverter: a153 oil flow";
CM_ SG_ 1445 DIR_a153_oilTemperature "Rear drive inverter: a153 oil temperature";
CM_ SG_ 1445 DIR_a153_phaseCurrent "Rear drive inverter: a153 phase current";
CM_ SG_ 1445 DIR_a153_dcVoltage "Rear drive inverter: a153 dc voltage";
CM_ SG_ 1445 DIR_a153_lowPressPlausibility "Rear drive inverter: a153 low press plausibility";
CM_ SG_ 1445 DIR_a153_state "Rear drive inverter: a153 state";
CM_ SG_ 1445 DIR_a153_oilPumpAlert "Rear drive inverter: a153 oil pump alert";
CM_ SG_ 1445 DIR_a153_reason "Rear drive inverter: a153 reason";
CM_ SG_ 1445 DIR_a154_motorRPM "Rear drive inverter: a154 motor RPM";
CM_ SG_ 1445 DIR_a154_phaseError "Rear drive inverter: a154 phase error";
CM_ SG_ 1445 DIR_a154_commonGain "Rear drive inverter: a154 common gain";
CM_ SG_ 1445 DIR_a154_noCalibration "Rear drive inverter: a154 no calibration";
CM_ SG_ 1445 DIR_a154_noPhaseLock "Rear drive inverter: a154 no phase lock";
CM_ SG_ 1445 DIR_a154_noCarrier "Rear drive inverter: a154 no carrier";
CM_ SG_ 1445 DIR_a154_notReady "Rear drive inverter: a154 not ready";
CM_ SG_ 1445 DIR_a154_errorTableInvalid "Rear drive inverter: a154 error table invalid";
CM_ SG_ 1445 DIR_a154_carrierOffset "Rear drive inverter: a154 carrier offset";
CM_ SG_ 1445 DIR_a154_trackerIrrational "Rear drive inverter: a154 tracker irrational";
CM_ SG_ 1445 DIR_a154_claMIA "Rear drive inverter: a154 cla MIA";
CM_ SG_ 1445 DIR_a155_sensors "Rear drive inverter: a155 sensors";
CM_ SG_ 1445 DIR_a155_coolant "Rear drive inverter: a155 coolant";
CM_ SG_ 1445 DIR_a155_LVPowerState "Rear drive inverter: a155 LV power state";
CM_ SG_ 1445 DIR_a155_vehicleStatus "Rear drive inverter: a155 vehicle status";
CM_ SG_ 1445 DIR_a155_status "Rear drive inverter: a155 status";
CM_ SG_ 1445 DIR_a155_leftDoorStatus "Rear drive inverter: a155 left door status";
CM_ SG_ 1445 DIR_a155_rightDoorStatus "Rear drive inverter: a155 right door status";
CM_ SG_ 1445 DIR_a155_vcleftSwitchStatus "Rear drive inverter: a155 vcleft switch status";
CM_ SG_ 1445 DIR_a155_restraintStatus "Rear drive inverter: a155 restraint status";
CM_ SG_ 1445 DIR_a155_systemStatus "Rear drive inverter: a155 system status";
CM_ SG_ 1445 DIR_a155_prndStatus "Rear drive inverter: a155 prnd status";
CM_ SG_ 1445 DIR_a155_liftgateStatus "Rear drive inverter: a155 liftgate status";
CM_ SG_ 1445 DIR_a157_RCM_inertial1 "Rear drive inverter: a157 RCM inertial1";
CM_ SG_ 1445 DIR_a157_RCM_inertial2 "Rear drive inverter: a157 RCM inertial2";
CM_ SG_ 1445 DIR_a158_IBST_party1 "Rear drive inverter: a158 IBST party1";
CM_ SG_ 1445 DIR_a158_BUS1_IBST_status "Rear drive inverter: a158 BUS1 IBST status";
CM_ SG_ 1445 DIR_a158_BUS2_IBST_status "Rear drive inverter: a158 BUS2 IBST status";
CM_ SG_ 1445 DIR_a160_vBatRawMinusFiltered "Rear drive inverter: a160 v bat raw minus filtered";
CM_ SG_ 1445 DIR_a160_vBatFilteredRate "Rear drive inverter: a160 v bat filtered rate";
CM_ SG_ 1445 DIR_a160_elapsedMs "Rear drive inverter: a160 elapsed ms";
CM_ SG_ 1445 DIR_a160_energy "Rear drive inverter: a160 energy";
CM_ SG_ 1445 DIR_a161_EPAS3P_sysStatus "Rear drive inverter: a161 EPAS3 p sys status";
CM_ SG_ 1445 DIR_a161_EPAS3P_angleCalib "Rear drive inverter: a161 EPAS3 p angle calib";
CM_ SG_ 1445 DIR_a202_reason "Rear drive inverter: a202 reason";
CM_ SG_ 1445 DIR_a202_movement "Rear drive inverter: a202 movement";
CM_ SG_ 1445 DIR_a202_sysStateExitCondition "Rear drive inverter: a202 sys state exit condition";
CM_ SG_ 1445 DIR_a233_missedMsgCount "Rear drive inverter: a233 missed msg count";
CM_ SG_ 1445 DIR_a233_serviceModeActive "Signal reported by Rear drive inverter";
CM_ SG_ 1445 DIR_a234_PCS_dcdcStatus "Rear drive inverter: a234 PCS dcdc status";
CM_ SG_ 1445 DIR_a236_states "Rear drive inverter: a236 states";
CM_ SG_ 1445 DIR_a242_RotorOffset "Rear drive inverter: a242 rotor offset";
CM_ SG_ 1445 DIR_a242_RotorFlux "Rear drive inverter: a242 rotor flux";
CM_ SG_ 1445 DIR_a242_ResolverError "Rear drive inverter: a242 resolver error";
CM_ SG_ 1445 DIR_a244_desatHighSide "Rear drive inverter: a244 desat high side";
CM_ SG_ 1445 DIR_a244_desatLowSide "Rear drive inverter: a244 desat low side";
CM_ SG_ 1445 DIR_a244_singleSwitchShort "Rear drive inverter: a244 single switch short";
CM_ SG_ 1445 DIR_a244_flybackFault "Rear drive inverter: a244 flyback fault";
CM_ SG_ 1445 DIR_a244_postShortTestFailed "Rear drive inverter: a244 post short test failed";
CM_ SG_ 1445 DIR_a244_udsSelfTest "Rear drive inverter: a244 uds self test";
CM_ SG_ 1445 DIR_a244_irSensorV "Rear drive inverter: a244 ir sensor v";
CM_ SG_ 1445 DIR_a244_gateDriveICUndervoltage "Rear drive inverter: a244 gate drive IC undervoltage";
CM_ SG_ 1445 DIR_a244_plausibleSingleSwitchSh "Rear drive inverter: a244 plausible single switch short only";
CM_ SG_ 1445 DIR_a246_atSpeedDIResetCount "Rear drive inverter: a246 at speed DI reset count";
CM_ SG_ 1445 DIR_a246_didPMCauseASC "Rear drive inverter: a246 did PM cause ASC";
CM_ SG_ 1445 DIR_a246_currentSensorRational "Rear drive inverter: a246 current sensor rational";
CM_ SG_ 1445 DIR_a246_observerDetectedLS3PS "Rear drive inverter: a246 observer detected LS3 PS";
CM_ SG_ 1445 DIR_a246_hvIsGood "Rear drive inverter: a246 hv is good";
CM_ SG_ 1445 DIR_a246_lvIsGood "Rear drive inverter: a246 lv is good";
CM_ SG_ 1445 DIR_a246_codeBranch "Rear drive inverter: a246 code branch";
CM_ SG_ 1445 DIR_a246_motorRPM "Rear drive inverter: a246 motor RPM";
CM_ SG_ 1445 DIR_a246_eepromOffsetIa "Rear drive inverter: a246 eeprom offset ia";
CM_ SG_ 1445 DIR_a246_eepromOffsetIb "Rear drive inverter: a246 eeprom offset ib";
CM_ SG_ 1445 DIR_a247_rotorOffsetEst "Rear drive inverter: a247 rotor offset est";
CM_ SG_ 1445 DIR_a247_motorRPM "Rear drive inverter: a247 motor RPM";
CM_ SG_ 1445 DIR_a247_torqueMotor "Rear drive inverter: a247 torque motor";
CM_ SG_ 1445 DIR_a251_oilFlow "Rear drive inverter: a251 oil flow";
CM_ SG_ 1445 DIR_a251_oilTemperature "Rear drive inverter: a251 oil temperature";
CM_ SG_ 1445 DIR_a251_dcVoltage "Rear drive inverter: a251 dc voltage";
CM_ SG_ 1445 DIR_a251_dcCurrent "Rear drive inverter: a251 dc current";
CM_ SG_ 1445 DIR_a251_phaseCurrent "Rear drive inverter: a251 phase current";
CM_ SG_ 1445 DIR_a251_leadAngle "Rear drive inverter: a251 lead angle";
CM_ SG_ 1445 DIR_a251_reason "Rear drive inverter: a251 reason";
CM_ BO_ 935 "Rear drive inverter message: alert matrix1";
CM_ SG_ 935 DIR_a001_hwPhaseAgateDrive "Rear drive inverter: a001 hw phase agate drive";
CM_ SG_ 935 DIR_a002_hwPhaseBgateDrive "Rear drive inverter: a002 hw phase bgate drive";
CM_ SG_ 935 DIR_a003_hwPhaseCgateDrive "Rear drive inverter: a003 hw phase cgate drive";
CM_ SG_ 935 DIR_a004_hwPhaseApeak "Rear drive inverter: a004 hw phase apeak";
CM_ SG_ 935 DIR_a005_hwPhaseBpeak "Rear drive inverter: a005 hw phase bpeak";
CM_ SG_ 935 DIR_a006_hwPhaseCpeak "Rear drive inverter: a006 hw phase cpeak";
CM_ SG_ 935 DIR_a007_statorAnomalyDetected "Rear drive inverter: a007 stator anomaly detected";
CM_ SG_ 935 DIR_a008_hwEncoderA "Rear drive inverter: a008 hw encoder a";
CM_ SG_ 935 DIR_a009_hwEncoderB "Rear drive inverter: a009 hw encoder b";
CM_ SG_ 935 DIR_a010_unintendedReset "Rear drive inverter: a010 unintended reset";
CM_ SG_ 935 DIR_a011_swPowerStageNotReady "Rear drive inverter: a011 sw power stage not ready";
CM_ SG_ 935 DIR_a012_hvilNotClosed "Rear drive inverter: a012 hvil not closed";
CM_ SG_ 935 DIR_a013_eccError "Rear drive inverter: a013 ecc error";
CM_ SG_ 935 DIR_a014_activeDamping "Rear drive inverter: a014 active damping";
CM_ SG_ 935 DIR_a015_mechSafeStateAnomaly "Rear drive inverter: a015 mech safe state anomaly";
CM_ SG_ 935 DIR_a016_safeStateApplied "Rear drive inverter: a016 safe state applied";
CM_ SG_ 935 DIR_a017_hwPedalMonitor "Rear drive inverter: a017 hw pedal monitor";
CM_ SG_ 935 DIR_a018_hwLVSupplyUV "Rear drive inverter: a018 hw LV supply UV";
CM_ SG_ 935 DIR_a020_hwMotorEncoder "Rear drive inverter: a020 hw motor encoder";
CM_ SG_ 935 DIR_a021_hwBusOV "Rear drive inverter: a021 hw bus OV";
CM_ SG_ 935 DIR_a022_hw5vSupplyUV "Rear drive inverter: a022 hw5v supply UV";
CM_ SG_ 935 DIR_a024_selfTest "Rear drive inverter: a024 self test";
CM_ SG_ 935 DIR_a025_phaseApeak "Rear drive inverter: a025 phase apeak";
CM_ SG_ 935 DIR_a026_phaseBpeak "Rear drive inverter: a026 phase bpeak";
CM_ SG_ 935 DIR_a027_phaseCpeak "Rear drive inverter: a027 phase cpeak";
CM_ SG_ 935 DIR_a028_phaseArms "Rear drive inverter: a028 phase arms";
CM_ SG_ 935 DIR_a029_phaseBrms "Rear drive inverter: a029 phase brms";
CM_ SG_ 935 DIR_a030_phaseCrms "Rear drive inverter: a030 phase crms";
CM_ SG_ 935 DIR_a031_phaseAcurrentOffset "Rear drive inverter: a031 phase acurrent offset";
CM_ SG_ 935 DIR_a032_phaseBcurrentOffset "Rear drive inverter: a032 phase bcurrent offset";
CM_ SG_ 935 DIR_a033_phaseAcurrentSensor "Rear drive inverter: a033 phase acurrent sensor";
CM_ SG_ 935 DIR_a034_phaseBcurrentSensor "Rear drive inverter: a034 phase bcurrent sensor";
CM_ SG_ 935 DIR_a035_phaseCurrentBalance "Rear drive inverter: a035 phase current balance";
CM_ SG_ 935 DIR_a036_busOV "Rear drive inverter: a036 bus OV";
CM_ SG_ 935 DIR_a037_busUV "Rear drive inverter: a037 bus UV";
CM_ SG_ 935 DIR_a038_busVsensor "Rear drive inverter: a038 bus vsensor";
CM_ SG_ 935 DIR_a039_exceptionUndefinedInstr "Rear drive inverter: a039 exception undefined instruction";
CM_ SG_ 935 DIR_a040_difMIA "Rear drive inverter: a040 dif MIA";
CM_ SG_ 935 DIR_a041_sdcMIA "Rear drive inverter: a041 sdc MIA";
CM_ SG_ 935 DIR_a042_inletSensor "Rear drive inverter: a042 inlet sensor";
CM_ SG_ 935 DIR_a043_outletOT "Rear drive inverter: a043 outlet OT";
CM_ SG_ 935 DIR_a044_outletUT "Rear drive inverter: a044 outlet UT";
CM_ SG_ 935 DIR_a045_outletSensor "Rear drive inverter: a045 outlet sensor";
CM_ SG_ 935 DIR_a046_statorOT "Rear drive inverter: a046 stator OT";
CM_ SG_ 935 DIR_a047_statorSensor1 "Rear drive inverter: a047 stator sensor1";
CM_ SG_ 935 DIR_a048_statorSensor2 "Rear drive inverter: a048 stator sensor2";
CM_ SG_ 935 DIR_a049_statorSensorDiff "Rear drive inverter: a049 stator sensor diff";
CM_ SG_ 935 DIR_a050_noStatorSensor "Rear drive inverter: a050 no stator sensor";
CM_ SG_ 935 DIR_a052_dirMIA "Rear drive inverter: a052 dir MIA";
CM_ SG_ 935 DIR_a053_unexpectedLatchState "Rear drive inverter: a053 unexpected latch state";
CM_ SG_ 935 DIR_a054_driveInverterOT "Rear drive inverter: a054 drive inverter OT";
CM_ SG_ 935 DIR_a055_trqCrossCheck "Rear drive inverter: a055 trq cross check";
CM_ SG_ 935 DIR_a056_ambientOT "Rear drive inverter: a056 ambient OT";
CM_ SG_ 935 DIR_a057_ambientUT "Rear drive inverter: a057 ambient UT";
CM_ SG_ 935 DIR_a058_ambientSensor "Rear drive inverter: a058 ambient sensor";
CM_ SG_ 935 DIR_a059_heatsinkOT "Rear drive inverter: a059 heatsink OT";
CM_ SG_ 935 DIR_a060_heatsinkUT "Rear drive inverter: a060 heatsink UT";
CM_ SG_ 935 DIR_a061_heatsinkSensor "Rear drive inverter: a061 heatsink sensor";
CM_ SG_ 935 DIR_a062_systemLimpMode "Rear drive inverter: a062 system limp mode";
CM_ SG_ 935 DIR_a063_bbMIA "Rear drive inverter: a063 bb MIA";
CM_ SG_ 935 DIR_a064_torqueIntervention "Rear drive inverter: a064 torque intervention";
CM_ BO_ 949 "Rear drive inverter message: alert matrix2";
CM_ SG_ 949 DIR_a065_canHardwareBusB "Rear drive inverter: a065 can hardware bus b";
CM_ SG_ 949 DIR_a066_canDataBusB "Rear drive inverter: a066 can data bus b";
CM_ SG_ 949 DIR_a067_canOverrunBusB "Rear drive inverter: a067 can overrun bus b";
CM_ SG_ 949 DIR_a069_rotorTempLimit "Rear drive inverter: a069 rotor temp limit";
CM_ SG_ 949 DIR_a070_udsTransactionInitiated "Rear drive inverter: a070 uds transaction initiated";
CM_ SG_ 949 DIR_a071_busDisconnected "Rear drive inverter: a071 bus disconnected";
CM_ SG_ 949 DIR_a072_gateDriveFaultCounter "Rear drive inverter: a072 gate drive fault counter";
CM_ SG_ 949 DIR_a073_motorSpeed "Rear drive inverter: a073 motor speed";
CM_ SG_ 949 DIR_a074_motorEncoder "Rear drive inverter: a074 motor encoder";
CM_ SG_ 949 DIR_a075_motorSpeedMismatch "Rear drive inverter: a075 motor speed mismatch";
CM_ SG_ 949 DIR_a076_lvSupplyOV "Rear drive inverter: a076 lv supply OV";
CM_ SG_ 949 DIR_a077_lvSupplyUV "Rear drive inverter: a077 lv supply UV";
CM_ SG_ 949 DIR_a078_adcRefLow "Rear drive inverter: a078 adc ref low";
CM_ SG_ 949 DIR_a079_adcRefHigh "Rear drive inverter: a079 adc ref high";
CM_ SG_ 949 DIR_a080_adcInfo "Rear drive inverter: a080 adc info";
CM_ SG_ 949 DIR_a081_P0BFF_DIR_EM_CurrentHig "Rear drive inverter: a081 P0 BFF DIR EM current high";
CM_ SG_ 949 DIR_a082_P0F45_DIR_ECU_DemoTimer "Rear drive inverter: a082 P0 F45 DIR ECU demo timer";
CM_ SG_ 949 DIR_a083_P98B3_DIR_ECU_DemoWindo "Rear drive inverter: a083 P98 B3 DIR ECU demo window";
CM_ SG_ 949 DIR_a084_eccTestData0 "Rear drive inverter: a084 ecc test data0";
CM_ SG_ 949 DIR_a086_activeDischargeOn "Rear drive inverter: a086 active discharge on";
CM_ SG_ 949 DIR_a087_gtwMIA "Rear drive inverter: a087 gtw MIA";
CM_ SG_ 949 DIR_a088_uiMIA "Rear drive inverter: a088 ui MIA";
CM_ SG_ 949 DIR_a090_pmMIA "Rear drive inverter: a090 pm MIA";
CM_ SG_ 949 DIR_a091_espMIA "Rear drive inverter: a091 esp MIA";
CM_ SG_ 949 DIR_a092_bmsMIA "Rear drive inverter: a092 bms MIA";
CM_ SG_ 949 DIR_a093_canHardwareBusA "Rear drive inverter: a093 can hardware bus a";
CM_ SG_ 949 DIR_a094_canDataBusA "Rear drive inverter: a094 can data bus a";
CM_ SG_ 949 DIR_a095_canOverrunBusA "Rear drive inverter: a095 can overrun bus a";
CM_ SG_ 949 DIR_a096_memoryError "Rear drive inverter: a096 memory error";
CM_ SG_ 949 DIR_a097_eepromError "Rear drive inverter: a097 eeprom error";
CM_ SG_ 949 DIR_a098_intTimeTooLong "Rear drive inverter: a098 int time too long";
CM_ SG_ 949 DIR_a099_threadOverrun "Rear drive inverter: a099 thread overrun";
CM_ SG_ 949 DIR_a100_assertion "Rear drive inverter: a100 assertion";
CM_ SG_ 949 DIR_a101_eccTestData1 "Rear drive inverter: a101 ecc test data1";
CM_ SG_ 949 DIR_a102_exceptionPrefetchAbort "Rear drive inverter: a102 exception prefetch abort";
CM_ SG_ 949 DIR_a103_lowFlow "Rear drive inverter: a103 low flow";
CM_ SG_ 949 DIR_a107_fpgaError "Rear drive inverter: a107 fpga error";
CM_ SG_ 949 DIR_a108_stateTrans "Rear drive inverter: a108 state trans";
CM_ SG_ 949 DIR_a109_ahbWriteError "Rear drive inverter: a109 ahb write error";
CM_ SG_ 949 DIR_a110_brakeMIA "Rear drive inverter: a110 brake MIA";
CM_ SG_ 949 DIR_a111_badPhaseSensorCalib "Rear drive inverter: a111 bad phase sensor calib";
CM_ SG_ 949 DIR_a112_noPhaseCurrent "Rear drive inverter: a112 no phase current";
CM_ SG_ 949 DIR_a113_noFuncHeatsinkSensor "Rear drive inverter: a113 no func heatsink sensor";
CM_ SG_ 949 DIR_a114_exceptionDataAbort "Rear drive inverter: a114 exception data abort";
CM_ SG_ 949 DIR_a115_exceptionDataAbort2 "Rear drive inverter: a115 exception data abort2";
CM_ SG_ 949 DIR_a116_highSpeedWearCounter "Rear drive inverter: a116 high speed wear counter";
CM_ SG_ 949 DIR_a117_diMIA "Rear drive inverter: a117 di MIA";
CM_ SG_ 949 DIR_a119_hvpMIA "Rear drive inverter: a119 hvp MIA";
CM_ SG_ 949 DIR_a120_hvlinkMIA "Rear drive inverter: a120 hvlink MIA";
CM_ SG_ 949 DIR_a121_motorControlRegulation "Rear drive inverter: a121 motor control regulation";
CM_ SG_ 949 DIR_a122_highStackUsage "Rear drive inverter: a122 high stack usage";
CM_ SG_ 949 DIR_a123_lossMotorControl "Rear drive inverter: a123 loss motor control";
CM_ SG_ 949 DIR_a126_limpMode "Rear drive inverter: a126 limp mode";
CM_ SG_ 949 DIR_a127_gracefulPowerOff "Rear drive inverter: a127 graceful power off";
CM_ SG_ 949 DIR_a128_fpgaVersionMismatch "Rear drive inverter: a128 fpga version mismatch";
CM_ BO_ 965 "Rear drive inverter message: alert matrix3";
CM_ SG_ 965 DIR_a133_capacitorOT "Rear drive inverter: a133 capacitor OT";
CM_ SG_ 965 DIR_a134_wheelSpeedIrrational "Rear drive inverter: a134 wheel speed irrational";
CM_ SG_ 965 DIR_a136_spiError "Rear drive inverter: a136 spi error";
CM_ SG_ 965 DIR_a142_highLashAngle "Rear drive inverter: a142 high lash angle";
CM_ SG_ 965 DIR_a144_configMismatch "Rear drive inverter: a144 config mismatch";
CM_ SG_ 965 DIR_a147_highTorqueWearLimit "Rear drive inverter: a147 high torque wear limit";
CM_ SG_ 965 DIR_a148_burnInCycleEnded "Rear drive inverter: a148 burn in cycle ended";
CM_ SG_ 965 DIR_a149_oilPumpFailure "Rear drive inverter: a149 oil pump failure";
CM_ SG_ 965 DIR_a150_busVD "Rear drive inverter: a150 bus VD";
CM_ SG_ 965 DIR_a151_shockTorqueLimiter "Rear drive inverter: a151 shock torque limiter";
CM_ SG_ 965 DIR_a152_linError "Rear drive inverter: a152 lin error";
CM_ SG_ 965 DIR_a153_oilPumpDiagnostics "Rear drive inverter: a153 oil pump diagnostics";
CM_ SG_ 965 DIR_a154_resolver "Rear drive inverter: a154 resolver";
CM_ SG_ 965 DIR_a155_vcfrontMIA "Rear drive inverter: a155 vcfront MIA";
CM_ SG_ 965 DIR_a156_currentObserver "Rear drive inverter: a156 current observer";
CM_ SG_ 965 DIR_a157_rcmMIA "Rear drive inverter: a157 rcm MIA";
CM_ SG_ 965 DIR_a158_ibstMIA "Rear drive inverter: a158 ibst MIA";
CM_ SG_ 965 DIR_a160_busVoltageAnomaly "Rear drive inverter: a160 bus voltage anomaly";
CM_ SG_ 965 DIR_a161_epas3pMIA "Rear drive inverter: a161 epas3p MIA";
CM_ SG_ 965 DIR_a162_endOfLifetimeBurnIn "Rear drive inverter: a162 end of lifetime burn in";
CM_ SG_ 965 DIR_a174_unitMayNotRestart "Rear drive inverter: a174 unit may not restart";
CM_ SG_ 965 DIR_a176_safetyICFault "Rear drive inverter: a176 safety IC fault";
CM_ SG_ 965 DIR_a177_fluxReferenceCorrected "Rear drive inverter: a177 flux reference corrected";
CM_ SG_ 965 DIR_a178_spindownLearningBrakeAl "Rear drive inverter: a178 spindown learning brake allowed";
CM_ BO_ 997 "Rear drive inverter message: alert matrix4";
CM_ SG_ 997 DIR_a202_excessHeatUnavailable "Rear drive inverter: a202 excess heat unavailable";
CM_ SG_ 997 DIR_a225_tmpEstPlausibility "Rear drive inverter: a225 tmp est plausibility";
CM_ SG_ 997 DIR_a231_unintendedReset2 "Rear drive inverter: a231 unintended reset2";
CM_ SG_ 997 DIR_a233_diMsgMissed "Rear drive inverter: a233 di msg missed";
CM_ SG_ 997 DIR_a234_pcsMIA "Rear drive inverter: a234 pcs MIA";
CM_ SG_ 997 DIR_a236_tasMIA "Rear drive inverter: a236 tas MIA";
CM_ SG_ 997 DIR_a241_systemThermallyLimited "Rear drive inverter: a241 system thermally limited";
CM_ SG_ 997 DIR_a242_spinDownLearning "Rear drive inverter: a242 spin down learning";
CM_ SG_ 997 DIR_a243_ecuLogAvailable "Rear drive inverter: a243 ecu log available";
CM_ SG_ 997 DIR_a244_mechSafeStateApplied "Rear drive inverter: a244 mech safe state applied";
CM_ SG_ 997 DIR_a245_mechSafeStatePreWarn "Rear drive inverter: a245 mech safe state pre warn";
CM_ SG_ 997 DIR_a246_recoveryAtSpeedError "Rear drive inverter: a246 recovery at speed error";
CM_ SG_ 997 DIR_a247_rotorOffsetError "Rear drive inverter: a247 rotor offset error";
CM_ SG_ 997 DIR_a248_vehicleSpeedLimited "Rear drive inverter: a248 vehicle speed limited";
CM_ SG_ 997 DIR_a249_highStatorTempFromResis "Rear drive inverter: a249 high stator temp from resist";
CM_ SG_ 997 DIR_a250_preregulatorRail "Rear drive inverter: a250 preregulator rail";
CM_ SG_ 997 DIR_a251_oilPumpService "Rear drive inverter: a251 oil pump service";
CM_ SG_ 997 DIR_a252_currentCoreFallback "Rear drive inverter: a252 current core fallback";
CM_ SG_ 997 DIR_a253_lvBoostedRail "Rear drive inverter: a253 lv boosted rail";
CM_ SG_ 997 DIR_a254_activeDischargeRail "Rear drive inverter: a254 active discharge rail";
CM_ SG_ 997 DIR_a255_currentGainFallback "Rear drive inverter: a255 current gain fallback";
CM_ BO_ 2005 "Rear drive inverter message: debug";
CM_ SG_ 2005 DIR_debugSelector "Rear drive inverter: debug selector";
CM_ SG_ 2005 DIR_phaseOutBusbarTemp "Rear drive inverter: phase out busbar temp";
CM_ SG_ 2005 DIR_phaseOutBusbarWeldTemp "Rear drive inverter: phase out busbar weld temp";
CM_ SG_ 2005 DIR_phaseOutLugTemp "Rear drive inverter: phase out lug temp";
CM_ SG_ 2005 DIR_dcLinkCapTemp "Rear drive inverter: dc link cap temp";
CM_ SG_ 2005 DIR_hvDcCableTemp "Rear drive inverter: hv dc cable temp";
CM_ SG_ 2005 DIR_negDcBusbarTemp "Rear drive inverter: neg dc busbar temp";
CM_ SG_ 2005 DIR_posDcBusbarTemp "Rear drive inverter: pos dc busbar temp";
CM_ SG_ 2005 DIR_statorEndWindingTemp "Rear drive inverter: stator end winding temp";
CM_ SG_ 2005 DIR_rotorMaxMagnetTemp "Reports the maximum temperature of the rotor magnet.";
CM_ SG_ 2005 DIR_lightSenseV "Rear drive inverter: light sense v";
CM_ SG_ 2005 DIR_pyroSenseV "Rear drive inverter: pyro sense v";
CM_ SG_ 2005 DIR_statorSlotWindingTemp "Rear drive inverter: stator slot winding temp";
CM_ SG_ 2005 DIR_intervalMaxHvBusV "Rear drive inverter: interval max hv bus v";
CM_ BO_ 633 "Rear drive inverter message: hv status";
CM_ SG_ 633 DIR_hvStatusChecksum "Rear drive inverter: hv status checksum";
CM_ SG_ 633 DIR_hvStatusCounter "Rear drive inverter: hv status counter";
CM_ SG_ 633 DIR_hvilCurrent "HVIL Current";
CM_ SG_ 633 DIR_hvilCmVoltage "HVIL Common Mode Voltage";
CM_ SG_ 633 DIR_hvilStatus "Aggregated hardware and measured HVIL unit status";
CM_ SG_ 633 DIR_hvilSupplyState "Rear drive inverter: hvil supply state";
CM_ SG_ 633 DIR_activeDischargeCtrl "Rear drive inverter: active discharge ctrl";
CM_ SG_ 633 DIR_activeDischargeStatus "Active discharge status from HVIL_FAULT signal.";
CM_ SG_ 633 DIR_vBat "Reports the battery voltage measured by the Drive Inverter's local Analog to Digital Converter (ADC).";
CM_ SG_ 633 DIR_vBatQF "Rear drive inverter: v bat QF";
CM_ SG_ 633 DIR_powerStageSafeState "Rear drive inverter: power stage safe state";
CM_ SG_ 633 DIR_fluxState "Rear drive inverter: flux state";
CM_ SG_ 633 DIR_vBusDiag "Rear drive inverter: v bus diag";
CM_ SG_ 633 DIR_gateDriveState "Rear drive inverter: gate drive state";
CM_ BO_ 821 "Rear drive inverter message: info";
CM_ SG_ 821 DIR_infoIndex "Rear drive inverter: info index";
CM_ SG_ 821 DIR_buildType "Rear drive inverter: build type";
CM_ SG_ 821 DIR_buildConfigurationId "Rear drive inverter: build configuration id";
CM_ SG_ 821 DIR_hardwareId "Rear drive inverter: hardware id";
CM_ SG_ 821 DIR_componentId "Rear drive inverter: component id";
CM_ SG_ 821 DIR_pcbaId "Rear drive inverter: pcba id";
CM_ SG_ 821 DIR_assemblyId "Rear drive inverter: assembly id";
CM_ SG_ 821 DIR_usageId "Rear drive inverter: usage id";
CM_ SG_ 821 DIR_subUsageId "Rear drive inverter: sub usage id";
CM_ SG_ 821 DIR_motorType "Rear drive inverter: motor type";
CM_ SG_ 821 DIR_siliconType "Rear drive inverter: silicon type";
CM_ SG_ 821 DIR_mechSafeStateType "Rear drive inverter: mech safe state type";
CM_ SG_ 821 DIR_applicationCrc "Rear drive inverter: application crc";
CM_ SG_ 821 DIR_oilPumpBuildType "Rear drive inverter: oil pump build type";
CM_ SG_ 821 DIR_oilPumpAppCrc "Rear drive inverter: oil pump app crc";
CM_ SG_ 821 DIR_FPGA_version "Rear drive inverter: FPGA version";
CM_ SG_ 821 DIR_bootGitHash "Rear drive inverter: boot git hash";
CM_ SG_ 821 DIR_infoBootLdUdsProtocolVersion "Rear drive inverter: info boot ld uds protocol version";
CM_ SG_ 821 DIR_bootloaderCrc "Rear drive inverter: bootloader crc";
CM_ SG_ 821 DIR_oilPumpPcbaId "Rear drive inverter: oil pump pcba id";
CM_ SG_ 821 DIR_oilPumpAssemblyId "Rear drive inverter: oil pump assembly id";
CM_ SG_ 821 DIR_oilPumpUsageId "Rear drive inverter: oil pump usage id";
CM_ SG_ 821 DIR_refRotorFlux "Rear drive inverter: ref rotor flux";
CM_ SG_ 821 DIR_refRotorOffset "Rear drive inverter: ref rotor offset";
CM_ SG_ 821 DIR_speedWearTotal "Rear drive inverter: speed wear total";
CM_ SG_ 821 DIR_torqueWearTotal "Rear drive inverter: torque wear total";
CM_ BO_ 2039 "Rear drive inverter message: motor status";
CM_ SG_ 2039 DIR_motorCurrent "Drive Inverer measured motor RMS phase current.";
CM_ SG_ 2039 DIR_switchingFrequency "Rear drive inverter: switching frequency";
CM_ SG_ 2039 DIR_targetFluxMode "Rear drive inverter: target flux mode";
CM_ SG_ 2039 DIR_switchShortTestRetryCount "Rear drive inverter: switch short test retry count";
CM_ BO_ 917 "Rear drive inverter message: oil pump";
CM_ SG_ 917 DIR_oilPumpState "Reports the state of the oil pump.";
CM_ SG_ 917 DIR_oilPumpFluidTQF "Rear drive inverter: oil pump fluid TQF";
CM_ SG_ 917 DIR_oilPumpLeadAngle "Rear drive inverter: oil pump lead angle";
CM_ SG_ 917 DIR_oilPumpFlowTarget "Detects oil pump flow target.";
CM_ SG_ 917 DIR_oilPumpFlowActual "Detects oil pump flow.";
CM_ SG_ 917 DIR_oilPumpFluidT "Detects oil pump fluid tester.";
CM_ SG_ 917 DIR_oilPumpPhaseCurrent "Rear drive inverter: oil pump phase current";
CM_ SG_ 917 DIR_oilPumpPressureEstimate "Oil pump pressure estimate.";
CM_ SG_ 917 DIR_oilPumpPressureExpected "Oil pump pressure expected.";
CM_ SG_ 917 DIR_oilPumpPressureResidual "Oil pressure error outside of allowed tolerance";
CM_ BO_ 614 "Rear drive inverter message: power";
CM_ SG_ 614 DIR_elecPower "Rear drive inverter: elec power";
CM_ SG_ 614 DIR_heatPowerOptimal "Rear drive inverter: heat power optimal";
CM_ SG_ 614 DIR_heatPowerMax "Drive Inverter maximum heat power capability";
CM_ SG_ 614 DIR_heatPowerActual "Drive Inverter heat power";
CM_ SG_ 614 DIR_excessHeatCommand "Drive Inverter excess heat command";
CM_ SG_ 614 DIR_drivePowerMax "Rear drive inverter: drive power max";
CM_ BO_ 598 "Rear drive inverter message: status";
CM_ SG_ 598 DIR_statusChecksum "Rear drive inverter: status checksum";
CM_ SG_ 598 DIR_statusCounter "Rear drive inverter: status counter";
CM_ SG_ 598 DIR_state "DI unit state machine state.";
CM_ SG_ 598 DIR_keepAliveRequest "Used to detect that the Drive Inverter (DI) expects 12V and High Voltage (HV) to be kept up in order to protect hardware.";
CM_ SG_ 598 DIR_soptState "Detects the state of the the Switch Off Path Test (SOPT).";
CM_ SG_ 598 DIR_sysLimpRequest "Rear drive inverter: sys limp request";
CM_ SG_ 598 DIR_adState "Rear drive inverter: ad state";
CM_ SG_ 598 DIR_driveModeState "Rear drive inverter: drive mode state";
CM_ SG_ 598 DIR_lvSupplyV "Rear drive inverter: lv supply v";
CM_ SG_ 598 DIR_wasteState "Reports the Drive Inverter (DI) waste heat state.";
CM_ SG_ 598 DIR_haltRequest "Rear drive inverter: halt request";
CM_ SG_ 598 DIR_axleSpeedLimitRequest "Rear drive inverter: axle speed limit request";
CM_ SG_ 598 DIR_adDirection "Rear drive inverter: ad direction";
CM_ SG_ 598 DIR_spinDownLearningState "Rear drive inverter: spin down learning state";
CM_ SG_ 598 DIR_spinDownLearningMode "Rear drive inverter: spin down learning mode";
CM_ SG_ 598 DIR_unitRecoveredFromResetAtSpee "Rear drive inverter: unit recovered from reset at speed";
CM_ BO_ 789 "Rear drive inverter message: temperature";
CM_ SG_ 789 DIR_tempIndex "Rear drive inverter: temp index";
CM_ SG_ 789 DIR_inverterTQF "Detects the Drive Inverter (DI) outlet temperature qualifier.";
CM_ SG_ 789 DIR_pcbT "Rear drive inverter: pcb t";
CM_ SG_ 789 DIR_inverterT "Drive Inverter measured outlet temperature";
CM_ SG_ 789 DIR_statorT "Drive Inverter measured stator temperature.";
CM_ SG_ 789 DIR_dcCapT "Rear drive inverter: dc cap t";
CM_ SG_ 789 DIR_heatsinkT "Drive Inverter measured heatsink temperature";
CM_ SG_ 789 DIR_inverterTpct "Rear drive inverter: inverter tpct";
CM_ SG_ 789 DIR_statorTpct "Rear drive inverter: stator tpct";
CM_ SG_ 789 DIR_fluidInTemp "Inlet fluid temperature";
CM_ SG_ 789 DIR_normalFetBurnIn "Rear drive inverter: normal fet burn in";
CM_ SG_ 789 DIR_additionalFetBurnIn "Rear drive inverter: additional fet burn in";
CM_ SG_ 789 DIR_currentWeibullMiles "Rear drive inverter: current weibull miles";
CM_ SG_ 789 DIR_endOfServiceWeibullMiles "Rear drive inverter: end of service weibull miles";
CM_ SG_ 789 DIR_burnInDamageRatio "Rear drive inverter: burn in damage ratio";
CM_ SG_ 789 DIR_inverterSensorEst "Rear drive inverter: inverter sensor est";
CM_ SG_ 789 DIR_inverterHS1Est "Rear drive inverter: inverter HS1 est";
CM_ SG_ 789 DIR_initialBurnInVehicleOdometer "Rear drive inverter: initial burn in vehicle odometer";
CM_ SG_ 789 DIR_inverterHS2Est "Rear drive inverter: inverter HS2 est";
CM_ SG_ 789 DIR_inverterInletEst "Rear drive inverter: inverter inlet est";
CM_ BO_ 1495 "Rear drive inverter message: thermal control";
CM_ SG_ 1495 DIR_passiveInletTempReq "Rear drive inverter: passive inlet temp req";
CM_ SG_ 1495 DIR_activeInletTempReq "Rear drive inverter: active inlet temp req";
CM_ SG_ 1495 DIR_coolantFlowReq "Coolant flow requested";
CM_ SG_ 1495 DIR_oilFlowReq "Rear drive inverter: oil flow req";
CM_ SG_ 1495 DIR_criticalFlowReq "Rear drive inverter: critical flow req";
CM_ SG_ 1495 DIR_burnInStatus "Rear drive inverter: burn in status";
CM_ BO_ 264 "Rear drive inverter message: torque";
CM_ SG_ 264 DIR_torqueChecksum "Rear drive inverter: torque checksum";
CM_ SG_ 264 DIR_torqueCounter "Rear drive inverter: torque counter";
CM_ SG_ 264 DIR_torqueCommand "Torque commanded to the drive unit, referred to the axle/wheel";
CM_ SG_ 264 DIR_axleSpeedQF "Rear drive inverter: axle speed QF";
CM_ SG_ 264 DIR_torqueActual "Actual torque the drive unit is controlling to referred to the axle/wheel";
CM_ SG_ 264 DIR_axleSpeed "Drive Inverter motor speed normalized at axle level";
CM_ SG_ 264 DIR_axleTorqueQF "Rear drive inverter: axle torque QF";
CM_ SG_ 264 DIR_axlePowerCalcQF "Rear drive inverter: axle power calc QF";
BA_DEF_ BO_ "GenMsgCycleTime" INT 0 3600000;
BA_DEF_ BO_ "GenMsgSendType" ENUM "Cyclic","NotUsed","NotUsed","NotUsed","NotUsed","NotUsed","NotUsed","IfActive","NoMsgSendType","NotUsed";
BA_DEF_ BO_ "VFrameFormat" ENUM "StandardCAN","ExtendedCAN","reserved","J1939PG","reserved","reserved","reserved","reserved","reserved","reserved","reserved","reserved","reserved","reserved","StandardCAN_FD","ExtendedCAN_FD";
BA_DEF_ BO_ "CANFD_BRS" ENUM "0","1";
BA_DEF_ SG_ "SystemSignalLongSymbol" STRING;
BA_DEF_ SG_ "Confidence" ENUM "layout-only","plausible","validated";
BA_DEF_DEF_ "GenMsgCycleTime" 0;
BA_DEF_DEF_ "GenMsgSendType" "NoMsgSendType";
BA_DEF_DEF_ "VFrameFormat" "StandardCAN";
BA_DEF_DEF_ "CANFD_BRS" "1";
BA_DEF_DEF_ "SystemSignalLongSymbol" "";
BA_DEF_DEF_ "Confidence" "layout-only";
BA_ "Confidence" SG_ 886 DIF_inverterTQF 1;
BA_ "Confidence" SG_ 886 DIF_pcbT 1;
BA_ "Confidence" SG_ 886 DIF_inverterT 1;
BA_ "Confidence" SG_ 886 DIF_statorT 1;
BA_ "Confidence" SG_ 886 DIF_dcCapT 1;
BA_ "Confidence" SG_ 886 DIF_heatsinkT 1;
BA_ "Confidence" SG_ 886 DIF_inverterTpct 1;
BA_ "Confidence" SG_ 886 DIF_statorTpct 1;
BA_ "Confidence" SG_ 886 DIF_fluidInTemp 1;
BA_ "Confidence" SG_ 886 DIF_normalFetBurnIn 1;
BA_ "Confidence" SG_ 886 DIF_additionalFetBurnIn 1;
BA_ "Confidence" SG_ 886 DIF_currentWeibullMiles 1;
BA_ "Confidence" SG_ 886 DIF_endOfServiceWeibullMiles 1;
BA_ "Confidence" SG_ 886 DIF_burnInDamageRatio 1;
BA_ "Confidence" SG_ 886 DIF_inverterSensorEst 1;
BA_ "Confidence" SG_ 886 DIF_inverterHS1Est 1;
BA_ "Confidence" SG_ 886 DIF_initialBurnInVehicleOdometer 1;
BA_ "Confidence" SG_ 886 DIF_inverterHS2Est 1;
BA_ "Confidence" SG_ 886 DIF_inverterInletEst 1;
BA_ "Confidence" SG_ 1367 DIF_passiveInletTempReq 1;
BA_ "Confidence" SG_ 1367 DIF_activeInletTempReq 1;
BA_ "Confidence" SG_ 1367 DIF_coolantFlowReq 1;
BA_ "Confidence" SG_ 1367 DIF_oilFlowReq 1;
BA_ "Confidence" SG_ 1367 DIF_criticalFlowReq 1;
BA_ "Confidence" SG_ 1367 DIF_burnInStatus 1;
BA_ "Confidence" SG_ 390 DIF_torqueCommand 1;
BA_ "Confidence" SG_ 390 DIF_axleSpeedQF 1;
BA_ "Confidence" SG_ 390 DIF_torqueActual 1;
BA_ "Confidence" SG_ 390 DIF_axleSpeed 1;
BA_ "Confidence" SG_ 390 DIF_axleTorqueQF 1;
BA_ "Confidence" SG_ 390 DIF_axlePowerCalcQF 1;
BA_ "SystemSignalLongSymbol" SG_ 1445 DIR_a144_packPerformanceDeviatio "DIR_a144_packPerformanceDeviation";
BA_ "SystemSignalLongSymbol" SG_ 1445 DIR_a244_plausibleSingleSwitchSh "DIR_a244_plausibleSingleSwitchShortOnly";
BA_ "SystemSignalLongSymbol" SG_ 935 DIR_a039_exceptionUndefinedInstr "DIR_a039_exceptionUndefinedInstruction";
BA_ "SystemSignalLongSymbol" SG_ 949 DIR_a081_P0BFF_DIR_EM_CurrentHig "DIR_a081_P0BFF_DIR_EM_CurrentHigh";
BA_ "SystemSignalLongSymbol" SG_ 949 DIR_a083_P98B3_DIR_ECU_DemoWindo "DIR_a083_P98B3_DIR_ECU_DemoWindow";
BA_ "SystemSignalLongSymbol" SG_ 965 DIR_a178_spindownLearningBrakeAl "DIR_a178_spindownLearningBrakeAllowed";
BA_ "SystemSignalLongSymbol" SG_ 997 DIR_a249_highStatorTempFromResis "DIR_a249_highStatorTempFromResist";
BA_ "Confidence" SG_ 2005 DIR_phaseOutBusbarTemp 1;
BA_ "Confidence" SG_ 2005 DIR_phaseOutBusbarWeldTemp 1;
BA_ "Confidence" SG_ 2005 DIR_phaseOutLugTemp 1;
BA_ "Confidence" SG_ 2005 DIR_dcLinkCapTemp 1;
BA_ "Confidence" SG_ 2005 DIR_hvDcCableTemp 1;
BA_ "Confidence" SG_ 2005 DIR_negDcBusbarTemp 1;
BA_ "Confidence" SG_ 2005 DIR_posDcBusbarTemp 1;
BA_ "Confidence" SG_ 2005 DIR_statorEndWindingTemp 1;
BA_ "Confidence" SG_ 2005 DIR_rotorMaxMagnetTemp 1;
BA_ "Confidence" SG_ 2005 DIR_lightSenseV 1;
BA_ "Confidence" SG_ 2005 DIR_pyroSenseV 1;
BA_ "Confidence" SG_ 2005 DIR_statorSlotWindingTemp 1;
BA_ "Confidence" SG_ 2005 DIR_intervalMaxHvBusV 1;
BA_ "Confidence" SG_ 633 DIR_hvilCurrent 1;
BA_ "Confidence" SG_ 633 DIR_hvilCmVoltage 1;
BA_ "Confidence" SG_ 633 DIR_hvilStatus 1;
BA_ "Confidence" SG_ 633 DIR_hvilSupplyState 1;
BA_ "Confidence" SG_ 633 DIR_activeDischargeStatus 1;
BA_ "Confidence" SG_ 633 DIR_vBat 1;
BA_ "Confidence" SG_ 633 DIR_vBatQF 1;
BA_ "Confidence" SG_ 633 DIR_powerStageSafeState 1;
BA_ "Confidence" SG_ 633 DIR_fluxState 1;
BA_ "Confidence" SG_ 633 DIR_gateDriveState 1;
BA_ "Confidence" SG_ 821 DIR_buildType 1;
BA_ "Confidence" SG_ 821 DIR_motorType 1;
BA_ "Confidence" SG_ 821 DIR_siliconType 1;
BA_ "Confidence" SG_ 821 DIR_mechSafeStateType 1;
BA_ "Confidence" SG_ 821 DIR_oilPumpBuildType 1;
BA_ "Confidence" SG_ 821 DIR_refRotorFlux 1;
BA_ "Confidence" SG_ 821 DIR_refRotorOffset 1;
BA_ "Confidence" SG_ 821 DIR_speedWearTotal 1;
BA_ "Confidence" SG_ 821 DIR_torqueWearTotal 1;
BA_ "Confidence" SG_ 2039 DIR_motorCurrent 1;
BA_ "Confidence" SG_ 2039 DIR_switchingFrequency 1;
BA_ "Confidence" SG_ 2039 DIR_targetFluxMode 1;
BA_ "Confidence" SG_ 917 DIR_oilPumpState 1;
BA_ "Confidence" SG_ 917 DIR_oilPumpFluidTQF 1;
BA_ "Confidence" SG_ 917 DIR_oilPumpLeadAngle 1;
BA_ "Confidence" SG_ 917 DIR_oilPumpFlowTarget 1;
BA_ "Confidence" SG_ 917 DIR_oilPumpFlowActual 1;
BA_ "Confidence" SG_ 917 DIR_oilPumpFluidT 1;
BA_ "Confidence" SG_ 917 DIR_oilPumpPhaseCurrent 1;
BA_ "Confidence" SG_ 917 DIR_oilPumpPressureEstimate 1;
BA_ "Confidence" SG_ 917 DIR_oilPumpPressureExpected 1;
BA_ "Confidence" SG_ 917 DIR_oilPumpPressureResidual 1;
BA_ "Confidence" SG_ 614 DIR_elecPower 1;
BA_ "Confidence" SG_ 614 DIR_heatPowerOptimal 1;
BA_ "Confidence" SG_ 614 DIR_heatPowerMax 1;
BA_ "Confidence" SG_ 614 DIR_heatPowerActual 1;
BA_ "Confidence" SG_ 614 DIR_excessHeatCommand 1;
BA_ "Confidence" SG_ 614 DIR_drivePowerMax 1;
BA_ "Confidence" SG_ 598 DIR_state 1;
BA_ "Confidence" SG_ 598 DIR_keepAliveRequest 1;
BA_ "Confidence" SG_ 598 DIR_soptState 1;
BA_ "Confidence" SG_ 598 DIR_adState 1;
BA_ "Confidence" SG_ 598 DIR_driveModeState 1;
BA_ "Confidence" SG_ 598 DIR_lvSupplyV 1;
BA_ "Confidence" SG_ 598 DIR_wasteState 1;
BA_ "Confidence" SG_ 598 DIR_haltRequest 1;
BA_ "Confidence" SG_ 598 DIR_axleSpeedLimitRequest 1;
BA_ "Confidence" SG_ 598 DIR_adDirection 1;
BA_ "Confidence" SG_ 598 DIR_spinDownLearningState 1;
BA_ "Confidence" SG_ 598 DIR_spinDownLearningMode 1;
BA_ "SystemSignalLongSymbol" SG_ 598 DIR_unitRecoveredFromResetAtSpee "DIR_unitRecoveredFromResetAtSpeed";
BA_ "Confidence" SG_ 789 DIR_inverterTQF 1;
BA_ "Confidence" SG_ 789 DIR_pcbT 1;
BA_ "Confidence" SG_ 789 DIR_inverterT 1;
BA_ "Confidence" SG_ 789 DIR_statorT 1;
BA_ "Confidence" SG_ 789 DIR_dcCapT 1;
BA_ "Confidence" SG_ 789 DIR_heatsinkT 1;
BA_ "Confidence" SG_ 789 DIR_inverterTpct 1;
BA_ "Confidence" SG_ 789 DIR_statorTpct 1;
BA_ "Confidence" SG_ 789 DIR_fluidInTemp 1;
BA_ "Confidence" SG_ 789 DIR_normalFetBurnIn 1;
BA_ "Confidence" SG_ 789 DIR_additionalFetBurnIn 1;
BA_ "Confidence" SG_ 789 DIR_currentWeibullMiles 1;
BA_ "Confidence" SG_ 789 DIR_endOfServiceWeibullMiles 1;
BA_ "Confidence" SG_ 789 DIR_burnInDamageRatio 1;
BA_ "Confidence" SG_ 789 DIR_inverterSensorEst 1;
BA_ "Confidence" SG_ 789 DIR_inverterHS1Est 1;
BA_ "Confidence" SG_ 789 DIR_initialBurnInVehicleOdometer 1;
BA_ "Confidence" SG_ 789 DIR_inverterHS2Est 1;
BA_ "Confidence" SG_ 789 DIR_inverterInletEst 1;
BA_ "Confidence" SG_ 1495 DIR_passiveInletTempReq 1;
BA_ "Confidence" SG_ 1495 DIR_activeInletTempReq 1;
BA_ "Confidence" SG_ 1495 DIR_coolantFlowReq 1;
BA_ "Confidence" SG_ 1495 DIR_oilFlowReq 1;
BA_ "Confidence" SG_ 1495 DIR_criticalFlowReq 1;
BA_ "Confidence" SG_ 1495 DIR_burnInStatus 1;
BA_ "Confidence" SG_ 264 DIR_torqueCommand 1;
BA_ "Confidence" SG_ 264 DIR_axleSpeedQF 1;
BA_ "Confidence" SG_ 264 DIR_torqueActual 1;
BA_ "Confidence" SG_ 264 DIR_axleSpeed 1;
BA_ "Confidence" SG_ 264 DIR_axleTorqueQF 1;
BA_ "Confidence" SG_ 264 DIR_axlePowerCalcQF 1;
VAL_ 886 DIF_inverterTQF 3 "INVERTERT_UNKNOWN" 2 "INVERTERT_RATIONAL" 1 "INVERTERT_IRRATIONAL" 0 "INVERTERT_INIT" ;
VAL_ 1367 DIF_criticalFlowReq 1 "ACTIVE" 0 "NOT_ACTIVE" ;
VAL_ 1367 DIF_burnInStatus 5 "COMPLETE" 4 "ACTIVE" 3 "INCOMPLETE" 2 "UNAVAILABLE" 1 "NOT_REQUIRED" 0 "INIT" ;
VAL_ 390 DIF_axleSpeedQF 2 "FAULTED" 1 "VALID" 0 "INVALID" ;
VAL_ 390 DIF_axleTorqueQF 2 "FAULTED" 1 "VALID" 0 "INVALID" ;
VAL_ 390 DIF_axlePowerCalcQF 1 "VALID" 0 "INVALID" ;
VAL_ 633 DIR_hvilStatus 2 "CLOSED" 1 "OPEN" 0 "DISABLED" ;
VAL_ 633 DIR_hvilSupplyState 2 "ACTIVE" 1 "INACTIVE" 0 "NOT_AVAILABLE" ;
VAL_ 633 DIR_vBatQF 1 "QUALIFIED" 0 "NOT_QUALIFIED" ;
VAL_ 633 DIR_powerStageSafeState 3 "PSTG_SAFESTATE_3PS_LOW" 2 "PSTG_SAFESTATE_3PS_HIGH" 1 "PSTG_SAFESTATE_ALL_OFF" 0 "PSTG_SAFESTATE_NONE" ;
VAL_ 633 DIR_fluxState 12 "DI_FLUXSTATE_DISABLED" 11 "DI_FLUXSTATE_MAGNET_FLUX_DETECT" 10 "DI_FLUXSTATE_STATIONARY_WASTE" 9 "DI_FLUXSTATE_FAULT" 7 "DI_FLUXSTATE_VCONTROL" 6 "DI_FLUXSTATE_ICONTROL" 5 "DI_FLUXSTATE_ENABLED" 4 "DI_FLUXSTATE_FLUX_DOWN" 3 "DI_FLUXSTATE_FLUX_UP" 2 "DI_FLUXSTATE_STANDBY" 1 "DI_FLUXSTATE_TEST" 0 "DI_FLUXSTATE_START" ;
VAL_ 633 DIR_gateDriveState 4 "PSTG_GD_STATE_NOT_CONFIGURED" 3 "PSTG_GD_STATE_CONFIGURED" 2 "PSTG_GD_STATE_CONFIGURING" 1 "PSTG_GD_STATE_SELFTEST" 0 "PSTG_GD_STATE_INIT" ;
VAL_ 821 DIR_buildType 4 "INFO_MFG_BUILD" 3 "INFO_TRACEABLE_CI_BUILD" 2 "INFO_LOCAL_BUILD" 1 "INFO_PLATFORM_BUILD" 0 "INFO_UNKNOWN_BUILD" ;
VAL_ 821 DIR_motorType 31 "DI_MOTOR_PM216E" 20 "DI_MOTOR_PM215D_1KV" 18 "DI_MOTOR_IM260E_1KV" 17 "DI_MOTOR_IM260D_1KV" 16 "DI_MOTOR_PM261C" 15 "DI_MOTOR_PM215C_1KV" 14 "DI_MOTOR_IM260C_1KV" 13 "DI_MOTOR_PM215A_1KV" 12 "DI_MOTOR_IM260A_1KV" 11 "DI_MOTOR_IM228HEA" 10 "DI_MOTOR_PM228HEA" 9 "DI_MOTOR_PM275C" 8 "DI_MOTOR_PM291D" 7 "DI_MOTOR_PM291C" 6 "DI_MOTOR_PM228C" 5 "DI_MOTOR_PM350B" 4 "DI_MOTOR_PM275B" 3 "DI_MOTOR_IM130D_AL" 2 "DI_MOTOR_IM130D" 1 "DI_MOTOR_PM216D" 0 "DI_MOTOR_SNA" ;
VAL_ 821 DIR_siliconType 1 "IGBT" 0 "MOSFET" ;
VAL_ 821 DIR_mechSafeStateType 2 "DI_MECH_SAFE_STATE_TYPE_PRESENT" 1 "DI_MECH_SAFE_STATE_TYPE_NONE" 0 "DI_MECH_SAFE_STATE_TYPE_SNA" ;
VAL_ 821 DIR_oilPumpBuildType 4 "INFO_MFG_BUILD" 3 "INFO_TRACEABLE_CI_BUILD" 2 "INFO_LOCAL_BUILD" 1 "INFO_PLATFORM_BUILD" 0 "INFO_UNKNOWN_BUILD" ;
VAL_ 2039 DIR_targetFluxMode 2 "DI_FLUXMODE_FW" 1 "DI_FLUXMODE_FS" 0 "DI_FLUXMODE_OPTIMUM" ;
VAL_ 917 DIR_oilPumpState 7 "OIL_PUMP_SNA" 6 "OIL_PUMP_FAULTED" 2 "OIL_PUMP_COLD_STARTUP" 1 "OIL_PUMP_ENABLE" 0 "OIL_PUMP_STANDBY" ;
VAL_ 917 DIR_oilPumpFluidTQF 1 "OIL_PUMP_FLUIDT_HIGH_CONFIDENCE" 0 "OIL_PUMP_FLUIDT_LOW_CONFIDENCE" ;
VAL_ 598 DIR_state 4 "DI_STATE_ENABLE" 3 "DI_STATE_ABORT" 2 "DI_STATE_FAULT" 1 "DI_STATE_STANDBY" 0 "DI_STATE_UNAVAILABLE" ;
VAL_ 598 DIR_keepAliveRequest 1 "KEEP_ALIVE" 0 "NO_REQUEST" ;
VAL_ 598 DIR_soptState 9 "SOPT_DISABLED" 8 "SOPT_SNA" 7 "SOPT_TEST_FAILED" 6 "SOPT_TEST_SKIPPED" 5 "SOPT_TEST_PASSED" 4 "SOPT_CURRENT_TEST" 3 "SOPT_ASC_TEST" 2 "SOPT_PSTG_BRING_UP_AT_SPEED" 1 "SOPT_PSTG_BRING_UP" 0 "SOPT_INIT" ;
VAL_ 598 DIR_adState 3 "AD_STATE_FAULTED" 2 "AD_STATE_BACKUP" 1 "AD_STATE_NORMAL" 0 "AD_STATE_STARTUP" ;
VAL_ 598 DIR_driveModeState 1 "DM_STATE_DRIVE" 0 "DM_STATE_NONDRIVE" ;
VAL_ 598 DIR_wasteState 3 "DI_WASTE_STATIONARY" 2 "DI_WASTE_ON" 1 "DI_WASTE_AVAILABLE" 0 "DI_WASTE_UNAVAILABLE" ;
VAL_ 598 DIR_haltRequest 2 "DI_HALT_GRACEFUL" 1 "DI_HALT_IMMEDIATE" 0 "DI_HALT_NONE" ;
VAL_ 598 DIR_adDirection 1 "AD_FORWARD" 0 "AD_BACKWARD" ;
VAL_ 598 DIR_spinDownLearningState 9 "SPINDOWN_STATE_DONE" 8 "SPINDOWN_STATE_WRITE" 7 "SPINDOWN_STATE_VERIFY" 6 "SPINDOWN_STATE_CORRECT" 5 "SPINDOWN_STATE_MEASURE" 4 "SPINDOWN_STATE_COAST" 3 "SPINDOWN_STATE_ACCELERATE" 2 "SPINDOWN_STATE_WAIT" 1 "SPINDOWN_STATE_PRECHECK" 0 "SPINDOWN_STATE_INIT" ;
VAL_ 598 DIR_spinDownLearningMode 1 "SPINDOWN_MODE_ON_GROUND" 0 "SPINDOWN_MODE_ON_LIFT" ;
VAL_ 789 DIR_inverterTQF 3 "INVERTERT_UNKNOWN" 2 "INVERTERT_RATIONAL" 1 "INVERTERT_IRRATIONAL" 0 "INVERTERT_INIT" ;
VAL_ 1495 DIR_criticalFlowReq 1 "ACTIVE" 0 "NOT_ACTIVE" ;
VAL_ 1495 DIR_burnInStatus 5 "COMPLETE" 4 "ACTIVE" 3 "INCOMPLETE" 2 "UNAVAILABLE" 1 "NOT_REQUIRED" 0 "INIT" ;
VAL_ 264 DIR_axleSpeedQF 2 "FAULTED" 1 "VALID" 0 "INVALID" ;
VAL_ 264 DIR_axleTorqueQF 2 "FAULTED" 1 "VALID" 0 "INVALID" ;
VAL_ 264 DIR_axlePowerCalcQF 1 "VALID" 0 "INVALID" ;
